// *************************************************************************** *
// *                                                                           *
// *                      Mentor Graphics Corporation                          *
// *                          All rights reserved                              *
// *                                                                           *
// *************************************************************************** *
// *                                                                           *
// * Description:         CANDB File                                           *
// * Generated at:        2020-12-11 06:44:08                                  *
// * System:              SDB20019                                             *
// * Variant:             DC1E                                                 *
// * Network:             BodyExposedCAN                                       *
// *                                                                           *
// *************************************************************************** *
// *                                                                           *
// *             THIS CONFIGURATION MIGHT CONTAIN SOME ERRORS                  *
// *              IF THE INPUT MODEL WAS NOT PROPERLY FORMED!                  *
// *                    Do Not Use this File directly!                         *
// *                                                                           *
// *************************************************************************** *
VERSION "BodyExposedCAN"

NS_ :

BS_:

BU_:  CEM ETC HCML HCMR RCML RCMM RCMR

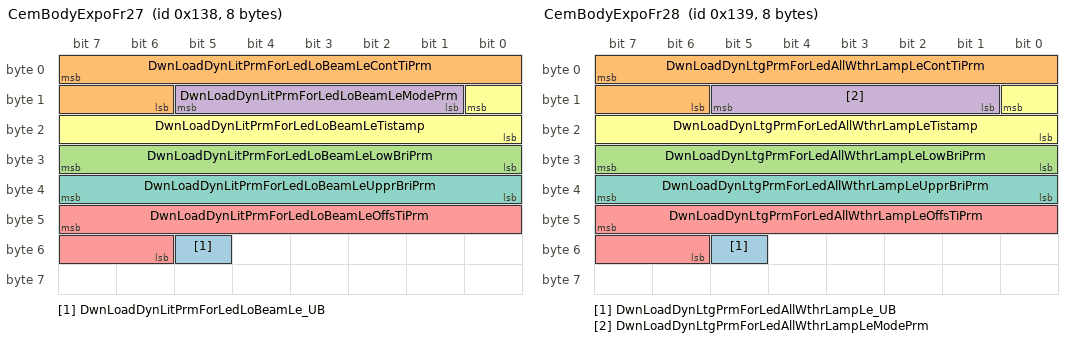
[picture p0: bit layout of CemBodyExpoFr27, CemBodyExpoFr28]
BO_ 312 CemBodyExpoFr27: 8 CEM
 SG_ DwnLoadDynLitPrmForLedLoBeamLe_UB : 53|1@0+ (1,0) [0|1] "" HCML
 SG_ DwnLoadDynLitPrmForLedLoBeamLeContTiPrm : 7|10@0+ (1.0,0.0) [0.0|1000.0] "Milliseconds" HCML
 SG_ DwnLoadDynLitPrmForLedLoBeamLeLowBriPrm : 31|8@0+ (1.0,0.0) [0.0|100.0] "%" HCML
 SG_ DwnLoadDynLitPrmForLedLoBeamLeModePrm : 13|5@0+ (1,0) [0|31] "" HCML
 SG_ DwnLoadDynLitPrmForLedLoBeamLeOffsTiPrm : 47|10@0+ (1.0,0.0) [0.0|1000.0] "Milliseconds" HCML
 SG_ DwnLoadDynLitPrmForLedLoBeamLeTistamp : 8|9@0+ (1.0,0.0) [0.0|511.0] "Unitless" HCML
 SG_ DwnLoadDynLitPrmForLedLoBeamLeUpprBriPrm : 39|8@0+ (1.0,0.0) [0.0|100.0] "%" HCML

BO_ 313 CemBodyExpoFr28: 8 CEM
 SG_ DwnLoadDynLtgPrmForLedAllWthrLampLe_UB : 53|1@0+ (1,0) [0|1] "" HCML
 SG_ DwnLoadDynLtgPrmForLedAllWthrLampLeContTiPrm : 7|10@0+ (1.0,0.0) [0.0|1000.0] "Milliseconds" HCML
 SG_ DwnLoadDynLtgPrmForLedAllWthrLampLeLowBriPrm : 31|8@0+ (1.0,0.0) [0.0|100.0] "%" HCML
 SG_ DwnLoadDynLtgPrmForLedAllWthrLampLeModePrm : 13|5@0+ (1,0) [0|31] "" HCML
 SG_ DwnLoadDynLtgPrmForLedAllWthrLampLeOffsTiPrm : 47|10@0+ (1.0,0.0) [0.0|1000.0] "Milliseconds" HCML
 SG_ DwnLoadDynLtgPrmForLedAllWthrLampLeTistamp : 8|9@0+ (1.0,0.0) [0.0|511.0] "Unitless" HCML
 SG_ DwnLoadDynLtgPrmForLedAllWthrLampLeUpprBriPrm : 39|8@0+ (1.0,0.0) [0.0|100.0] "%" HCML

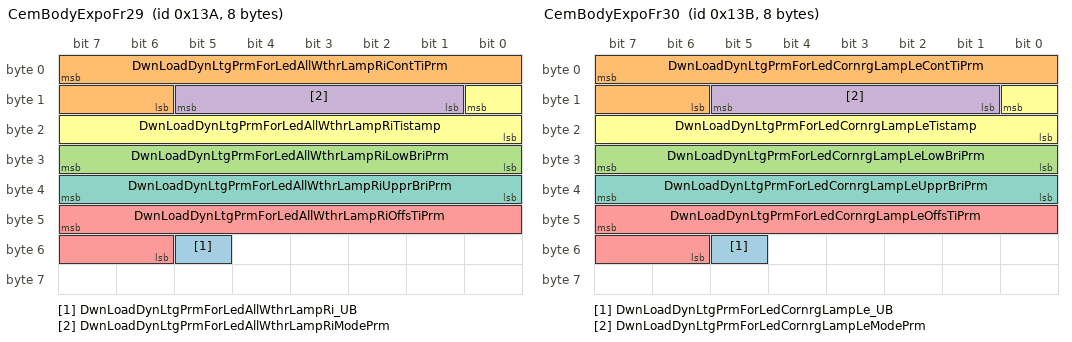
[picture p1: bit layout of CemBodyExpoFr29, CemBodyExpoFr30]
BO_ 314 CemBodyExpoFr29: 8 CEM
 SG_ DwnLoadDynLtgPrmForLedAllWthrLampRi_UB : 53|1@0+ (1,0) [0|1] "" HCMR
 SG_ DwnLoadDynLtgPrmForLedAllWthrLampRiContTiPrm : 7|10@0+ (1.0,0.0) [0.0|1000.0] "Milliseconds" HCMR
 SG_ DwnLoadDynLtgPrmForLedAllWthrLampRiLowBriPrm : 31|8@0+ (1.0,0.0) [0.0|100.0] "%" HCMR
 SG_ DwnLoadDynLtgPrmForLedAllWthrLampRiModePrm : 13|5@0+ (1,0) [0|31] "" HCMR
 SG_ DwnLoadDynLtgPrmForLedAllWthrLampRiOffsTiPrm : 47|10@0+ (1.0,0.0) [0.0|1000.0] "Milliseconds" HCMR
 SG_ DwnLoadDynLtgPrmForLedAllWthrLampRiTistamp : 8|9@0+ (1.0,0.0) [0.0|511.0] "Unitless" HCMR
 SG_ DwnLoadDynLtgPrmForLedAllWthrLampRiUpprBriPrm : 39|8@0+ (1.0,0.0) [0.0|100.0] "%" HCMR

BO_ 315 CemBodyExpoFr30: 8 CEM
 SG_ DwnLoadDynLtgPrmForLedCornrgLampLe_UB : 53|1@0+ (1,0) [0|1] "" HCML
 SG_ DwnLoadDynLtgPrmForLedCornrgLampLeContTiPrm : 7|10@0+ (1.0,0.0) [0.0|1000.0] "Milliseconds" HCML
 SG_ DwnLoadDynLtgPrmForLedCornrgLampLeLowBriPrm : 31|8@0+ (1.0,0.0) [0.0|100.0] "%" HCML
 SG_ DwnLoadDynLtgPrmForLedCornrgLampLeModePrm : 13|5@0+ (1,0) [0|31] "" HCML
 SG_ DwnLoadDynLtgPrmForLedCornrgLampLeOffsTiPrm : 47|10@0+ (1.0,0.0) [0.0|1000.0] "Milliseconds" HCML
 SG_ DwnLoadDynLtgPrmForLedCornrgLampLeTistamp : 8|9@0+ (1.0,0.0) [0.0|511.0] "Unitless" HCML
 SG_ DwnLoadDynLtgPrmForLedCornrgLampLeUpprBriPrm : 39|8@0+ (1.0,0.0) [0.0|100.0] "%" HCML

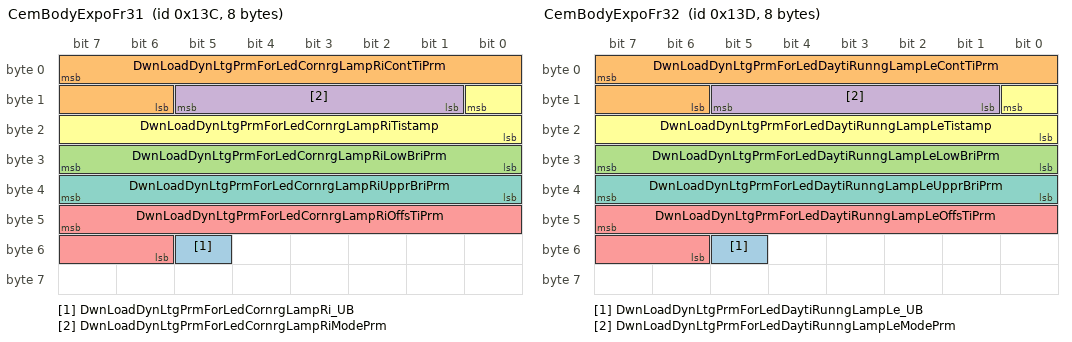
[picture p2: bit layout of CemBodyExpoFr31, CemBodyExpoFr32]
BO_ 316 CemBodyExpoFr31: 8 CEM
 SG_ DwnLoadDynLtgPrmForLedCornrgLampRi_UB : 53|1@0+ (1,0) [0|1] "" HCMR
 SG_ DwnLoadDynLtgPrmForLedCornrgLampRiContTiPrm : 7|10@0+ (1.0,0.0) [0.0|1000.0] "Milliseconds" HCMR
 SG_ DwnLoadDynLtgPrmForLedCornrgLampRiLowBriPrm : 31|8@0+ (1.0,0.0) [0.0|100.0] "%" HCMR
 SG_ DwnLoadDynLtgPrmForLedCornrgLampRiModePrm : 13|5@0+ (1,0) [0|31] "" HCMR
 SG_ DwnLoadDynLtgPrmForLedCornrgLampRiOffsTiPrm : 47|10@0+ (1.0,0.0) [0.0|1000.0] "Milliseconds" HCMR
 SG_ DwnLoadDynLtgPrmForLedCornrgLampRiTistamp : 8|9@0+ (1.0,0.0) [0.0|511.0] "Unitless" HCMR
 SG_ DwnLoadDynLtgPrmForLedCornrgLampRiUpprBriPrm : 39|8@0+ (1.0,0.0) [0.0|100.0] "%" HCMR

BO_ 317 CemBodyExpoFr32: 8 CEM
 SG_ DwnLoadDynLtgPrmForLedDaytiRunngLampLe_UB : 53|1@0+ (1,0) [0|1] "" HCML
 SG_ DwnLoadDynLtgPrmForLedDaytiRunngLampLeContTiPrm : 7|10@0+ (1.0,0.0) [0.0|1000.0] "Milliseconds" HCML
 SG_ DwnLoadDynLtgPrmForLedDaytiRunngLampLeLowBriPrm : 31|8@0+ (1.0,0.0) [0.0|100.0] "%" HCML
 SG_ DwnLoadDynLtgPrmForLedDaytiRunngLampLeModePrm : 13|5@0+ (1,0) [0|31] "" HCML
 SG_ DwnLoadDynLtgPrmForLedDaytiRunngLampLeOffsTiPrm : 47|10@0+ (1.0,0.0) [0.0|1000.0] "Milliseconds" HCML
 SG_ DwnLoadDynLtgPrmForLedDaytiRunngLampLeTistamp : 8|9@0+ (1.0,0.0) [0.0|511.0] "Unitless" HCML
 SG_ DwnLoadDynLtgPrmForLedDaytiRunngLampLeUpprBriPrm : 39|8@0+ (1.0,0.0) [0.0|100.0] "%" HCML

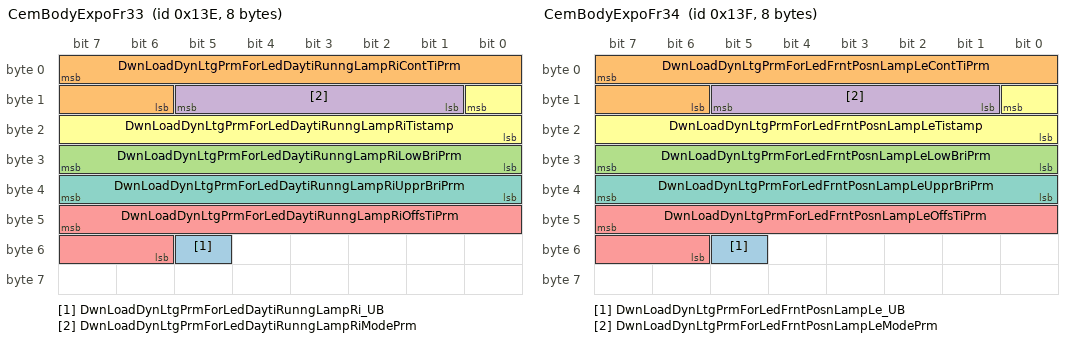
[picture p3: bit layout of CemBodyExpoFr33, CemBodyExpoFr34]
BO_ 318 CemBodyExpoFr33: 8 CEM
 SG_ DwnLoadDynLtgPrmForLedDaytiRunngLampRi_UB : 53|1@0+ (1,0) [0|1] "" HCMR
 SG_ DwnLoadDynLtgPrmForLedDaytiRunngLampRiContTiPrm : 7|10@0+ (1.0,0.0) [0.0|1000.0] "Milliseconds" HCMR
 SG_ DwnLoadDynLtgPrmForLedDaytiRunngLampRiLowBriPrm : 31|8@0+ (1.0,0.0) [0.0|100.0] "%" HCMR
 SG_ DwnLoadDynLtgPrmForLedDaytiRunngLampRiModePrm : 13|5@0+ (1,0) [0|31] "" HCMR
 SG_ DwnLoadDynLtgPrmForLedDaytiRunngLampRiOffsTiPrm : 47|10@0+ (1.0,0.0) [0.0|1000.0] "Milliseconds" HCMR
 SG_ DwnLoadDynLtgPrmForLedDaytiRunngLampRiTistamp : 8|9@0+ (1.0,0.0) [0.0|511.0] "Unitless" HCMR
 SG_ DwnLoadDynLtgPrmForLedDaytiRunngLampRiUpprBriPrm : 39|8@0+ (1.0,0.0) [0.0|100.0] "%" HCMR

BO_ 319 CemBodyExpoFr34: 8 CEM
 SG_ DwnLoadDynLtgPrmForLedFrntPosnLampLe_UB : 53|1@0+ (1,0) [0|1] "" HCML
 SG_ DwnLoadDynLtgPrmForLedFrntPosnLampLeContTiPrm : 7|10@0+ (1.0,0.0) [0.0|1000.0] "Milliseconds" HCML
 SG_ DwnLoadDynLtgPrmForLedFrntPosnLampLeLowBriPrm : 31|8@0+ (1.0,0.0) [0.0|100.0] "%" HCML
 SG_ DwnLoadDynLtgPrmForLedFrntPosnLampLeModePrm : 13|5@0+ (1,0) [0|31] "" HCML
 SG_ DwnLoadDynLtgPrmForLedFrntPosnLampLeOffsTiPrm : 47|10@0+ (1.0,0.0) [0.0|1000.0] "Milliseconds" HCML
 SG_ DwnLoadDynLtgPrmForLedFrntPosnLampLeTistamp : 8|9@0+ (1.0,0.0) [0.0|511.0] "Unitless" HCML
 SG_ DwnLoadDynLtgPrmForLedFrntPosnLampLeUpprBriPrm : 39|8@0+ (1.0,0.0) [0.0|100.0] "%" HCML

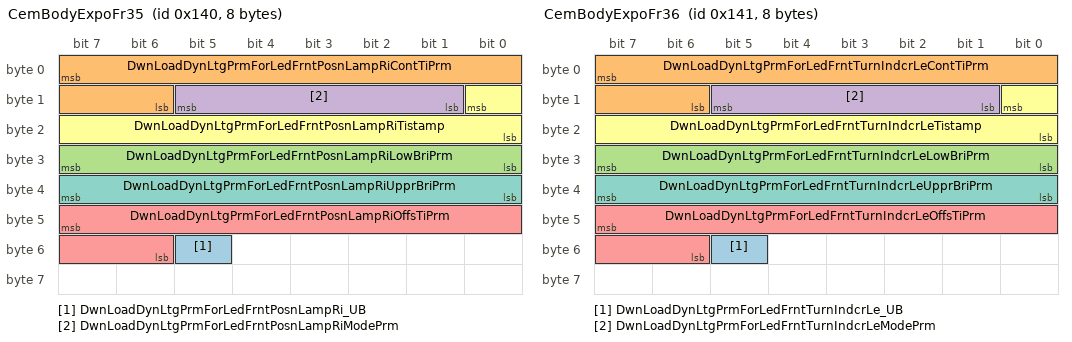
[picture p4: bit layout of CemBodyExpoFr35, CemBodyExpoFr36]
BO_ 320 CemBodyExpoFr35: 8 CEM
 SG_ DwnLoadDynLtgPrmForLedFrntPosnLampRi_UB : 53|1@0+ (1,0) [0|1] "" HCMR
 SG_ DwnLoadDynLtgPrmForLedFrntPosnLampRiContTiPrm : 7|10@0+ (1.0,0.0) [0.0|1000.0] "Milliseconds" HCMR
 SG_ DwnLoadDynLtgPrmForLedFrntPosnLampRiLowBriPrm : 31|8@0+ (1.0,0.0) [0.0|100.0] "%" HCMR
 SG_ DwnLoadDynLtgPrmForLedFrntPosnLampRiModePrm : 13|5@0+ (1,0) [0|31] "" HCMR
 SG_ DwnLoadDynLtgPrmForLedFrntPosnLampRiOffsTiPrm : 47|10@0+ (1.0,0.0) [0.0|1000.0] "Milliseconds" HCMR
 SG_ DwnLoadDynLtgPrmForLedFrntPosnLampRiTistamp : 8|9@0+ (1.0,0.0) [0.0|511.0] "Unitless" HCMR
 SG_ DwnLoadDynLtgPrmForLedFrntPosnLampRiUpprBriPrm : 39|8@0+ (1.0,0.0) [0.0|100.0] "%" HCMR

BO_ 321 CemBodyExpoFr36: 8 CEM
 SG_ DwnLoadDynLtgPrmForLedFrntTurnIndcrLe_UB : 53|1@0+ (1,0) [0|1] "" HCML
 SG_ DwnLoadDynLtgPrmForLedFrntTurnIndcrLeContTiPrm : 7|10@0+ (1.0,0.0) [0.0|1000.0] "Milliseconds" HCML
 SG_ DwnLoadDynLtgPrmForLedFrntTurnIndcrLeLowBriPrm : 31|8@0+ (1.0,0.0) [0.0|100.0] "%" HCML
 SG_ DwnLoadDynLtgPrmForLedFrntTurnIndcrLeModePrm : 13|5@0+ (1,0) [0|31] "" HCML
 SG_ DwnLoadDynLtgPrmForLedFrntTurnIndcrLeOffsTiPrm : 47|10@0+ (1.0,0.0) [0.0|1000.0] "Milliseconds" HCML
 SG_ DwnLoadDynLtgPrmForLedFrntTurnIndcrLeTistamp : 8|9@0+ (1.0,0.0) [0.0|511.0] "Unitless" HCML
 SG_ DwnLoadDynLtgPrmForLedFrntTurnIndcrLeUpprBriPrm : 39|8@0+ (1.0,0.0) [0.0|100.0] "%" HCML

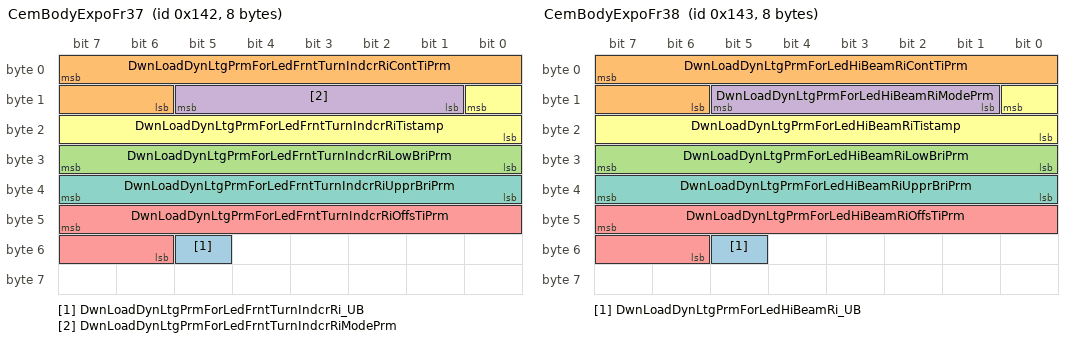
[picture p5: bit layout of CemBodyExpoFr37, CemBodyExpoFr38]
BO_ 322 CemBodyExpoFr37: 8 CEM
 SG_ DwnLoadDynLtgPrmForLedFrntTurnIndcrRi_UB : 53|1@0+ (1,0) [0|1] "" HCMR
 SG_ DwnLoadDynLtgPrmForLedFrntTurnIndcrRiContTiPrm : 7|10@0+ (1.0,0.0) [0.0|1000.0] "Milliseconds" HCMR
 SG_ DwnLoadDynLtgPrmForLedFrntTurnIndcrRiLowBriPrm : 31|8@0+ (1.0,0.0) [0.0|100.0] "%" HCMR
 SG_ DwnLoadDynLtgPrmForLedFrntTurnIndcrRiModePrm : 13|5@0+ (1,0) [0|31] "" HCMR
 SG_ DwnLoadDynLtgPrmForLedFrntTurnIndcrRiOffsTiPrm : 47|10@0+ (1.0,0.0) [0.0|1000.0] "Milliseconds" HCMR
 SG_ DwnLoadDynLtgPrmForLedFrntTurnIndcrRiTistamp : 8|9@0+ (1.0,0.0) [0.0|511.0] "Unitless" HCMR
 SG_ DwnLoadDynLtgPrmForLedFrntTurnIndcrRiUpprBriPrm : 39|8@0+ (1.0,0.0) [0.0|100.0] "%" HCMR

BO_ 323 CemBodyExpoFr38: 8 CEM
 SG_ DwnLoadDynLtgPrmForLedHiBeamRi_UB : 53|1@0+ (1,0) [0|1] "" HCMR
 SG_ DwnLoadDynLtgPrmForLedHiBeamRiContTiPrm : 7|10@0+ (1.0,0.0) [0.0|1000.0] "Milliseconds" HCMR
 SG_ DwnLoadDynLtgPrmForLedHiBeamRiLowBriPrm : 31|8@0+ (1.0,0.0) [0.0|100.0] "%" HCMR
 SG_ DwnLoadDynLtgPrmForLedHiBeamRiModePrm : 13|5@0+ (1,0) [0|31] "" HCMR
 SG_ DwnLoadDynLtgPrmForLedHiBeamRiOffsTiPrm : 47|10@0+ (1.0,0.0) [0.0|1000.0] "Milliseconds" HCMR
 SG_ DwnLoadDynLtgPrmForLedHiBeamRiTistamp : 8|9@0+ (1.0,0.0) [0.0|511.0] "Unitless" HCMR
 SG_ DwnLoadDynLtgPrmForLedHiBeamRiUpprBriPrm : 39|8@0+ (1.0,0.0) [0.0|100.0] "%" HCMR

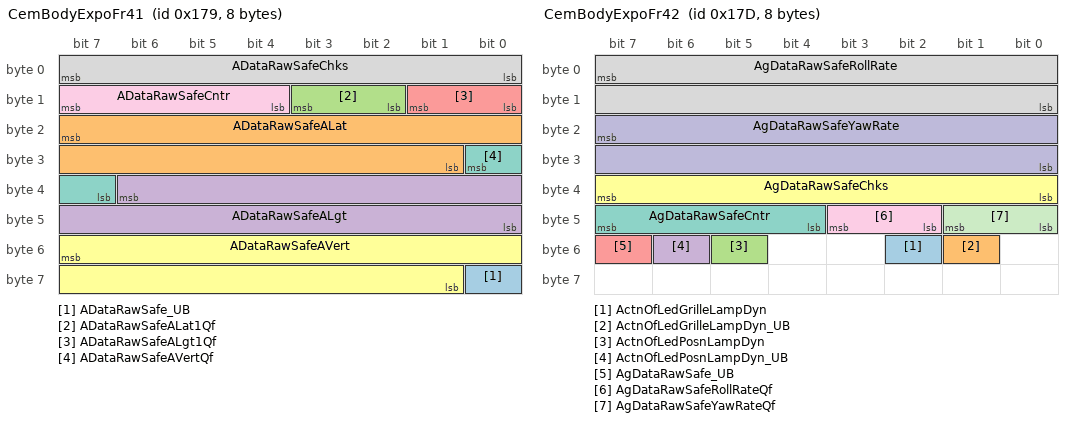
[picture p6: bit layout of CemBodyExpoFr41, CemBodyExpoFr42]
BO_ 377 CemBodyExpoFr41: 8 CEM
 SG_ ADataRawSafe_UB : 56|1@0+ (1,0) [0|1] "" HCML,HCMR
 SG_ ADataRawSafeALat : 23|15@0- (0.0085,0.0) [-138.99200000000002|139.00050000000002] "m/s^2" HCML,HCMR
 SG_ ADataRawSafeALat1Qf : 11|2@0+ (1,0) [0|3] "" HCML,HCMR
 SG_ ADataRawSafeALgt : 38|15@0- (0.0085,0.0) [-138.99200000000002|139.00050000000002] "m/s^2" HCML,HCMR
 SG_ ADataRawSafeALgt1Qf : 9|2@0+ (1,0) [0|3] "" HCML,HCMR
 SG_ ADataRawSafeAVert : 55|15@0- (0.0085,0.0) [-138.99200000000002|139.00050000000002] "m/s^2" HCML,HCMR
 SG_ ADataRawSafeAVertQf : 24|2@0+ (1,0) [0|3] "" HCML,HCMR
 SG_ ADataRawSafeChks : 7|8@0+ (1.0,0.0) [0.0|255.0] "Unitless" HCML,HCMR
 SG_ ADataRawSafeCntr : 15|4@0+ (1.0,0.0) [0.0|15.0] "Unitless" HCML,HCMR

BO_ 381 CemBodyExpoFr42: 8 CEM
 SG_ ActnOfLedGrilleLampDyn : 50|1@0+ (1,0) [0|1] "" HCML,HCMR
 SG_ ActnOfLedGrilleLampDyn_UB : 49|1@0+ (1,0) [0|1] "" HCML,HCMR
 SG_ ActnOfLedPosnLampDyn : 53|1@0+ (1,0) [0|1] "" HCML,HCMR
 SG_ ActnOfLedPosnLampDyn_UB : 54|1@0+ (1,0) [0|1] "" HCML,HCMR
 SG_ AgDataRawSafe_UB : 55|1@0+ (1,0) [0|1] "" HCML,HCMR
 SG_ AgDataRawSafeChks : 39|8@0+ (1.0,0.0) [0.0|255.0] "Unitless" HCML,HCMR
 SG_ AgDataRawSafeCntr : 47|4@0+ (1.0,0.0) [0.0|15.0] "Unitless" HCML,HCMR
 SG_ AgDataRawSafeRollRate : 7|16@0- (0.000244140625,0.0) [-6.0|6.0] "rad/s" HCML,HCMR
 SG_ AgDataRawSafeRollRateQf : 43|2@0+ (1,0) [0|3] "" HCML,HCMR
 SG_ AgDataRawSafeYawRate : 23|16@0- (0.000244140625,0.0) [-6.0|6.0] "rad/s" HCML,HCMR
 SG_ AgDataRawSafeYawRateQf : 41|2@0+ (1,0) [0|3] "" HCML,HCMR

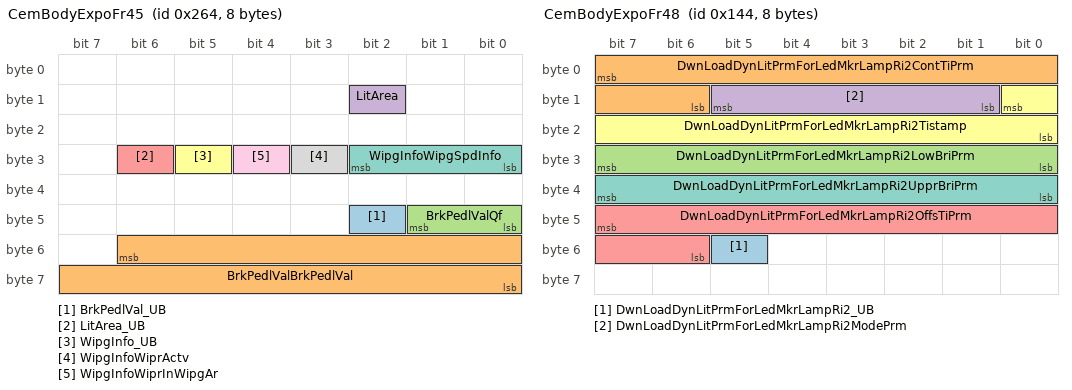
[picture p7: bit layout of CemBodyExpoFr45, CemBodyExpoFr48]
BO_ 612 CemBodyExpoFr45: 8 CEM
 SG_ BrkPedlVal_UB : 42|1@0+ (1,0) [0|1] "" HCML,HCMR
 SG_ BrkPedlValBrkPedlVal : 54|15@0+ (0.00390625,0.0) [0.0|100.0] "%" HCML,HCMR
 SG_ BrkPedlValQf : 41|2@0+ (1,0) [0|3] "" HCML,HCMR
 SG_ LitArea : 10|1@0+ (1,0) [0|1] "" HCML,HCMR
 SG_ LitArea_UB : 30|1@0+ (1,0) [0|1] "" HCML,HCMR
 SG_ WipgInfo_UB : 29|1@0+ (1,0) [0|1] "" HCML,HCMR
 SG_ WipgInfoWipgSpdInfo : 26|3@0+ (1,0) [0|7] "" HCML,HCMR
 SG_ WipgInfoWiprActv : 27|1@0+ (1,0) [0|1] "" HCML,HCMR
 SG_ WipgInfoWiprInWipgAr : 28|1@0+ (1,0) [0|1] "" HCML,HCMR

BO_ 324 CemBodyExpoFr48: 8 CEM
 SG_ DwnLoadDynLitPrmForLedMkrLampRi2_UB : 53|1@0+ (1,0) [0|1] "" RCMM
 SG_ DwnLoadDynLitPrmForLedMkrLampRi2ContTiPrm : 7|10@0+ (1.0,0.0) [0.0|1000.0] "Milliseconds" RCMM
 SG_ DwnLoadDynLitPrmForLedMkrLampRi2LowBriPrm : 31|8@0+ (1.0,0.0) [0.0|100.0] "%" RCMM
 SG_ DwnLoadDynLitPrmForLedMkrLampRi2ModePrm : 13|5@0+ (1,0) [0|31] "" RCMM
 SG_ DwnLoadDynLitPrmForLedMkrLampRi2OffsTiPrm : 47|10@0+ (1.0,0.0) [0.0|1000.0] "Milliseconds" RCMM
 SG_ DwnLoadDynLitPrmForLedMkrLampRi2Tistamp : 8|9@0+ (1.0,0.0) [0.0|511.0] "Unitless" RCMM
 SG_ DwnLoadDynLitPrmForLedMkrLampRi2UpprBriPrm : 39|8@0+ (1.0,0.0) [0.0|100.0] "%" RCMM

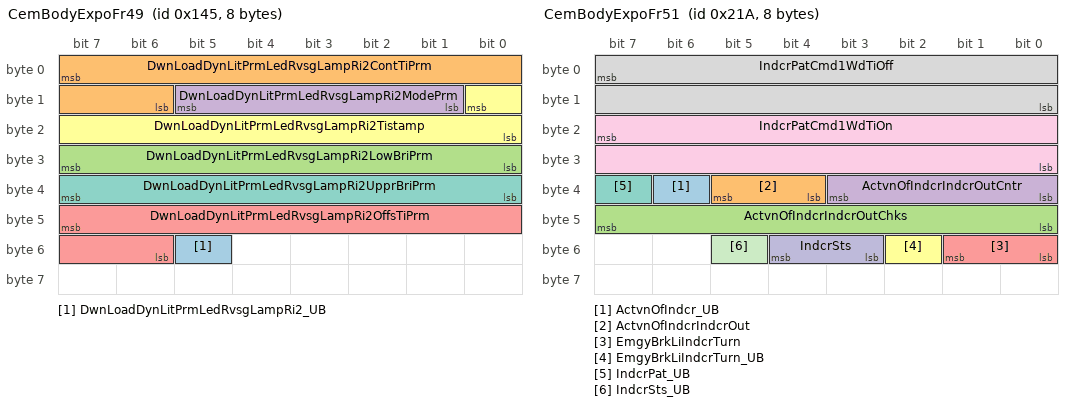
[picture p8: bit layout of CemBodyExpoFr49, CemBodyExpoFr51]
BO_ 325 CemBodyExpoFr49: 8 CEM
 SG_ DwnLoadDynLitPrmLedRvsgLampRi2_UB : 53|1@0+ (1,0) [0|1] "" RCMM
 SG_ DwnLoadDynLitPrmLedRvsgLampRi2ContTiPrm : 7|10@0+ (1.0,0.0) [0.0|1000.0] "Milliseconds" RCMM
 SG_ DwnLoadDynLitPrmLedRvsgLampRi2LowBriPrm : 31|8@0+ (1.0,0.0) [0.0|100.0] "%" RCMM
 SG_ DwnLoadDynLitPrmLedRvsgLampRi2ModePrm : 13|5@0+ (1,0) [0|31] "" RCMM
 SG_ DwnLoadDynLitPrmLedRvsgLampRi2OffsTiPrm : 47|10@0+ (1.0,0.0) [0.0|1000.0] "Milliseconds" RCMM
 SG_ DwnLoadDynLitPrmLedRvsgLampRi2Tistamp : 8|9@0+ (1.0,0.0) [0.0|511.0] "Unitless" RCMM
 SG_ DwnLoadDynLitPrmLedRvsgLampRi2UpprBriPrm : 39|8@0+ (1.0,0.0) [0.0|100.0] "%" RCMM

BO_ 522 CemBodyExpoFr50: 8 CEM
 SG_ ActnOfLedCornrgLampLe : 6|1@0+ (1,0) [0|1] "" HCML
 SG_ ActnOfLedCornrgLampLe_UB : 7|1@0+ (1,0) [0|1] "" HCML
 SG_ ActnOfLedCornrgLampRi : 22|1@0+ (1,0) [0|1] "" HCMR
 SG_ ActnOfLedCornrgLampRi_UB : 23|1@0+ (1,0) [0|1] "" HCMR
 SG_ ActnOfLedDaytiRunngLamp : 32|1@0+ (1,0) [0|1] "" HCML,HCMR
 SG_ ActnOfLedDaytiRunngLamp_UB : 33|1@0+ (1,0) [0|1] "" HCML,HCMR
 SG_ ActnOfLedFrntFogLamp : 34|1@0+ (1,0) [0|1] "" HCML,HCMR
 SG_ ActnOfLedFrntFogLamp_UB : 35|1@0+ (1,0) [0|1] "" HCML,HCMR
 SG_ ActnOfLedHiBeam : 36|1@0+ (1,0) [0|1] "" HCML,HCMR
 SG_ ActnOfLedHiBeam_UB : 37|1@0+ (1,0) [0|1] "" HCML,HCMR
 SG_ ActnOfLedLoBeam_UB : 5|1@0+ (1,0) [0|1] "" HCML,HCMR
 SG_ ActnOfLedLoBeamActnOfLedLoBeam : 4|1@0+ (1,0) [0|1] "" HCML,HCMR
 SG_ ActnOfLedLoBeamChks : 15|8@0+ (1.0,0.0) [0.0|255.0] "Unitless" HCML,HCMR
 SG_ ActnOfLedLoBeamCntr : 3|4@0+ (1.0,0.0) [0.0|15.0] "Unitless" HCML,HCMR
 SG_ ActnOfLedPosnLamp : 38|1@0+ (1,0) [0|1] "" HCML,HCMR,RCML,RCMM,RCMR
 SG_ ActnOfLedPosnLamp_UB : 39|1@0+ (1,0) [0|1] "" HCML,HCMR,RCML,RCMM,RCMR
 SG_ ActnOfLedReFogLamp : 40|1@0+ (1,0) [0|1] "" RCML,RCMM,RCMR
 SG_ ActnOfLedReFogLamp_UB : 41|1@0+ (1,0) [0|1] "" RCML,RCMM,RCMR
 SG_ ActnOfLedRvsgLamp : 42|1@0+ (1,0) [0|1] "" RCML,RCMM,RCMR
 SG_ ActnOfLedRvsgLamp_UB : 43|1@0+ (1,0) [0|1] "" RCML,RCMM,RCMR
 SG_ ActnOfLedStopLamp_UB : 21|1@0+ (1,0) [0|1] "" RCML,RCMM,RCMR
 SG_ ActnOfLedStopLampActnOfLedStopLamp : 20|1@0+ (1,0) [0|1] "" RCML,RCMM,RCMR
 SG_ ActnOfLedStopLampChks : 31|8@0+ (1.0,0.0) [0.0|255.0] "Unitless" RCML,RCMM,RCMR
 SG_ ActnOfLedStopLampCntr : 19|4@0+ (1.0,0.0) [0.0|15.0] "Unitless" RCML,RCMM,RCMR
 SG_ ActvnOfAfs : 44|1@0+ (1,0) [0|1] "" HCML,HCMR
 SG_ ActvnOfAfs_UB : 45|1@0+ (1,0) [0|1] "" HCML,HCMR
 SG_ ActvnOfAhbc : 46|1@0+ (1,0) [0|1] "" HCML,HCMR
 SG_ ActvnOfAhbc_UB : 47|1@0+ (1,0) [0|1] "" HCML,HCMR
 SG_ ActvnOfAhl : 48|1@0+ (1,0) [0|1] "" HCML,HCMR
 SG_ ActvnOfAhl_UB : 49|1@0+ (1,0) [0|1] "" HCML,HCMR
 SG_ ActvnOfBrkLi : 50|1@0+ (1,0) [0|1] "" RCML,RCMR
 SG_ ActvnOfBrkLi_UB : 51|1@0+ (1,0) [0|1] "" RCML,RCMR
 SG_ ActvnOfDbl : 52|1@0+ (1,0) [0|1] "" HCML,HCMR
 SG_ ActvnOfDbl_UB : 53|1@0+ (1,0) [0|1] "" HCML,HCMR
 SG_ ActvnOfGoodByeLi : 54|1@0+ (1,0) [0|1] "" HCML,HCMR,RCML,RCMM,RCMR
 SG_ ActvnOfGoodByeLi_UB : 55|1@0+ (1,0) [0|1] "" HCML,HCMR,RCML,RCMM,RCMR
 SG_ ActvnOfTouristMod : 56|1@0+ (1,0) [0|1] "" HCML,HCMR
 SG_ ActvnOfTouristMod_UB : 57|1@0+ (1,0) [0|1] "" HCML,HCMR
 SG_ ActvnOfWelcomeLi : 58|1@0+ (1,0) [0|1] "" HCML,HCMR,RCML,RCMM,RCMR
 SG_ ActvnOfWelcomeLi_UB : 59|1@0+ (1,0) [0|1] "" HCML,HCMR,RCML,RCMM,RCMR

BO_ 538 CemBodyExpoFr51: 8 CEM
 SG_ ActvnOfIndcr_UB : 38|1@0+ (1,0) [0|1] "" HCML,HCMR,RCML,RCMM,RCMR
 SG_ ActvnOfIndcrIndcrOut : 37|2@0+ (1,0) [0|3] "" HCML,HCMR,RCML,RCMM,RCMR
 SG_ ActvnOfIndcrIndcrOutChks : 47|8@0+ (1.0,0.0) [0.0|255.0] "Unitless" HCML,HCMR,RCML,RCMM,RCMR
 SG_ ActvnOfIndcrIndcrOutCntr : 35|4@0+ (1.0,0.0) [0.0|15.0] "Unitless" HCML,HCMR,RCML,RCMM,RCMR
 SG_ EmgyBrkLiIndcrTurn : 49|2@0+ (1,0) [0|3] "" RCML,RCMM,RCMR
 SG_ EmgyBrkLiIndcrTurn_UB : 50|1@0+ (1,0) [0|1] "" RCML,RCMM,RCMR
 SG_ IndcrPat_UB : 39|1@0+ (1,0) [0|1] "" HCML,HCMR,RCML,RCMM,RCMR
 SG_ IndcrPatCmd1WdTiOff : 7|16@0+ (0.001,0.0) [0.0|65.535] "s" HCML,HCMR,RCML,RCMM,RCMR
 SG_ IndcrPatCmd1WdTiOn : 23|16@0+ (0.001,0.0) [0.0|65.535] "s" HCML,HCMR,RCML,RCMM,RCMR
 SG_ IndcrSts : 52|2@0+ (1,0) [0|3] "" HCML,HCMR,RCML,RCMM,RCMR
 SG_ IndcrSts_UB : 53|1@0+ (1,0) [0|1] "" HCML,HCMR,RCML,RCMM,RCMR

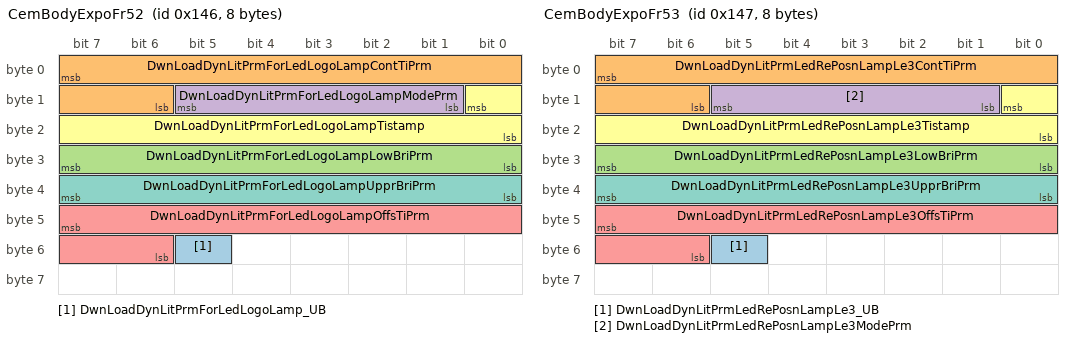
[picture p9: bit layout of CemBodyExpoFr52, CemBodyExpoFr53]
BO_ 326 CemBodyExpoFr52: 8 CEM
 SG_ DwnLoadDynLitPrmForLedLogoLamp_UB : 53|1@0+ (1,0) [0|1] "" RCMM
 SG_ DwnLoadDynLitPrmForLedLogoLampContTiPrm : 7|10@0+ (1.0,0.0) [0.0|1000.0] "Milliseconds" RCMM
 SG_ DwnLoadDynLitPrmForLedLogoLampLowBriPrm : 31|8@0+ (1.0,0.0) [0.0|100.0] "%" RCMM
 SG_ DwnLoadDynLitPrmForLedLogoLampModePrm : 13|5@0+ (1,0) [0|31] "" RCMM
 SG_ DwnLoadDynLitPrmForLedLogoLampOffsTiPrm : 47|10@0+ (1.0,0.0) [0.0|1000.0] "Milliseconds" RCMM
 SG_ DwnLoadDynLitPrmForLedLogoLampTistamp : 8|9@0+ (1.0,0.0) [0.0|511.0] "Unitless" RCMM
 SG_ DwnLoadDynLitPrmForLedLogoLampUpprBriPrm : 39|8@0+ (1.0,0.0) [0.0|100.0] "%" RCMM

BO_ 327 CemBodyExpoFr53: 8 CEM
 SG_ DwnLoadDynLitPrmLedRePosnLampLe3_UB : 53|1@0+ (1,0) [0|1] "" RCML
 SG_ DwnLoadDynLitPrmLedRePosnLampLe3ContTiPrm : 7|10@0+ (1.0,0.0) [0.0|1000.0] "Milliseconds" RCML
 SG_ DwnLoadDynLitPrmLedRePosnLampLe3LowBriPrm : 31|8@0+ (1.0,0.0) [0.0|100.0] "%" RCML
 SG_ DwnLoadDynLitPrmLedRePosnLampLe3ModePrm : 13|5@0+ (1,0) [0|31] "" RCML
 SG_ DwnLoadDynLitPrmLedRePosnLampLe3OffsTiPrm : 47|10@0+ (1.0,0.0) [0.0|1000.0] "Milliseconds" RCML
 SG_ DwnLoadDynLitPrmLedRePosnLampLe3Tistamp : 8|9@0+ (1.0,0.0) [0.0|511.0] "Unitless" RCML
 SG_ DwnLoadDynLitPrmLedRePosnLampLe3UpprBriPrm : 39|8@0+ (1.0,0.0) [0.0|100.0] "%" RCML

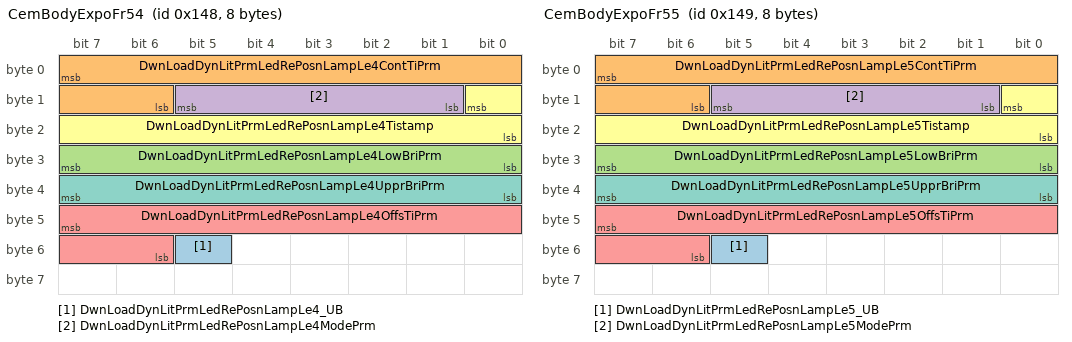
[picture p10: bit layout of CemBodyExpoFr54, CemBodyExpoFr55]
BO_ 328 CemBodyExpoFr54: 8 CEM
 SG_ DwnLoadDynLitPrmLedRePosnLampLe4_UB : 53|1@0+ (1,0) [0|1] "" RCML
 SG_ DwnLoadDynLitPrmLedRePosnLampLe4ContTiPrm : 7|10@0+ (1.0,0.0) [0.0|1000.0] "Milliseconds" RCML
 SG_ DwnLoadDynLitPrmLedRePosnLampLe4LowBriPrm : 31|8@0+ (1.0,0.0) [0.0|100.0] "%" RCML
 SG_ DwnLoadDynLitPrmLedRePosnLampLe4ModePrm : 13|5@0+ (1,0) [0|31] "" RCML
 SG_ DwnLoadDynLitPrmLedRePosnLampLe4OffsTiPrm : 47|10@0+ (1.0,0.0) [0.0|1000.0] "Milliseconds" RCML
 SG_ DwnLoadDynLitPrmLedRePosnLampLe4Tistamp : 8|9@0+ (1.0,0.0) [0.0|511.0] "Unitless" RCML
 SG_ DwnLoadDynLitPrmLedRePosnLampLe4UpprBriPrm : 39|8@0+ (1.0,0.0) [0.0|100.0] "%" RCML

BO_ 329 CemBodyExpoFr55: 8 CEM
 SG_ DwnLoadDynLitPrmLedRePosnLampLe5_UB : 53|1@0+ (1,0) [0|1] "" RCMM
 SG_ DwnLoadDynLitPrmLedRePosnLampLe5ContTiPrm : 7|10@0+ (1.0,0.0) [0.0|1000.0] "Milliseconds" RCMM
 SG_ DwnLoadDynLitPrmLedRePosnLampLe5LowBriPrm : 31|8@0+ (1.0,0.0) [0.0|100.0] "%" RCMM
 SG_ DwnLoadDynLitPrmLedRePosnLampLe5ModePrm : 13|5@0+ (1,0) [0|31] "" RCMM
 SG_ DwnLoadDynLitPrmLedRePosnLampLe5OffsTiPrm : 47|10@0+ (1.0,0.0) [0.0|1000.0] "Milliseconds" RCMM
 SG_ DwnLoadDynLitPrmLedRePosnLampLe5Tistamp : 8|9@0+ (1.0,0.0) [0.0|511.0] "Unitless" RCMM
 SG_ DwnLoadDynLitPrmLedRePosnLampLe5UpprBriPrm : 39|8@0+ (1.0,0.0) [0.0|100.0] "%" RCMM

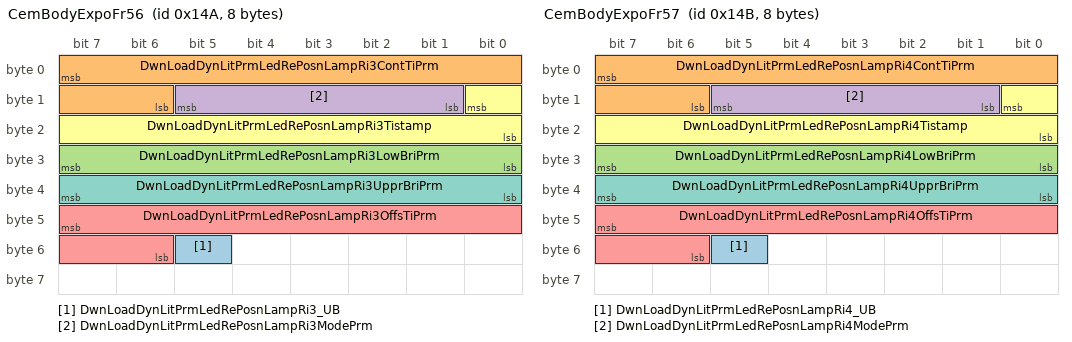
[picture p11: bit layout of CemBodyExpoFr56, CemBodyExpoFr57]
BO_ 330 CemBodyExpoFr56: 8 CEM
 SG_ DwnLoadDynLitPrmLedRePosnLampRi3_UB : 53|1@0+ (1,0) [0|1] "" RCMR
 SG_ DwnLoadDynLitPrmLedRePosnLampRi3ContTiPrm : 7|10@0+ (1.0,0.0) [0.0|1000.0] "Milliseconds" RCMR
 SG_ DwnLoadDynLitPrmLedRePosnLampRi3LowBriPrm : 31|8@0+ (1.0,0.0) [0.0|100.0] "%" RCMR
 SG_ DwnLoadDynLitPrmLedRePosnLampRi3ModePrm : 13|5@0+ (1,0) [0|31] "" RCMR
 SG_ DwnLoadDynLitPrmLedRePosnLampRi3OffsTiPrm : 47|10@0+ (1.0,0.0) [0.0|1000.0] "Milliseconds" RCMR
 SG_ DwnLoadDynLitPrmLedRePosnLampRi3Tistamp : 8|9@0+ (1.0,0.0) [0.0|511.0] "Unitless" RCMR
 SG_ DwnLoadDynLitPrmLedRePosnLampRi3UpprBriPrm : 39|8@0+ (1.0,0.0) [0.0|100.0] "%" RCMR

BO_ 331 CemBodyExpoFr57: 8 CEM
 SG_ DwnLoadDynLitPrmLedRePosnLampRi4_UB : 53|1@0+ (1,0) [0|1] "" RCMR
 SG_ DwnLoadDynLitPrmLedRePosnLampRi4ContTiPrm : 7|10@0+ (1.0,0.0) [0.0|1000.0] "Milliseconds" RCMR
 SG_ DwnLoadDynLitPrmLedRePosnLampRi4LowBriPrm : 31|8@0+ (1.0,0.0) [0.0|100.0] "%" RCMR
 SG_ DwnLoadDynLitPrmLedRePosnLampRi4ModePrm : 13|5@0+ (1,0) [0|31] "" RCMR
 SG_ DwnLoadDynLitPrmLedRePosnLampRi4OffsTiPrm : 47|10@0+ (1.0,0.0) [0.0|1000.0] "Milliseconds" RCMR
 SG_ DwnLoadDynLitPrmLedRePosnLampRi4Tistamp : 8|9@0+ (1.0,0.0) [0.0|511.0] "Unitless" RCMR
 SG_ DwnLoadDynLitPrmLedRePosnLampRi4UpprBriPrm : 39|8@0+ (1.0,0.0) [0.0|100.0] "%" RCMR

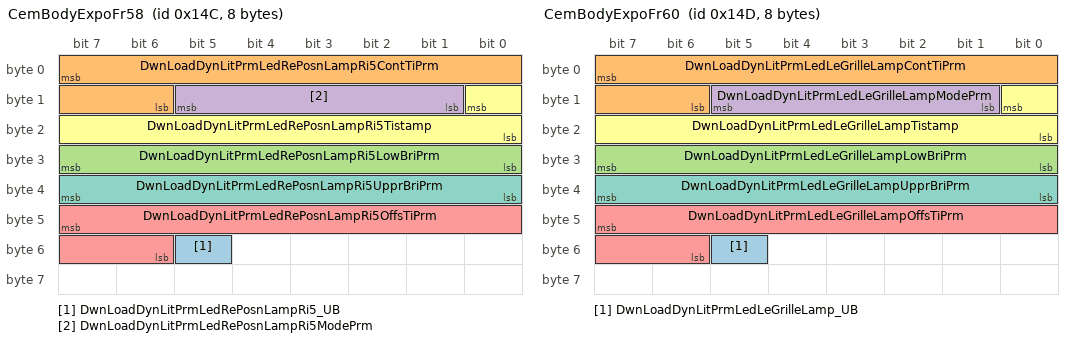
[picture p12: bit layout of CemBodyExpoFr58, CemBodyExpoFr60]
BO_ 332 CemBodyExpoFr58: 8 CEM
 SG_ DwnLoadDynLitPrmLedRePosnLampRi5_UB : 53|1@0+ (1,0) [0|1] "" RCMM
 SG_ DwnLoadDynLitPrmLedRePosnLampRi5ContTiPrm : 7|10@0+ (1.0,0.0) [0.0|1000.0] "Milliseconds" RCMM
 SG_ DwnLoadDynLitPrmLedRePosnLampRi5LowBriPrm : 31|8@0+ (1.0,0.0) [0.0|100.0] "%" RCMM
 SG_ DwnLoadDynLitPrmLedRePosnLampRi5ModePrm : 13|5@0+ (1,0) [0|31] "" RCMM
 SG_ DwnLoadDynLitPrmLedRePosnLampRi5OffsTiPrm : 47|10@0+ (1.0,0.0) [0.0|1000.0] "Milliseconds" RCMM
 SG_ DwnLoadDynLitPrmLedRePosnLampRi5Tistamp : 8|9@0+ (1.0,0.0) [0.0|511.0] "Unitless" RCMM
 SG_ DwnLoadDynLitPrmLedRePosnLampRi5UpprBriPrm : 39|8@0+ (1.0,0.0) [0.0|100.0] "%" RCMM

BO_ 24 CemBodyExpoFr59: 8 CEM
 SG_ WelcomeGoodbyeModeReq : 7|4@0+ (1,0) [0|15] "" HCML,HCMR
 SG_ WelcomeGoodbyeModeReq_UB : 3|1@0+ (1,0) [0|1] "" HCML,HCMR

BO_ 333 CemBodyExpoFr60: 8 CEM
 SG_ DwnLoadDynLitPrmLedLeGrilleLamp_UB : 53|1@0+ (1,0) [0|1] "" HCML
 SG_ DwnLoadDynLitPrmLedLeGrilleLampContTiPrm : 7|10@0+ (1.0,0.0) [0.0|1000.0] "Milliseconds" HCML
 SG_ DwnLoadDynLitPrmLedLeGrilleLampLowBriPrm : 31|8@0+ (1.0,0.0) [0.0|100.0] "%" HCML
 SG_ DwnLoadDynLitPrmLedLeGrilleLampModePrm : 13|5@0+ (1,0) [0|31] "" HCML
 SG_ DwnLoadDynLitPrmLedLeGrilleLampOffsTiPrm : 47|10@0+ (1.0,0.0) [0.0|1000.0] "Milliseconds" HCML
 SG_ DwnLoadDynLitPrmLedLeGrilleLampTistamp : 8|9@0+ (1.0,0.0) [0.0|511.0] "Unitless" HCML
 SG_ DwnLoadDynLitPrmLedLeGrilleLampUpprBriPrm : 39|8@0+ (1.0,0.0) [0.0|100.0] "%" HCML

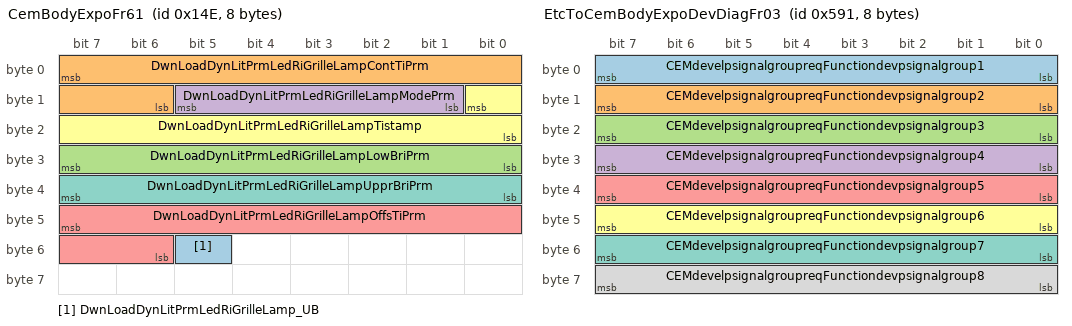
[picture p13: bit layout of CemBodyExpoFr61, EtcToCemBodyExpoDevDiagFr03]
BO_ 334 CemBodyExpoFr61: 8 CEM
 SG_ DwnLoadDynLitPrmLedRiGrilleLamp_UB : 53|1@0+ (1,0) [0|1] "" HCMR
 SG_ DwnLoadDynLitPrmLedRiGrilleLampContTiPrm : 7|10@0+ (1.0,0.0) [0.0|1000.0] "Milliseconds" HCMR
 SG_ DwnLoadDynLitPrmLedRiGrilleLampLowBriPrm : 31|8@0+ (1.0,0.0) [0.0|100.0] "%" HCMR
 SG_ DwnLoadDynLitPrmLedRiGrilleLampModePrm : 13|5@0+ (1,0) [0|31] "" HCMR
 SG_ DwnLoadDynLitPrmLedRiGrilleLampOffsTiPrm : 47|10@0+ (1.0,0.0) [0.0|1000.0] "Milliseconds" HCMR
 SG_ DwnLoadDynLitPrmLedRiGrilleLampTistamp : 8|9@0+ (1.0,0.0) [0.0|511.0] "Unitless" HCMR
 SG_ DwnLoadDynLitPrmLedRiGrilleLampUpprBriPrm : 39|8@0+ (1.0,0.0) [0.0|100.0] "%" HCMR

BO_ 788 CemBodyExpoFr62: 8 CEM
 SG_ DHUcontrolLedMkrLampLe1 : 7|2@0+ (1,0) [0|3] "" RCML,RCMM,RCMR
 SG_ DHUcontrolLedMkrLampLe1_UB : 63|1@0+ (1,0) [0|1] "" RCML,RCMM,RCMR
 SG_ DHUcontrolLedMkrLampLe2 : 5|2@0+ (1,0) [0|3] "" RCML,RCMM,RCMR
 SG_ DHUcontrolLedMkrLampLe2_UB : 62|1@0+ (1,0) [0|1] "" RCML,RCMM,RCMR
 SG_ DHUcontrolLedMkrLampRi1 : 3|2@0+ (1,0) [0|3] "" RCML,RCMM,RCMR
 SG_ DHUcontrolLedMkrLampRi1_UB : 61|1@0+ (1,0) [0|1] "" RCML,RCMM,RCMR
 SG_ DHUcontrolLedMkrLampRi2 : 1|2@0+ (1,0) [0|3] "" RCML,RCMM,RCMR
 SG_ DHUcontrolLedMkrLampRi2_UB : 60|1@0+ (1,0) [0|1] "" RCML,RCMM,RCMR
 SG_ DHUcontrolLedStopLampLe1 : 15|2@0+ (1,0) [0|3] "" RCML,RCMM,RCMR
 SG_ DHUcontrolLedStopLampLe1_UB : 59|1@0+ (1,0) [0|1] "" RCML,RCMM,RCMR
 SG_ DHUcontrolLedStopLampLe2 : 13|2@0+ (1,0) [0|3] "" RCML,RCMM,RCMR
 SG_ DHUcontrolLedStopLampLe2_UB : 58|1@0+ (1,0) [0|1] "" RCML,RCMM,RCMR
 SG_ DHUcontrolLedStopLampRi1 : 11|2@0+ (1,0) [0|3] "" RCML,RCMM,RCMR
 SG_ DHUcontrolLedStopLampRi1_UB : 57|1@0+ (1,0) [0|1] "" RCML,RCMM,RCMR
 SG_ DHUcontrolLedStopLampRi2 : 9|2@0+ (1,0) [0|3] "" RCML,RCMM,RCMR
 SG_ DHUcontrolLedStopLampRi2_UB : 56|1@0+ (1,0) [0|1] "" RCML,RCMM,RCMR
 SG_ DHUcontrolmiddlebrakelight : 23|2@0+ (1,0) [0|3] "" RCML,RCMM,RCMR
 SG_ DHUcontrolmiddlebrakelight_UB : 48|1@0+ (1,0) [0|1] "" RCML,RCMM,RCMR
 SG_ DHUcontrolmiddlecorneringlamp : 21|2@0+ (1,0) [0|3] "" RCML,RCMM,RCMR
 SG_ DHUcontrolmiddlecorneringlamp_UB : 49|1@0+ (1,0) [0|1] "" RCML,RCMM,RCMR
 SG_ DHUcontrolmiddlepositionlight : 19|2@0+ (1,0) [0|3] "" RCML,RCMM,RCMR
 SG_ DHUcontrolmiddlepositionlight_UB : 50|1@0+ (1,0) [0|1] "" RCML,RCMM,RCMR

BO_ 789 CemBodyExpoFr63: 8 CEM
 SG_ DHUcontrolCrossreversinglight : 7|2@0+ (1,0) [0|3] "" RCML,RCMM,RCMR
 SG_ DHUcontrolCrossreversinglight_UB : 63|1@0+ (1,0) [0|1] "" RCML,RCMM,RCMR
 SG_ DHUcontrolleftbrakelightLamp : 5|2@0+ (1,0) [0|3] "" RCML,RCMM,RCMR
 SG_ DHUcontrolleftbrakelightLamp_UB : 62|1@0+ (1,0) [0|1] "" RCML,RCMM,RCMR
 SG_ DHUcontrolleftcorneringlamp : 3|2@0+ (1,0) [0|3] "" RCML,RCMM,RCMR
 SG_ DHUcontrolleftcorneringlamp_UB : 61|1@0+ (1,0) [0|1] "" RCML,RCMM,RCMR
 SG_ DHUcontrolleftdaytimerunninglamp : 1|2@0+ (1,0) [0|3] "" HCML,HCMR
 SG_ DHUcontrolleftdaytimerunninglamp_UB : 60|1@0+ (1,0) [0|1] "" HCML,HCMR
 SG_ DHUcontrolleftfroglight : 15|2@0+ (1,0) [0|3] "" HCML,HCMR
 SG_ DHUcontrolleftfroglight_UB : 59|1@0+ (1,0) [0|1] "" HCML,HCMR
 SG_ DHUcontrolleftheadcorneringlamp : 13|2@0+ (1,0) [0|3] "" HCML,HCMR
 SG_ DHUcontrolleftheadcorneringlamp_UB : 58|1@0+ (1,0) [0|1] "" HCML,HCMR
 SG_ DHUcontrollefthighbeamlamp : 11|2@0+ (1,0) [0|3] "" HCML,HCMR
 SG_ DHUcontrollefthighbeamlamp_UB : 57|1@0+ (1,0) [0|1] "" HCML,HCMR
 SG_ DHUcontrolleftlowbeamlamp : 9|2@0+ (1,0) [0|3] "" HCML,HCMR
 SG_ DHUcontrolleftlowbeamlamp_UB : 56|1@0+ (1,0) [0|1] "" HCML,HCMR
 SG_ DHUcontrolleftpositionlamp : 23|2@0+ (1,0) [0|3] "" HCML,HCMR
 SG_ DHUcontrolleftpositionlamp_UB : 48|1@0+ (1,0) [0|1] "" HCML,HCMR
 SG_ DHUcontrolleftpositionlight : 21|2@0+ (1,0) [0|3] "" RCML,RCMM,RCMR
 SG_ DHUcontrolleftpositionlight_UB : 49|1@0+ (1,0) [0|1] "" RCML,RCMM,RCMR
 SG_ DHUcontrolrightbrakelight : 19|2@0+ (1,0) [0|3] "" RCML,RCMM,RCMR
 SG_ DHUcontrolrightbrakelight_UB : 50|1@0+ (1,0) [0|1] "" RCML,RCMM,RCMR
 SG_ DHUcontrolrightcorneringlamp : 17|2@0+ (1,0) [0|3] "" RCML,RCMM,RCMR
 SG_ DHUcontrolrightcorneringlamp_UB : 51|1@0+ (1,0) [0|1] "" RCML,RCMM,RCMR
 SG_ DHUcontrolrightdaytimerunninglamp : 31|2@0+ (1,0) [0|3] "" HCML,HCMR
 SG_ DHUcontrolrightdaytimerunninglamp_UB : 52|1@0+ (1,0) [0|1] "" HCML,HCMR
 SG_ DHUcontrolrightfroglight : 29|2@0+ (1,0) [0|3] "" HCML,HCMR
 SG_ DHUcontrolrightfroglight_UB : 53|1@0+ (1,0) [0|1] "" HCML,HCMR
 SG_ DHUcontrolrighthighbeamlamp : 27|2@0+ (1,0) [0|3] "" HCML,HCMR
 SG_ DHUcontrolrighthighbeamlamp_UB : 54|1@0+ (1,0) [0|1] "" HCML,HCMR
 SG_ DHUcontrolrightlowbeamlamp : 25|2@0+ (1,0) [0|3] "" HCML,HCMR
 SG_ DHUcontrolrightlowbeamlamp_UB : 55|1@0+ (1,0) [0|1] "" HCML,HCMR
 SG_ DHUcontrolrightpositionLamp : 39|2@0+ (1,0) [0|3] "" RCML,RCMM,RCMR
 SG_ DHUcontrolrightpositionLamp_UB : 40|1@0+ (1,0) [0|1] "" RCML,RCMM,RCMR
 SG_ DHUcontrolrightrearcorneringlamp : 37|2@0+ (1,0) [0|3] "" HCML,HCMR
 SG_ DHUcontrolrightrearcorneringlamp_UB : 32|1@0+ (1,0) [0|1] "" HCML,HCMR
 SG_ DHUcontrolrightrearpositionLamp : 35|2@0+ (1,0) [0|3] "" HCML,HCMR
 SG_ DHUcontrolrightrearpositionLamp_UB : 33|1@0+ (1,0) [0|1] "" HCML,HCMR

BO_ 2047 CemToAllFuncBodyCanExposedDiagReqFrame: 8 CEM
 SG_ CemToAllFuncBodyCanExpDiagReqNpdu : 7|64@0+ (1,0) [0|0] "" HCML, HCMR, RCML, RCMM, RCMR

BO_ 1971 CemToHcmlBodyCanExposedDiagReqFrame: 8 CEM
 SG_ CemToHcmlBodyCanExpDiagReqNpdu : 7|64@0+ (1,0) [0|0] "" HCML

BO_ 1972 CemToHcmrBodyCanExposedDiagReqFrame: 8 CEM
 SG_ CemToHcmrBodyCanExpDiagReqNpdu : 7|64@0+ (1,0) [0|0] "" HCMR

BO_ 1973 CemToRcmlBodyCanExposedDiagReqFrame: 8 CEM
 SG_ CemToRcmlBodyCanExpDiagReqNpdu : 7|64@0+ (1,0) [0|0] "" RCML

BO_ 1975 CemToRcmmBodyCanExposedDiagReqFrame: 8 CEM
 SG_ CemToRcmmBodyCanExpDiagReqNpdu : 7|64@0+ (1,0) [0|0] "" RCMM

BO_ 1974 CemToRcmrBodyCanExposedDiagReqFrame: 8 CEM
 SG_ CemToRcmrBodyCanExpDiagReqNpdu : 7|64@0+ (1,0) [0|0] "" RCMR

BO_ 1425 EtcToCemBodyExpoDevDiagFr03: 8 ETC
 SG_ CEMdevelpsignalgroupreqFunctiondevpsignalgroup1 : 7|8@0+ (1.0,0.0) [0.0|255.0] "Unitless" CEM
 SG_ CEMdevelpsignalgroupreqFunctiondevpsignalgroup2 : 15|8@0+ (1.0,0.0) [0.0|255.0] "Unitless" CEM
 SG_ CEMdevelpsignalgroupreqFunctiondevpsignalgroup3 : 23|8@0+ (1.0,0.0) [0.0|255.0] "Unitless" CEM
 SG_ CEMdevelpsignalgroupreqFunctiondevpsignalgroup4 : 31|8@0+ (1.0,0.0) [0.0|255.0] "Unitless" CEM
 SG_ CEMdevelpsignalgroupreqFunctiondevpsignalgroup5 : 39|8@0+ (1.0,0.0) [0.0|255.0] "Unitless" CEM
 SG_ CEMdevelpsignalgroupreqFunctiondevpsignalgroup6 : 47|8@0+ (1.0,0.0) [0.0|255.0] "Unitless" CEM
 SG_ CEMdevelpsignalgroupreqFunctiondevpsignalgroup7 : 55|8@0+ (1.0,0.0) [0.0|255.0] "Unitless" CEM
 SG_ CEMdevelpsignalgroupreqFunctiondevpsignalgroup8 : 63|8@0+ (1.0,0.0) [0.0|255.0] "Unitless" CEM

BO_ 1430 EtctoHcmlXCPFr01: 8 ETC

BO_ 1428 EtctoHcmrXCPFr01: 8 ETC

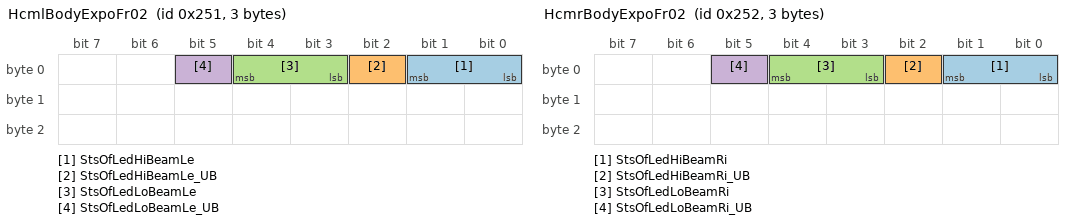
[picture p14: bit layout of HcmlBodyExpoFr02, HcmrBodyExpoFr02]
BO_ 593 HcmlBodyExpoFr02: 3 HCML
 SG_ StsOfLedHiBeamLe : 1|2@0+ (1,0) [0|3] "" CEM
 SG_ StsOfLedHiBeamLe_UB : 2|1@0+ (1,0) [0|1] "" CEM
 SG_ StsOfLedLoBeamLe : 4|2@0+ (1,0) [0|3] "" CEM
 SG_ StsOfLedLoBeamLe_UB : 5|1@0+ (1,0) [0|1] "" CEM

BO_ 124 HcmlBodyExpoFr04: 8 HCML
 SG_ DwnLoadStsFbOfHdlampLe : 5|2@0+ (1,0) [0|3] "" CEM
 SG_ DwnLoadStsFbOfHdlampLe_UB : 39|1@0+ (1,0) [0|1] "" CEM
 SG_ ExtrLiShowActvnFrntLeFb : 28|2@0+ (1,0) [0|3] "" CEM
 SG_ ExtrLiShowActvnFrntLeFb_UB : 20|1@0+ (1,0) [0|1] "" CEM
 SG_ HdlampLeInpSts1 : 49|1@0+ (1,0) [0|1] "" CEM
 SG_ HdlampLeInpSts1_UB : 48|1@0+ (1,0) [0|1] "" CEM
 SG_ HdlampLeInpSts2 : 63|1@0+ (1,0) [0|1] "" CEM
 SG_ HdlampLeInpSts2_UB : 62|1@0+ (1,0) [0|1] "" CEM
 SG_ StsOfAfsLe : 1|2@0+ (1,0) [0|3] "" CEM
 SG_ StsOfAfsLe_UB : 38|1@0+ (1,0) [0|1] "" CEM
 SG_ StsOfAhbcLe : 3|2@0+ (1,0) [0|3] "" CEM
 SG_ StsOfAhbcLe_UB : 37|1@0+ (1,0) [0|1] "" CEM
 SG_ StsOfFrntSideMkrLampLe2 : 9|2@0+ (1,0) [0|3] "" CEM
 SG_ StsOfFrntSideMkrLampLe2_UB : 34|1@0+ (1,0) [0|1] "" CEM
 SG_ StsOfLedCornrgLampLe : 11|2@0+ (1,0) [0|3] "" CEM
 SG_ StsOfLedCornrgLampLe_UB : 33|1@0+ (1,0) [0|1] "" CEM
 SG_ StsOfLedDaytiRunngLampLe : 13|2@0+ (1,0) [0|3] "" CEM
 SG_ StsOfLedDaytiRunngLampLe_UB : 32|1@0+ (1,0) [0|1] "" CEM
 SG_ StsOfLedFrntFogLampLe : 15|2@0+ (1,0) [0|3] "" CEM
 SG_ StsOfLedFrntFogLampLe_UB : 31|1@0+ (1,0) [0|1] "" CEM
 SG_ StsOfLedFrntPosnLampLe : 17|2@0+ (1,0) [0|3] "" CEM
 SG_ StsOfLedFrntPosnLampLe_UB : 30|1@0+ (1,0) [0|1] "" CEM
 SG_ StsOfLedFrntTurnIndcrLe : 19|2@0+ (1,0) [0|3] "" CEM
 SG_ StsOfLedFrntTurnIndcrLe_UB : 29|1@0+ (1,0) [0|1] "" CEM
 SG_ StsOfLvlgLe_UB : 36|1@0+ (1,0) [0|1] "" CEM
 SG_ StsOfLvlgLeChks : 47|8@0+ (1.0,0.0) [0.0|255.0] "Unitless" CEM
 SG_ StsOfLvlgLeCntr : 55|4@0+ (1.0,0.0) [0.0|15.0] "Unitless" CEM
 SG_ StsOfLvlgLeStsOfLvlgLe : 51|2@0+ (1,0) [0|3] "" CEM
 SG_ StsOfSwvlgLe : 7|2@0+ (1,0) [0|3] "" CEM
 SG_ StsOfSwvlgLe_UB : 35|1@0+ (1,0) [0|1] "" CEM
 SG_ StsOfTouristModLe : 25|2@0+ (1,0) [0|3] "" CEM
 SG_ StsOfTouristModLe_UB : 26|1@0+ (1,0) [0|1] "" CEM

BO_ 1329 HcmlBodyExposedNMFr: 8 HCML
 SG_ PNC16_HCML : 16|1@0+ (1,0) [0|0] "" HCMR
 SG_ PNC17_HCML : 17|1@0+ (1,0) [0|0] "" HCMR
 SG_ PNC18_HCML : 18|1@0+ (1,0) [0|0] "" HCMR
 SG_ PNC19_HCML : 19|1@0+ (1,0) [0|0] "" HCMR
 SG_ PNC20_HCML : 20|1@0+ (1,0) [0|0] "" HCMR
 SG_ PNC21_HCML : 21|1@0+ (1,0) [0|0] "" HCMR
 SG_ PNC22_HCML : 22|1@0+ (1,0) [0|0] "" HCMR
 SG_ PNC23_HCML : 23|1@0+ (1,0) [0|0] "" HCMR
 SG_ PNC24_HCML : 24|1@0+ (1,0) [0|0] "" HCMR
 SG_ PNC25_HCML : 25|1@0+ (1,0) [0|0] "" HCMR
 SG_ PNC26_HCML : 26|1@0+ (1,0) [0|0] "" HCMR
 SG_ PNC27_HCML : 27|1@0+ (1,0) [0|0] "" HCMR
 SG_ PNC28_HCML : 28|1@0+ (1,0) [0|0] "" HCMR
 SG_ PNC29_HCML : 29|1@0+ (1,0) [0|0] "" HCMR
 SG_ PNC30_HCML : 30|1@0+ (1,0) [0|0] "" HCMR
 SG_ PNC31_HCML : 31|1@0+ (1,0) [0|0] "" HCMR
 SG_ PNC32_HCML : 32|1@0+ (1,0) [0|0] "" HCMR
 SG_ PNC33_HCML : 33|1@0+ (1,0) [0|0] "" HCMR
 SG_ PNC34_HCML : 34|1@0+ (1,0) [0|0] "" HCMR
 SG_ PNC35_HCML : 35|1@0+ (1,0) [0|0] "" HCMR
 SG_ PNC36_HCML : 36|1@0+ (1,0) [0|0] "" HCMR
 SG_ PNC37_HCML : 37|1@0+ (1,0) [0|0] "" HCMR
 SG_ PNC38_HCML : 38|1@0+ (1,0) [0|0] "" HCMR
 SG_ PNC39_HCML : 39|1@0+ (1,0) [0|0] "" HCMR
 SG_ NM_PNI_HCML : 14|1@0+ (1,0) [0|0] "" HCMR
 SG_ NM_AW_HCML : 12|1@0+ (1,0) [0|0] "" HCMR
 SG_ NM_CS_HCML : 11|1@0+ (1,0) [0|0] "" HCMR
 SG_ NM_RMR_HCML : 8|1@0+ (1,0) [0|0] "" HCMR
 SG_ NM_NodeID_HCML : 7|8@0+ (1,0) [0|0] "" HCMR

BO_ 1715 HcmlToCemBodyCanExposedDiagResFrame: 8 HCML
 SG_ HcmlToCemBodyCanExpDiagResNpdu : 7|64@0+ (1,0) [0|0] "" CEM

BO_ 1424 HcmltoEtcXCPFr01: 8 HCML

BO_ 594 HcmrBodyExpoFr02: 3 HCMR
 SG_ StsOfLedHiBeamRi : 1|2@0+ (1,0) [0|3] "" CEM
 SG_ StsOfLedHiBeamRi_UB : 2|1@0+ (1,0) [0|1] "" CEM
 SG_ StsOfLedLoBeamRi : 4|2@0+ (1,0) [0|3] "" CEM
 SG_ StsOfLedLoBeamRi_UB : 5|1@0+ (1,0) [0|1] "" CEM

BO_ 127 HcmrBodyExpoFr04: 8 HCMR
 SG_ DwnLoadStsFbOfHdlampRi : 5|2@0+ (1,0) [0|3] "" CEM
 SG_ DwnLoadStsFbOfHdlampRi_UB : 39|1@0+ (1,0) [0|1] "" CEM
 SG_ ExtrLiShowActvnFrntRiFb : 28|2@0+ (1,0) [0|3] "" CEM
 SG_ ExtrLiShowActvnFrntRiFb_UB : 20|1@0+ (1,0) [0|1] "" CEM
 SG_ HdlampRiInpSts1 : 49|1@0+ (1,0) [0|1] "" CEM
 SG_ HdlampRiInpSts1_UB : 48|1@0+ (1,0) [0|1] "" CEM
 SG_ HdlampRiInpSts2 : 63|1@0+ (1,0) [0|1] "" CEM
 SG_ HdlampRiInpSts2_UB : 62|1@0+ (1,0) [0|1] "" CEM
 SG_ StsOfAfsRi : 1|2@0+ (1,0) [0|3] "" CEM
 SG_ StsOfAfsRi_UB : 38|1@0+ (1,0) [0|1] "" CEM
 SG_ StsOfAhbcRi : 3|2@0+ (1,0) [0|3] "" CEM
 SG_ StsOfAhbcRi_UB : 37|1@0+ (1,0) [0|1] "" CEM
 SG_ StsOfFrntSideMkrLampRi2 : 9|2@0+ (1,0) [0|3] "" CEM
 SG_ StsOfFrntSideMkrLampRi2_UB : 34|1@0+ (1,0) [0|1] "" CEM
 SG_ StsOfLedCornrgLampRi : 11|2@0+ (1,0) [0|3] "" CEM
 SG_ StsOfLedCornrgLampRi_UB : 33|1@0+ (1,0) [0|1] "" CEM
 SG_ StsOfLedDaytiRunngLampRi : 13|2@0+ (1,0) [0|3] "" CEM
 SG_ StsOfLedDaytiRunngLampRi_UB : 32|1@0+ (1,0) [0|1] "" CEM
 SG_ StsOfLedFrntFogLampRi : 15|2@0+ (1,0) [0|3] "" CEM
 SG_ StsOfLedFrntFogLampRi_UB : 31|1@0+ (1,0) [0|1] "" CEM
 SG_ StsOfLedFrntPosnLampRi : 17|2@0+ (1,0) [0|3] "" CEM
 SG_ StsOfLedFrntPosnLampRi_UB : 30|1@0+ (1,0) [0|1] "" CEM
 SG_ StsOfLedFrntTurnIndcrRi : 19|2@0+ (1,0) [0|3] "" CEM
 SG_ StsOfLedFrntTurnIndcrRi_UB : 29|1@0+ (1,0) [0|1] "" CEM
 SG_ StsOfLvlgRi_UB : 36|1@0+ (1,0) [0|1] "" CEM
 SG_ StsOfLvlgRiChks : 47|8@0+ (1.0,0.0) [0.0|255.0] "Unitless" CEM
 SG_ StsOfLvlgRiCntr : 55|4@0+ (1.0,0.0) [0.0|15.0] "Unitless" CEM
 SG_ StsOfLvlgRiStsOfLvlgRi : 51|2@0+ (1,0) [0|3] "" CEM
 SG_ StsOfSwvlgRi : 7|2@0+ (1,0) [0|3] "" CEM
 SG_ StsOfSwvlgRi_UB : 35|1@0+ (1,0) [0|1] "" CEM
 SG_ StsOfTouristModRi : 25|2@0+ (1,0) [0|3] "" CEM
 SG_ StsOfTouristModRi_UB : 26|1@0+ (1,0) [0|1] "" CEM

BO_ 1330 HcmrBodyExposedNMFr: 8 HCMR
 SG_ PNC16_HCMR : 16|1@0+ (1,0) [0|0] "" CEM
 SG_ PNC17_HCMR : 17|1@0+ (1,0) [0|0] "" CEM
 SG_ PNC18_HCMR : 18|1@0+ (1,0) [0|0] "" CEM
 SG_ PNC19_HCMR : 19|1@0+ (1,0) [0|0] "" CEM
 SG_ PNC20_HCMR : 20|1@0+ (1,0) [0|0] "" CEM
 SG_ PNC21_HCMR : 21|1@0+ (1,0) [0|0] "" CEM
 SG_ PNC22_HCMR : 22|1@0+ (1,0) [0|0] "" CEM
 SG_ PNC23_HCMR : 23|1@0+ (1,0) [0|0] "" CEM
 SG_ PNC24_HCMR : 24|1@0+ (1,0) [0|0] "" CEM
 SG_ PNC25_HCMR : 25|1@0+ (1,0) [0|0] "" CEM
 SG_ PNC26_HCMR : 26|1@0+ (1,0) [0|0] "" CEM
 SG_ PNC27_HCMR : 27|1@0+ (1,0) [0|0] "" CEM
 SG_ PNC28_HCMR : 28|1@0+ (1,0) [0|0] "" CEM
 SG_ PNC29_HCMR : 29|1@0+ (1,0) [0|0] "" CEM
 SG_ PNC30_HCMR : 30|1@0+ (1,0) [0|0] "" CEM
 SG_ PNC31_HCMR : 31|1@0+ (1,0) [0|0] "" CEM
 SG_ PNC32_HCMR : 32|1@0+ (1,0) [0|0] "" CEM
 SG_ PNC33_HCMR : 33|1@0+ (1,0) [0|0] "" CEM
 SG_ PNC34_HCMR : 34|1@0+ (1,0) [0|0] "" CEM
 SG_ PNC35_HCMR : 35|1@0+ (1,0) [0|0] "" CEM
 SG_ PNC36_HCMR : 36|1@0+ (1,0) [0|0] "" CEM
 SG_ PNC37_HCMR : 37|1@0+ (1,0) [0|0] "" CEM
 SG_ PNC38_HCMR : 38|1@0+ (1,0) [0|0] "" CEM
 SG_ PNC39_HCMR : 39|1@0+ (1,0) [0|0] "" CEM
 SG_ NM_PNI_HCMR : 14|1@0+ (1,0) [0|0] "" CEM
 SG_ NM_AW_HCMR : 12|1@0+ (1,0) [0|0] "" CEM
 SG_ NM_CS_HCMR : 11|1@0+ (1,0) [0|0] "" CEM
 SG_ NM_RMR_HCMR : 8|1@0+ (1,0) [0|0] "" CEM
 SG_ NM_NodeID_HCMR : 7|8@0+ (1,0) [0|0] "" CEM

BO_ 1716 HcmrToCemBodyCanExposedDiagResFrame: 8 HCMR
 SG_ HcmrToCemBodyCanExpDiagResNpdu : 7|64@0+ (1,0) [0|0] "" CEM

BO_ 1426 HcmrtoEtcXCPFr01: 8 HCMR

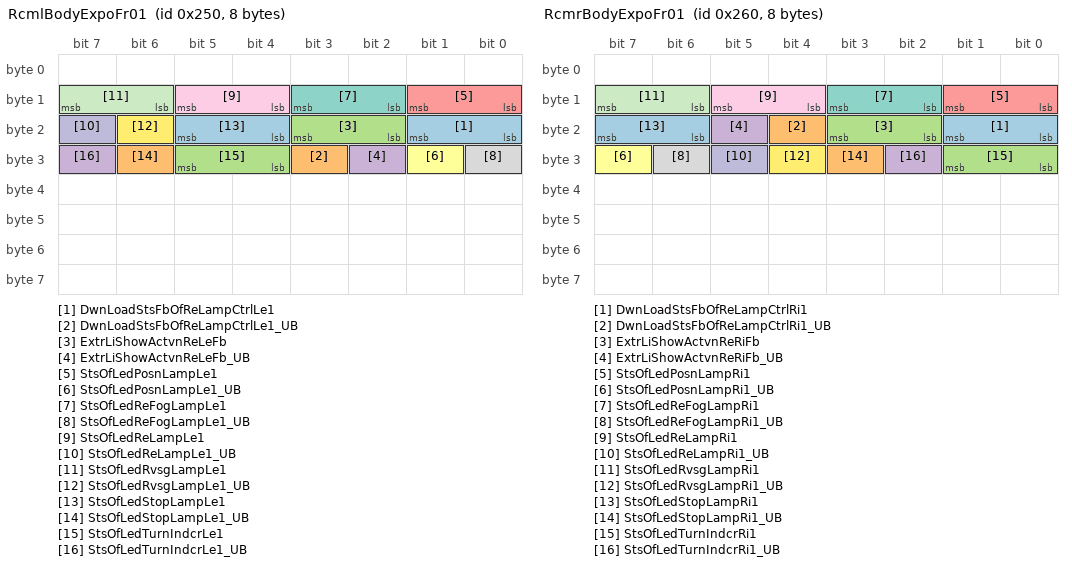
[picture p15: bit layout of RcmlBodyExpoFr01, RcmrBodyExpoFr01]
BO_ 592 RcmlBodyExpoFr01: 8 RCML
 SG_ DwnLoadStsFbOfReLampCtrlLe1 : 17|2@0+ (1,0) [0|3] "" CEM
 SG_ DwnLoadStsFbOfReLampCtrlLe1_UB : 27|1@0+ (1,0) [0|1] "" CEM
 SG_ ExtrLiShowActvnReLeFb : 19|2@0+ (1,0) [0|3] "" CEM
 SG_ ExtrLiShowActvnReLeFb_UB : 26|1@0+ (1,0) [0|1] "" CEM
 SG_ StsOfLedPosnLampLe1 : 9|2@0+ (1,0) [0|3] "" CEM
 SG_ StsOfLedPosnLampLe1_UB : 25|1@0+ (1,0) [0|1] "" CEM
 SG_ StsOfLedReFogLampLe1 : 11|2@0+ (1,0) [0|3] "" CEM
 SG_ StsOfLedReFogLampLe1_UB : 24|1@0+ (1,0) [0|1] "" CEM
 SG_ StsOfLedReLampLe1 : 13|2@0+ (1,0) [0|3] "" CEM
 SG_ StsOfLedReLampLe1_UB : 23|1@0+ (1,0) [0|1] "" CEM
 SG_ StsOfLedRvsgLampLe1 : 15|2@0+ (1,0) [0|3] "" CEM
 SG_ StsOfLedRvsgLampLe1_UB : 22|1@0+ (1,0) [0|1] "" CEM
 SG_ StsOfLedStopLampLe1 : 21|2@0+ (1,0) [0|3] "" CEM
 SG_ StsOfLedStopLampLe1_UB : 30|1@0+ (1,0) [0|1] "" CEM
 SG_ StsOfLedTurnIndcrLe1 : 29|2@0+ (1,0) [0|3] "" CEM
 SG_ StsOfLedTurnIndcrLe1_UB : 31|1@0+ (1,0) [0|1] "" CEM

BO_ 1331 RcmlBodyExposedNMFr: 8 RCML
 SG_ PNC16_RCML : 16|1@0+ (1,0) [0|0] "" HCML
 SG_ PNC17_RCML : 17|1@0+ (1,0) [0|0] "" HCML
 SG_ PNC18_RCML : 18|1@0+ (1,0) [0|0] "" HCML
 SG_ PNC19_RCML : 19|1@0+ (1,0) [0|0] "" HCML
 SG_ PNC20_RCML : 20|1@0+ (1,0) [0|0] "" HCML
 SG_ PNC21_RCML : 21|1@0+ (1,0) [0|0] "" HCML
 SG_ PNC22_RCML : 22|1@0+ (1,0) [0|0] "" HCML
 SG_ PNC23_RCML : 23|1@0+ (1,0) [0|0] "" HCML
 SG_ PNC24_RCML : 24|1@0+ (1,0) [0|0] "" HCML
 SG_ PNC25_RCML : 25|1@0+ (1,0) [0|0] "" HCML
 SG_ PNC26_RCML : 26|1@0+ (1,0) [0|0] "" HCML
 SG_ PNC27_RCML : 27|1@0+ (1,0) [0|0] "" HCML
 SG_ PNC28_RCML : 28|1@0+ (1,0) [0|0] "" HCML
 SG_ PNC29_RCML : 29|1@0+ (1,0) [0|0] "" HCML
 SG_ PNC30_RCML : 30|1@0+ (1,0) [0|0] "" HCML
 SG_ PNC31_RCML : 31|1@0+ (1,0) [0|0] "" HCML
 SG_ PNC32_RCML : 32|1@0+ (1,0) [0|0] "" HCML
 SG_ PNC33_RCML : 33|1@0+ (1,0) [0|0] "" HCML
 SG_ PNC34_RCML : 34|1@0+ (1,0) [0|0] "" HCML
 SG_ PNC35_RCML : 35|1@0+ (1,0) [0|0] "" HCML
 SG_ PNC36_RCML : 36|1@0+ (1,0) [0|0] "" HCML
 SG_ PNC37_RCML : 37|1@0+ (1,0) [0|0] "" HCML
 SG_ PNC38_RCML : 38|1@0+ (1,0) [0|0] "" HCML
 SG_ PNC39_RCML : 39|1@0+ (1,0) [0|0] "" HCML
 SG_ NM_PNI_RCML : 14|1@0+ (1,0) [0|0] "" HCML
 SG_ NM_AW_RCML : 12|1@0+ (1,0) [0|0] "" HCML
 SG_ NM_CS_RCML : 11|1@0+ (1,0) [0|0] "" HCML
 SG_ NM_RMR_RCML : 8|1@0+ (1,0) [0|0] "" HCML
 SG_ NM_NodeID_RCML : 7|8@0+ (1,0) [0|0] "" HCML

BO_ 1717 RcmlToCemBodyCanExposedDiagResFrame: 8 RCML
 SG_ RcmlToCemBodyCanExpDiagResNpdu : 7|64@0+ (1,0) [0|0] "" CEM

BO_ 596 RcmmBodyExpoFr02: 8 RCMM
 SG_ DwnLoadStsFbOfReLampCtrlLe2 : 1|2@0+ (1,0) [0|3] "" CEM
 SG_ DwnLoadStsFbOfReLampCtrlLe2_UB : 47|1@0+ (1,0) [0|1] "" CEM
 SG_ DwnLoadStsFbOfReLampCtrlRi2 : 3|2@0+ (1,0) [0|3] "" CEM
 SG_ DwnLoadStsFbOfReLampCtrlRi2_UB : 46|1@0+ (1,0) [0|1] "" CEM
 SG_ ExtrLiShowActvnReLe2Fb : 5|2@0+ (1,0) [0|3] "" CEM
 SG_ ExtrLiShowActvnReLe2Fb_UB : 45|1@0+ (1,0) [0|1] "" CEM
 SG_ ExtrLiShowActvnReRi2Fb : 7|2@0+ (1,0) [0|3] "" CEM
 SG_ ExtrLiShowActvnReRi2Fb_UB : 44|1@0+ (1,0) [0|1] "" CEM
 SG_ StsOfLedPosnLampLe2 : 9|2@0+ (1,0) [0|3] "" CEM
 SG_ StsOfLedPosnLampLe2_UB : 43|1@0+ (1,0) [0|1] "" CEM
 SG_ StsOfLedPosnLampRi2 : 11|2@0+ (1,0) [0|3] "" CEM
 SG_ StsOfLedPosnLampRi2_UB : 42|1@0+ (1,0) [0|1] "" CEM
 SG_ StsOfLedReFogLampLe2 : 13|2@0+ (1,0) [0|3] "" CEM
 SG_ StsOfLedReFogLampLe2_UB : 41|1@0+ (1,0) [0|1] "" CEM
 SG_ StsOfLedReFogLampRi2 : 15|2@0+ (1,0) [0|3] "" CEM
 SG_ StsOfLedReFogLampRi2_UB : 40|1@0+ (1,0) [0|1] "" CEM
 SG_ StsOfLedReLampLe2 : 17|2@0+ (1,0) [0|3] "" CEM
 SG_ StsOfLedReLampLe2_UB : 39|1@0+ (1,0) [0|1] "" CEM
 SG_ StsOfLedReLampRi2 : 19|2@0+ (1,0) [0|3] "" CEM
 SG_ StsOfLedReLampRi2_UB : 38|1@0+ (1,0) [0|1] "" CEM
 SG_ StsOfLedRvsgLampLe2 : 21|2@0+ (1,0) [0|3] "" CEM
 SG_ StsOfLedRvsgLampLe2_UB : 37|1@0+ (1,0) [0|1] "" CEM
 SG_ StsOfLedRvsgLampRi2 : 23|2@0+ (1,0) [0|3] "" CEM
 SG_ StsOfLedRvsgLampRi2_UB : 36|1@0+ (1,0) [0|1] "" CEM
 SG_ StsOfLedStopLampLe2 : 25|2@0+ (1,0) [0|3] "" CEM
 SG_ StsOfLedStopLampLe2_UB : 35|1@0+ (1,0) [0|1] "" CEM
 SG_ StsOfLedStopLampRi2 : 27|2@0+ (1,0) [0|3] "" CEM
 SG_ StsOfLedStopLampRi2_UB : 34|1@0+ (1,0) [0|1] "" CEM
 SG_ StsOfLedTurnIndcrLe2 : 29|2@0+ (1,0) [0|3] "" CEM
 SG_ StsOfLedTurnIndcrLe2_UB : 33|1@0+ (1,0) [0|1] "" CEM
 SG_ StsOfLedTurnIndcrRi2 : 31|2@0+ (1,0) [0|3] "" CEM
 SG_ StsOfLedTurnIndcrRi2_UB : 32|1@0+ (1,0) [0|1] "" CEM

BO_ 1333 RcmmBodyExposedNMFr: 8 RCMM
 SG_ PNC16_RCMM : 16|1@0+ (1,0) [0|0] "" RCML
 SG_ PNC17_RCMM : 17|1@0+ (1,0) [0|0] "" RCML
 SG_ PNC18_RCMM : 18|1@0+ (1,0) [0|0] "" RCML
 SG_ PNC19_RCMM : 19|1@0+ (1,0) [0|0] "" RCML
 SG_ PNC20_RCMM : 20|1@0+ (1,0) [0|0] "" RCML
 SG_ PNC21_RCMM : 21|1@0+ (1,0) [0|0] "" RCML
 SG_ PNC22_RCMM : 22|1@0+ (1,0) [0|0] "" RCML
 SG_ PNC23_RCMM : 23|1@0+ (1,0) [0|0] "" RCML
 SG_ PNC24_RCMM : 24|1@0+ (1,0) [0|0] "" RCML
 SG_ PNC25_RCMM : 25|1@0+ (1,0) [0|0] "" RCML
 SG_ PNC26_RCMM : 26|1@0+ (1,0) [0|0] "" RCML
 SG_ PNC27_RCMM : 27|1@0+ (1,0) [0|0] "" RCML
 SG_ PNC28_RCMM : 28|1@0+ (1,0) [0|0] "" RCML
 SG_ PNC29_RCMM : 29|1@0+ (1,0) [0|0] "" RCML
 SG_ PNC30_RCMM : 30|1@0+ (1,0) [0|0] "" RCML
 SG_ PNC31_RCMM : 31|1@0+ (1,0) [0|0] "" RCML
 SG_ PNC32_RCMM : 32|1@0+ (1,0) [0|0] "" RCML
 SG_ PNC33_RCMM : 33|1@0+ (1,0) [0|0] "" RCML
 SG_ PNC34_RCMM : 34|1@0+ (1,0) [0|0] "" RCML
 SG_ PNC35_RCMM : 35|1@0+ (1,0) [0|0] "" RCML
 SG_ PNC36_RCMM : 36|1@0+ (1,0) [0|0] "" RCML
 SG_ PNC37_RCMM : 37|1@0+ (1,0) [0|0] "" RCML
 SG_ PNC38_RCMM : 38|1@0+ (1,0) [0|0] "" RCML
 SG_ PNC39_RCMM : 39|1@0+ (1,0) [0|0] "" RCML
 SG_ NM_PNI_RCMM : 14|1@0+ (1,0) [0|0] "" RCML
 SG_ NM_AW_RCMM : 12|1@0+ (1,0) [0|0] "" RCML
 SG_ NM_CS_RCMM : 11|1@0+ (1,0) [0|0] "" RCML
 SG_ NM_RMR_RCMM : 8|1@0+ (1,0) [0|0] "" RCML
 SG_ NM_NodeID_RCMM : 7|8@0+ (1,0) [0|0] "" RCML

BO_ 1719 RcmmToCemBodyCanExposedDiagResFrame: 8 RCMM
 SG_ RcmmToCemBodyCanExpDiagResNpdu : 7|64@0+ (1,0) [0|0] "" CEM

BO_ 608 RcmrBodyExpoFr01: 8 RCMR
 SG_ DwnLoadStsFbOfReLampCtrlRi1 : 17|2@0+ (1,0) [0|3] "" CEM
 SG_ DwnLoadStsFbOfReLampCtrlRi1_UB : 20|1@0+ (1,0) [0|1] "" CEM
 SG_ ExtrLiShowActvnReRiFb : 19|2@0+ (1,0) [0|3] "" CEM
 SG_ ExtrLiShowActvnReRiFb_UB : 21|1@0+ (1,0) [0|1] "" CEM
 SG_ StsOfLedPosnLampRi1 : 9|2@0+ (1,0) [0|3] "" CEM
 SG_ StsOfLedPosnLampRi1_UB : 31|1@0+ (1,0) [0|1] "" CEM
 SG_ StsOfLedReFogLampRi1 : 11|2@0+ (1,0) [0|3] "" CEM
 SG_ StsOfLedReFogLampRi1_UB : 30|1@0+ (1,0) [0|1] "" CEM
 SG_ StsOfLedReLampRi1 : 13|2@0+ (1,0) [0|3] "" CEM
 SG_ StsOfLedReLampRi1_UB : 29|1@0+ (1,0) [0|1] "" CEM
 SG_ StsOfLedRvsgLampRi1 : 15|2@0+ (1,0) [0|3] "" CEM
 SG_ StsOfLedRvsgLampRi1_UB : 28|1@0+ (1,0) [0|1] "" CEM
 SG_ StsOfLedStopLampRi1 : 23|2@0+ (1,0) [0|3] "" CEM
 SG_ StsOfLedStopLampRi1_UB : 27|1@0+ (1,0) [0|1] "" CEM
 SG_ StsOfLedTurnIndcrRi1 : 25|2@0+ (1,0) [0|3] "" CEM
 SG_ StsOfLedTurnIndcrRi1_UB : 26|1@0+ (1,0) [0|1] "" CEM

BO_ 1332 RcmrBodyExposedNMFr: 8 RCMR
 SG_ PNC16_RCMR : 16|1@0+ (1,0) [0|0] "" RCMM
 SG_ PNC17_RCMR : 17|1@0+ (1,0) [0|0] "" RCMM
 SG_ PNC18_RCMR : 18|1@0+ (1,0) [0|0] "" RCMM
 SG_ PNC19_RCMR : 19|1@0+ (1,0) [0|0] "" RCMM
 SG_ PNC20_RCMR : 20|1@0+ (1,0) [0|0] "" RCMM
 SG_ PNC21_RCMR : 21|1@0+ (1,0) [0|0] "" RCMM
 SG_ PNC22_RCMR : 22|1@0+ (1,0) [0|0] "" RCMM
 SG_ PNC23_RCMR : 23|1@0+ (1,0) [0|0] "" RCMM
 SG_ PNC24_RCMR : 24|1@0+ (1,0) [0|0] "" RCMM
 SG_ PNC25_RCMR : 25|1@0+ (1,0) [0|0] "" RCMM
 SG_ PNC26_RCMR : 26|1@0+ (1,0) [0|0] "" RCMM
 SG_ PNC27_RCMR : 27|1@0+ (1,0) [0|0] "" RCMM
 SG_ PNC28_RCMR : 28|1@0+ (1,0) [0|0] "" RCMM
 SG_ PNC29_RCMR : 29|1@0+ (1,0) [0|0] "" RCMM
 SG_ PNC30_RCMR : 30|1@0+ (1,0) [0|0] "" RCMM
 SG_ PNC31_RCMR : 31|1@0+ (1,0) [0|0] "" RCMM
 SG_ PNC32_RCMR : 32|1@0+ (1,0) [0|0] "" RCMM
 SG_ PNC33_RCMR : 33|1@0+ (1,0) [0|0] "" RCMM
 SG_ PNC34_RCMR : 34|1@0+ (1,0) [0|0] "" RCMM
 SG_ PNC35_RCMR : 35|1@0+ (1,0) [0|0] "" RCMM
 SG_ PNC36_RCMR : 36|1@0+ (1,0) [0|0] "" RCMM
 SG_ PNC37_RCMR : 37|1@0+ (1,0) [0|0] "" RCMM
 SG_ PNC38_RCMR : 38|1@0+ (1,0) [0|0] "" RCMM
 SG_ PNC39_RCMR : 39|1@0+ (1,0) [0|0] "" RCMM
 SG_ NM_PNI_RCMR : 14|1@0+ (1,0) [0|0] "" RCMM
 SG_ NM_AW_RCMR : 12|1@0+ (1,0) [0|0] "" RCMM
 SG_ NM_CS_RCMR : 11|1@0+ (1,0) [0|0] "" RCMM
 SG_ NM_RMR_RCMR : 8|1@0+ (1,0) [0|0] "" RCMM
 SG_ NM_NodeID_RCMR : 7|8@0+ (1,0) [0|0] "" RCMM

BO_ 1718 RcmrToCemBodyCanExposedDiagResFrame: 8 RCMR
 SG_ RcmrToCemBodyCanExpDiagResNpdu : 7|64@0+ (1,0) [0|0] "" CEM

CM_ SG_ 312 DwnLoadDynLitPrmForLedLoBeamLeContTiPrm "Light Show Continue Time Parameter 1";
CM_ SG_ 312 DwnLoadDynLitPrmForLedLoBeamLeLowBriPrm "Light Show Lower Brightness Parameter 1";
CM_ SG_ 312 DwnLoadDynLitPrmForLedLoBeamLeModePrm "Light Show Mode Parameter 1";
CM_ SG_ 312 DwnLoadDynLitPrmForLedLoBeamLeOffsTiPrm "Light Show Offset Time Parameter 1";
CM_ SG_ 312 DwnLoadDynLitPrmForLedLoBeamLeTistamp "Light Show time stamp";
CM_ SG_ 312 DwnLoadDynLitPrmForLedLoBeamLeUpprBriPrm "Light Show Upper Brightness Parameter 1";
CM_ SG_ 313 DwnLoadDynLtgPrmForLedAllWthrLampLeContTiPrm "Light Show Continue Time Parameter 1";
CM_ SG_ 313 DwnLoadDynLtgPrmForLedAllWthrLampLeLowBriPrm "Light Show Lower Brightness Parameter 1";
CM_ SG_ 313 DwnLoadDynLtgPrmForLedAllWthrLampLeModePrm "Light Show Mode Parameter 1";
CM_ SG_ 313 DwnLoadDynLtgPrmForLedAllWthrLampLeOffsTiPrm "Light Show Offset Time Parameter 1";
CM_ SG_ 313 DwnLoadDynLtgPrmForLedAllWthrLampLeTistamp "Light Show time stamp";
CM_ SG_ 313 DwnLoadDynLtgPrmForLedAllWthrLampLeUpprBriPrm "Light Show Upper Brightness Parameter 1";
CM_ SG_ 314 DwnLoadDynLtgPrmForLedAllWthrLampRiContTiPrm "Light Show Continue Time Parameter 1";
CM_ SG_ 314 DwnLoadDynLtgPrmForLedAllWthrLampRiLowBriPrm "Light Show Lower Brightness Parameter 1";
CM_ SG_ 314 DwnLoadDynLtgPrmForLedAllWthrLampRiModePrm "Light Show Mode Parameter 1";
CM_ SG_ 314 DwnLoadDynLtgPrmForLedAllWthrLampRiOffsTiPrm "Light Show Offset Time Parameter 1";
CM_ SG_ 314 DwnLoadDynLtgPrmForLedAllWthrLampRiTistamp "Light Show time stamp";
CM_ SG_ 314 DwnLoadDynLtgPrmForLedAllWthrLampRiUpprBriPrm "Light Show Upper Brightness Parameter 1";
CM_ SG_ 315 DwnLoadDynLtgPrmForLedCornrgLampLeContTiPrm "Light Show Continue Time Parameter 1";
CM_ SG_ 315 DwnLoadDynLtgPrmForLedCornrgLampLeLowBriPrm "Light Show Lower Brightness Parameter 1";
CM_ SG_ 315 DwnLoadDynLtgPrmForLedCornrgLampLeModePrm "Light Show Mode Parameter 1";
CM_ SG_ 315 DwnLoadDynLtgPrmForLedCornrgLampLeOffsTiPrm "Light Show Offset Time Parameter 1";
CM_ SG_ 315 DwnLoadDynLtgPrmForLedCornrgLampLeTistamp "Light Show time stamp";
CM_ SG_ 315 DwnLoadDynLtgPrmForLedCornrgLampLeUpprBriPrm "Light Show Upper Brightness Parameter 1";
CM_ SG_ 316 DwnLoadDynLtgPrmForLedCornrgLampRiContTiPrm "Light Show Continue Time Parameter 1";
CM_ SG_ 316 DwnLoadDynLtgPrmForLedCornrgLampRiLowBriPrm "Light Show Lower Brightness Parameter 1";
CM_ SG_ 316 DwnLoadDynLtgPrmForLedCornrgLampRiModePrm "Light Show Mode Parameter 1";
CM_ SG_ 316 DwnLoadDynLtgPrmForLedCornrgLampRiOffsTiPrm "Light Show Offset Time Parameter 1";
CM_ SG_ 316 DwnLoadDynLtgPrmForLedCornrgLampRiTistamp "Light Show time stamp";
CM_ SG_ 316 DwnLoadDynLtgPrmForLedCornrgLampRiUpprBriPrm "Light Show Upper Brightness Parameter 1";
CM_ SG_ 317 DwnLoadDynLtgPrmForLedDaytiRunngLampLeContTiPrm "Light Show Continue Time Parameter 1";
CM_ SG_ 317 DwnLoadDynLtgPrmForLedDaytiRunngLampLeLowBriPrm "Light Show Lower Brightness Parameter 1";
CM_ SG_ 317 DwnLoadDynLtgPrmForLedDaytiRunngLampLeModePrm "Light Show Mode Parameter 1";
CM_ SG_ 317 DwnLoadDynLtgPrmForLedDaytiRunngLampLeOffsTiPrm "Light Show Offset Time Parameter 1";
CM_ SG_ 317 DwnLoadDynLtgPrmForLedDaytiRunngLampLeTistamp "Light Show time stamp";
CM_ SG_ 317 DwnLoadDynLtgPrmForLedDaytiRunngLampLeUpprBriPrm "Light Show Upper Brightness Parameter 1";
CM_ SG_ 318 DwnLoadDynLtgPrmForLedDaytiRunngLampRiContTiPrm "Light Show Continue Time Parameter 1";
CM_ SG_ 318 DwnLoadDynLtgPrmForLedDaytiRunngLampRiLowBriPrm "Light Show Lower Brightness Parameter 1";
CM_ SG_ 318 DwnLoadDynLtgPrmForLedDaytiRunngLampRiModePrm "Light Show Mode Parameter 1";
CM_ SG_ 318 DwnLoadDynLtgPrmForLedDaytiRunngLampRiOffsTiPrm "Light Show Offset Time Parameter 1";
CM_ SG_ 318 DwnLoadDynLtgPrmForLedDaytiRunngLampRiTistamp "Light Show time stamp";
CM_ SG_ 318 DwnLoadDynLtgPrmForLedDaytiRunngLampRiUpprBriPrm "Light Show Upper Brightness Parameter 1";
CM_ SG_ 319 DwnLoadDynLtgPrmForLedFrntPosnLampLeContTiPrm "Light Show Continue Time Parameter 1";
CM_ SG_ 319 DwnLoadDynLtgPrmForLedFrntPosnLampLeLowBriPrm "Light Show Lower Brightness Parameter 1";
CM_ SG_ 319 DwnLoadDynLtgPrmForLedFrntPosnLampLeModePrm "Light Show Mode Parameter 1";
CM_ SG_ 319 DwnLoadDynLtgPrmForLedFrntPosnLampLeOffsTiPrm "Light Show Offset Time Parameter 1";
CM_ SG_ 319 DwnLoadDynLtgPrmForLedFrntPosnLampLeTistamp "Light Show time stamp";
CM_ SG_ 319 DwnLoadDynLtgPrmForLedFrntPosnLampLeUpprBriPrm "Light Show Upper Brightness Parameter 1";
CM_ SG_ 320 DwnLoadDynLtgPrmForLedFrntPosnLampRiContTiPrm "Light Show Continue Time Parameter 1";
CM_ SG_ 320 DwnLoadDynLtgPrmForLedFrntPosnLampRiLowBriPrm "Light Show Lower Brightness Parameter 1";
CM_ SG_ 320 DwnLoadDynLtgPrmForLedFrntPosnLampRiModePrm "Light Show Mode Parameter 1";
CM_ SG_ 320 DwnLoadDynLtgPrmForLedFrntPosnLampRiOffsTiPrm "Light Show Offset Time Parameter 1";
CM_ SG_ 320 DwnLoadDynLtgPrmForLedFrntPosnLampRiTistamp "Light Show time stamp";
CM_ SG_ 320 DwnLoadDynLtgPrmForLedFrntPosnLampRiUpprBriPrm "Light Show Upper Brightness Parameter 1";
CM_ SG_ 321 DwnLoadDynLtgPrmForLedFrntTurnIndcrLeContTiPrm "Light Show Continue Time Parameter 1";
CM_ SG_ 321 DwnLoadDynLtgPrmForLedFrntTurnIndcrLeLowBriPrm "Light Show Lower Brightness Parameter 1";
CM_ SG_ 321 DwnLoadDynLtgPrmForLedFrntTurnIndcrLeModePrm "Light Show Mode Parameter 1";
CM_ SG_ 321 DwnLoadDynLtgPrmForLedFrntTurnIndcrLeOffsTiPrm "Light Show Offset Time Parameter 1";
CM_ SG_ 321 DwnLoadDynLtgPrmForLedFrntTurnIndcrLeTistamp "Light Show time stamp";
CM_ SG_ 321 DwnLoadDynLtgPrmForLedFrntTurnIndcrLeUpprBriPrm "Light Show Upper Brightness Parameter 1";
CM_ SG_ 322 DwnLoadDynLtgPrmForLedFrntTurnIndcrRiContTiPrm "Light Show Continue Time Parameter 1";
CM_ SG_ 322 DwnLoadDynLtgPrmForLedFrntTurnIndcrRiLowBriPrm "Light Show Lower Brightness Parameter 1";
CM_ SG_ 322 DwnLoadDynLtgPrmForLedFrntTurnIndcrRiModePrm "Light Show Mode Parameter 1";
CM_ SG_ 322 DwnLoadDynLtgPrmForLedFrntTurnIndcrRiOffsTiPrm "Light Show Offset Time Parameter 1";
CM_ SG_ 322 DwnLoadDynLtgPrmForLedFrntTurnIndcrRiTistamp "Light Show time stamp";
CM_ SG_ 322 DwnLoadDynLtgPrmForLedFrntTurnIndcrRiUpprBriPrm "Light Show Upper Brightness Parameter 1";
CM_ SG_ 323 DwnLoadDynLtgPrmForLedHiBeamRiContTiPrm "Light Show Continue Time Parameter 1";
CM_ SG_ 323 DwnLoadDynLtgPrmForLedHiBeamRiLowBriPrm "Light Show Lower Brightness Parameter 1";
CM_ SG_ 323 DwnLoadDynLtgPrmForLedHiBeamRiModePrm "Light Show Mode Parameter 1";
CM_ SG_ 323 DwnLoadDynLtgPrmForLedHiBeamRiOffsTiPrm "Light Show Offset Time Parameter 1";
CM_ SG_ 323 DwnLoadDynLtgPrmForLedHiBeamRiTistamp "Light Show time stamp";
CM_ SG_ 323 DwnLoadDynLtgPrmForLedHiBeamRiUpprBriPrm "Light Show Upper Brightness Parameter 1";
CM_ SG_ 377 ADataRawSafeALat "IMU acceleration data Lateral acceleration";
CM_ SG_ 377 ADataRawSafeALat1Qf "IMU acceleration data Quality factor for Lateral acceleration signal";
CM_ SG_ 377 ADataRawSafeALgt "IMU acceleration data Longitudinal acceleration";
CM_ SG_ 377 ADataRawSafeALgt1Qf "IMU acceleration data Quality factor for Longitudinal acceleration";
CM_ SG_ 377 ADataRawSafeAVert "IMU acceleration data Vertical acceleration";
CM_ SG_ 377 ADataRawSafeAVertQf "IMU acceleration data Quality factor for Vertical acceleration";
CM_ SG_ 377 ADataRawSafeChks "IMU acceleration data Check sum";
CM_ SG_ 377 ADataRawSafeCntr "IMU acceleration data Counter";
CM_ SG_ 381 ActnOfLedGrilleLampDyn "Activation of Grille Lamp as part of Position Lights with dynamic pattern";
CM_ SG_ 381 ActnOfLedPosnLampDyn "Activation of Led Position Lamp Dynamic mode";
CM_ SG_ 381 AgDataRawSafeChks "IMU angular rate data. Check summa";
CM_ SG_ 381 AgDataRawSafeCntr "IMU angular rate data. Counter";
CM_ SG_ 381 AgDataRawSafeRollRate "IMU angular rate data. Roll Rate";
CM_ SG_ 381 AgDataRawSafeRollRateQf "IMU angular rate data. Quality factor for Roll Rate";
CM_ SG_ 381 AgDataRawSafeYawRate "IMU angular rate data. Yaw Rate";
CM_ SG_ 381 AgDataRawSafeYawRateQf "IMU angular rate data. Quality Factor for Yaw Rate";
CM_ SG_ 612 BrkPedlValBrkPedlVal "Position of the brake pedal. Physical lower limit: no pedal activation. Physical upper limit: full pedal stroke Brake pedal position";
CM_ SG_ 612 BrkPedlValQf "Position of the brake pedal. Physical lower limit: no pedal activation. Physical upper limit: full pedal stroke Brake pedal sensor quality factor";
CM_ SG_ 612 LitArea "Whether the host vehicle is in a lit area";
CM_ SG_ 612 WipgInfoWipgSpdInfo "Information regarding how the wipers are run";
CM_ SG_ 612 WipgInfoWiprActv " 0 No wiping, 1 Wiping";
CM_ SG_ 612 WipgInfoWiprInWipgAr " 0 Wiper in lower reversing area or parked, 1 Wiper in wiping area";
CM_ SG_ 324 DwnLoadDynLitPrmForLedMkrLampRi2ContTiPrm "Light Show Continue Time Parameter 1";
CM_ SG_ 324 DwnLoadDynLitPrmForLedMkrLampRi2LowBriPrm "Light Show Lower Brightness Parameter 1";
CM_ SG_ 324 DwnLoadDynLitPrmForLedMkrLampRi2ModePrm "Light Show Mode Parameter 1";
CM_ SG_ 324 DwnLoadDynLitPrmForLedMkrLampRi2OffsTiPrm "Light Show Offset Time Parameter 1";
CM_ SG_ 324 DwnLoadDynLitPrmForLedMkrLampRi2Tistamp "Light Show time stamp";
CM_ SG_ 324 DwnLoadDynLitPrmForLedMkrLampRi2UpprBriPrm "Light Show Upper Brightness Parameter 1";
CM_ SG_ 325 DwnLoadDynLitPrmLedRvsgLampRi2ContTiPrm "Light Show Continue Time Parameter 1";
CM_ SG_ 325 DwnLoadDynLitPrmLedRvsgLampRi2LowBriPrm "Light Show Lower Brightness Parameter 1";
CM_ SG_ 325 DwnLoadDynLitPrmLedRvsgLampRi2ModePrm "Light Show Mode Parameter 1";
CM_ SG_ 325 DwnLoadDynLitPrmLedRvsgLampRi2OffsTiPrm "Light Show Offset Time Parameter 1";
CM_ SG_ 325 DwnLoadDynLitPrmLedRvsgLampRi2Tistamp "Light Show time stamp";
CM_ SG_ 325 DwnLoadDynLitPrmLedRvsgLampRi2UpprBriPrm "Light Show Upper Brightness Parameter 1";
CM_ SG_ 522 ActnOfLedCornrgLampLe "Acitvation of Led Cornering Lamp Left";
CM_ SG_ 522 ActnOfLedCornrgLampRi "Activate LED Cornering Lamp Right.";
CM_ SG_ 522 ActnOfLedDaytiRunngLamp "Activate LED Daytime Running Lamp.";
CM_ SG_ 522 ActnOfLedFrntFogLamp "Activate LED Front Fog Lamp.";
CM_ SG_ 522 ActnOfLedHiBeam "Activate LED High Beam.";
CM_ SG_ 522 ActnOfLedLoBeamActnOfLedLoBeam "Activation of Low Beam function to HCM";
CM_ SG_ 522 ActnOfLedLoBeamChks "Low Beam Check Sum ASIL B";
CM_ SG_ 522 ActnOfLedLoBeamCntr "Low Beam Counter ASIL B";
CM_ SG_ 522 ActnOfLedPosnLamp "Activate LED Position Lamp.";
CM_ SG_ 522 ActnOfLedReFogLamp "Activate LED Rear Fog Lamp.";
CM_ SG_ 522 ActnOfLedRvsgLamp "Activate LED Revering Lamp.";
CM_ SG_ 522 ActnOfLedStopLampActnOfLedStopLamp "Activation of Stop Lamps by HCM";
CM_ SG_ 522 ActnOfLedStopLampChks "Stop Lamps Check Sum ASIL B";
CM_ SG_ 522 ActnOfLedStopLampCntr "Stop Lamps Counter ASIL B";
CM_ SG_ 522 ActvnOfAfs "Activation of Aaptive Frontlight System ";
CM_ SG_ 522 ActvnOfAhbc "Activate Auto High Beam Control.";
CM_ SG_ 522 ActvnOfAhl "Activate Auto Headlamp Leveling";
CM_ SG_ 522 ActvnOfBrkLi "Activation of Break Light";
CM_ SG_ 522 ActvnOfDbl "Activate Bending Light.";
CM_ SG_ 522 ActvnOfGoodByeLi "Activation Request for Goodbye Light";
CM_ SG_ 522 ActvnOfTouristMod "Activate Tourist Mode.";
CM_ SG_ 522 ActvnOfWelcomeLi "Activation Request for Welcome Light";
CM_ SG_ 538 ActvnOfIndcrIndcrOut "Direction indicator command";
CM_ SG_ 538 ActvnOfIndcrIndcrOutChks "CheckSum";
CM_ SG_ 538 ActvnOfIndcrIndcrOutCntr "Coounter";
CM_ SG_ 538 EmgyBrkLiIndcrTurn "Activation of both rear direction indicators for EBL.";
CM_ SG_ 538 IndcrPatCmd1WdTiOff "Used for Hazard Sleep (subfunction to Hazard Warning Light).

This signal holds the pattern of the flashing to use when buses are asleep and TRM/DCUs shall flash synchronized by themselves.

Holds both on and off timing in two separate record items. HWL Off time";
CM_ SG_ 538 IndcrPatCmd1WdTiOn "Used for Hazard Sleep (subfunction to Hazard Warning Light).

This signal holds the pattern of the flashing to use when buses are asleep and TRM/DCUs shall flash synchronized by themselves.

Holds both on and off timing in two separate record items. HWL On time";
CM_ SG_ 538 IndcrSts "Provides the state and not the event of HWL/Direction Indicator.";
CM_ SG_ 326 DwnLoadDynLitPrmForLedLogoLampContTiPrm "Light Show Continue Time Parameter 1";
CM_ SG_ 326 DwnLoadDynLitPrmForLedLogoLampLowBriPrm "Light Show Lower Brightness Parameter 1";
CM_ SG_ 326 DwnLoadDynLitPrmForLedLogoLampModePrm "Light Show Mode Parameter 1";
CM_ SG_ 326 DwnLoadDynLitPrmForLedLogoLampOffsTiPrm "Light Show Offset Time Parameter 1";
CM_ SG_ 326 DwnLoadDynLitPrmForLedLogoLampTistamp "Light Show time stamp";
CM_ SG_ 326 DwnLoadDynLitPrmForLedLogoLampUpprBriPrm "Light Show Upper Brightness Parameter 1";
CM_ SG_ 327 DwnLoadDynLitPrmLedRePosnLampLe3ContTiPrm "Light Show Offset Time Parameter 1";
CM_ SG_ 327 DwnLoadDynLitPrmLedRePosnLampLe3LowBriPrm "Light Show Lower Brightness Parameter 1";
CM_ SG_ 327 DwnLoadDynLitPrmLedRePosnLampLe3ModePrm "Light Show Mode Parameter 1";
CM_ SG_ 327 DwnLoadDynLitPrmLedRePosnLampLe3OffsTiPrm "Light Show Offset Time Parameter 1";
CM_ SG_ 327 DwnLoadDynLitPrmLedRePosnLampLe3Tistamp "Light Show time stamp";
CM_ SG_ 327 DwnLoadDynLitPrmLedRePosnLampLe3UpprBriPrm "Light Show Upper Brightness Parameter 1";
CM_ SG_ 328 DwnLoadDynLitPrmLedRePosnLampLe4ContTiPrm "Light Show Continue Time Parameter 1";
CM_ SG_ 328 DwnLoadDynLitPrmLedRePosnLampLe4LowBriPrm "Light Show Lower Brightness Parameter 1";
CM_ SG_ 328 DwnLoadDynLitPrmLedRePosnLampLe4ModePrm "Light Show Mode Parameter 1";
CM_ SG_ 328 DwnLoadDynLitPrmLedRePosnLampLe4OffsTiPrm "Light Show Offset Time Parameter 1";
CM_ SG_ 328 DwnLoadDynLitPrmLedRePosnLampLe4Tistamp "Light Show time stamp";
CM_ SG_ 328 DwnLoadDynLitPrmLedRePosnLampLe4UpprBriPrm "Light Show Upper Brightness Parameter 1";
CM_ SG_ 329 DwnLoadDynLitPrmLedRePosnLampLe5ContTiPrm "Light Show Continue Time Parameter 1";
CM_ SG_ 329 DwnLoadDynLitPrmLedRePosnLampLe5LowBriPrm "Light Show Lower Brightness Parameter 1";
CM_ SG_ 329 DwnLoadDynLitPrmLedRePosnLampLe5ModePrm "Light Show Mode Parameter 1";
CM_ SG_ 329 DwnLoadDynLitPrmLedRePosnLampLe5OffsTiPrm "Light Show Offset Time Parameter 1";
CM_ SG_ 329 DwnLoadDynLitPrmLedRePosnLampLe5Tistamp "Light Show time stamp";
CM_ SG_ 329 DwnLoadDynLitPrmLedRePosnLampLe5UpprBriPrm "Light Show Upper Brightness Parameter 1";
CM_ SG_ 330 DwnLoadDynLitPrmLedRePosnLampRi3ContTiPrm "Light Show Continue Time Parameter 1";
CM_ SG_ 330 DwnLoadDynLitPrmLedRePosnLampRi3LowBriPrm "Light Show Lower Brightness Parameter 1";
CM_ SG_ 330 DwnLoadDynLitPrmLedRePosnLampRi3ModePrm "Light Show Mode Parameter 1";
CM_ SG_ 330 DwnLoadDynLitPrmLedRePosnLampRi3OffsTiPrm "Light Show Offset Time Parameter 1";
CM_ SG_ 330 DwnLoadDynLitPrmLedRePosnLampRi3Tistamp "Light Show time stamp";
CM_ SG_ 330 DwnLoadDynLitPrmLedRePosnLampRi3UpprBriPrm "Light Show Upper Brightness Parameter 1";
CM_ SG_ 331 DwnLoadDynLitPrmLedRePosnLampRi4ContTiPrm "Light Show Continue Time Parameter 1";
CM_ SG_ 331 DwnLoadDynLitPrmLedRePosnLampRi4LowBriPrm "Light Show Lower Brightness Parameter 1";
CM_ SG_ 331 DwnLoadDynLitPrmLedRePosnLampRi4ModePrm "Light Show Mode Parameter 1";
CM_ SG_ 331 DwnLoadDynLitPrmLedRePosnLampRi4OffsTiPrm "Light Show Offset Time Parameter 1";
CM_ SG_ 331 DwnLoadDynLitPrmLedRePosnLampRi4Tistamp "Light Show time stamp";
CM_ SG_ 331 DwnLoadDynLitPrmLedRePosnLampRi4UpprBriPrm "Light Show Upper Brightness Parameter 1";
CM_ SG_ 332 DwnLoadDynLitPrmLedRePosnLampRi5ContTiPrm "Light Show Continue Time Parameter 1";
CM_ SG_ 332 DwnLoadDynLitPrmLedRePosnLampRi5LowBriPrm "Light Show Lower Brightness Parameter 1";
CM_ SG_ 332 DwnLoadDynLitPrmLedRePosnLampRi5ModePrm "Light Show Mode Parameter 1";
CM_ SG_ 332 DwnLoadDynLitPrmLedRePosnLampRi5OffsTiPrm "Light Show Offset Time Parameter 1";
CM_ SG_ 332 DwnLoadDynLitPrmLedRePosnLampRi5Tistamp "Light Show time stamp";
CM_ SG_ 332 DwnLoadDynLitPrmLedRePosnLampRi5UpprBriPrm "Light Show Upper Brightness Parameter 1";
CM_ SG_ 24 WelcomeGoodbyeModeReq "this port is used to inform the CEM the user choose which one mode of  welcome goodbye  founction.";
CM_ SG_ 333 DwnLoadDynLitPrmLedLeGrilleLampContTiPrm "Light Show Continue Time Parameter 1";
CM_ SG_ 333 DwnLoadDynLitPrmLedLeGrilleLampLowBriPrm "Light Show Lower Brightness Parameter 1";
CM_ SG_ 333 DwnLoadDynLitPrmLedLeGrilleLampModePrm "Light Show Mode Parameter 1";
CM_ SG_ 333 DwnLoadDynLitPrmLedLeGrilleLampOffsTiPrm "Light Show Offset Time Parameter 1";
CM_ SG_ 333 DwnLoadDynLitPrmLedLeGrilleLampTistamp "Light Show time stamp";
CM_ SG_ 333 DwnLoadDynLitPrmLedLeGrilleLampUpprBriPrm "Light Show Upper Brightness Parameter 1";
CM_ SG_ 334 DwnLoadDynLitPrmLedRiGrilleLampContTiPrm "Light Show Continue Time Parameter 1";
CM_ SG_ 334 DwnLoadDynLitPrmLedRiGrilleLampLowBriPrm "Light Show Lower Brightness Parameter 1";
CM_ SG_ 334 DwnLoadDynLitPrmLedRiGrilleLampModePrm "Light Show Mode Parameter 1";
CM_ SG_ 334 DwnLoadDynLitPrmLedRiGrilleLampOffsTiPrm "Light Show Offset Time Parameter 1";
CM_ SG_ 334 DwnLoadDynLitPrmLedRiGrilleLampTistamp "Light Show time stamp";
CM_ SG_ 334 DwnLoadDynLitPrmLedRiGrilleLampUpprBriPrm "Light Show Upper Brightness Parameter 1";
CM_ SG_ 788 DHUcontrolLedMkrLampLe1 "DHU control LedMkrLampLe1
0 = OnOffNoReq_NoReq
1 = OnOffNoReq_On
2 = OnOffNoReq_Off";
CM_ SG_ 788 DHUcontrolLedMkrLampLe2 "DHU control LedMkrLampLe2
0 = OnOffNoReq_NoReq
1 = OnOffNoReq_On
2 = OnOffNoReq_Off";
CM_ SG_ 788 DHUcontrolLedMkrLampRi1 "DHU control LedMkrLampRi1
0 = OnOffNoReq_NoReq
1 = OnOffNoReq_On
2 = OnOffNoReq_Off
";
CM_ SG_ 788 DHUcontrolLedMkrLampRi2 "DHU control LedMkrLampRi2
0 = OnOffNoReq_NoReq
1 = OnOffNoReq_On
2 = OnOffNoReq_Off





";
CM_ SG_ 788 DHUcontrolLedStopLampLe1 "DHU control LedStopLampLe1
0 = OnOffNoReq_NoReq
1 = OnOffNoReq_On
2 = OnOffNoReq_Off";
CM_ SG_ 788 DHUcontrolLedStopLampLe2 "DHU control LedStopLampLe2
0 = OnOffNoReq_NoReq
1 = OnOffNoReq_On
2 = OnOffNoReq_Off





";
CM_ SG_ 788 DHUcontrolLedStopLampRi1 "DHU control LedStopLampRi1
0 = OnOffNoReq_NoReq
1 = OnOffNoReq_On
2 = OnOffNoReq_Off
";
CM_ SG_ 788 DHUcontrolLedStopLampRi2 "DHU control stop lamp RI2";
CM_ SG_ 788 DHUcontrolmiddlebrakelight "DHU control middle brake light
0 = OnOffNoReq_NoReq
1 = OnOffNoReq_On
2 = OnOffNoReq_Off
";
CM_ SG_ 788 DHUcontrolmiddlecorneringlamp "DHU control middle cornering lamp
0 = OnOffNoReq_NoReq
1 = OnOffNoReq_On
2 = OnOffNoReq_Off
";
CM_ SG_ 788 DHUcontrolmiddlepositionlight "DHU control middle position light
0 = OnOffNoReq_NoReq
1 = OnOffNoReq_On
2 = OnOffNoReq_Off";
CM_ SG_ 789 DHUcontrolCrossreversinglight "DHU control Cross reversing light
0 = OnOffNoReq_NoReq
1 = OnOffNoReq_On
2 = OnOffNoReq_Off";
CM_ SG_ 789 DHUcontrolleftbrakelightLamp "DHU control left brakelight Lamp
0 = OnOffNoReq_NoReq
1 = OnOffNoReq_On
2 = OnOffNoReq_Off";
CM_ SG_ 789 DHUcontrolleftcorneringlamp "DHU control left cornering lamp request 
0 = OnOffNoReq_NoReq
1 = OnOffNoReq_On
2 = OnOffNoReq_Off

 ";
CM_ SG_ 789 DHUcontrolleftdaytimerunninglamp "DHU control left day time running lamp requrest:
0 = OnOffNoReq_NoReq
1 = OnOffNoReq_On
2 = OnOffNoReq_Off";
CM_ SG_ 789 DHUcontrolleftfroglight "DHU control left frog light";
CM_ SG_ 789 DHUcontrolleftheadcorneringlamp "DHU control left head cornering lamp:
0 = OnOffNoReq_NoReq;
1 = OnOffNoReq_On;
2 = OnOffNoReq_Off
";
CM_ SG_ 789 DHUcontrollefthighbeamlamp "DHU control left high beam lamp:
0 = OnOffNoReq_NoReq;1 = OnOffNoReq_On;2 = OnOffNoReq_Off
";
CM_ SG_ 789 DHUcontrolleftlowbeamlamp "DHU control left lowbeam lamp:
0 = OnOffNoReq_NoReq;1 = OnOffNoReq_On;2 = OnOffNoReq_Off
";
CM_ SG_ 789 DHUcontrolleftpositionlamp "DHU control left position lamp:
0 = OnOffNoReq_NoReq
1 = OnOffNoReq_On
2 = OnOffNoReq_Off
";
CM_ SG_ 789 DHUcontrolleftpositionlight "DHU control left position light
0 = OnOffNoReq_NoReq
1 = OnOffNoReq_On
2 = OnOffNoReq_Off
";
CM_ SG_ 789 DHUcontrolrightbrakelight "DHU control right brake light
0 = OnOffNoReq_NoReq
1 = OnOffNoReq_On
2 = OnOffNoReq_Off

";
CM_ SG_ 789 DHUcontrolrightcorneringlamp "DHU control right cornering lamp
0 = OnOffNoReq_NoReq
1 = OnOffNoReq_On
2 = OnOffNoReq_Off
";
CM_ SG_ 789 DHUcontrolrightdaytimerunninglamp "DHU control right daytime running lamp request:
0 = OnOffNoReq_NoReq
1 = OnOffNoReq_On
2 = OnOffNoReq_Off";
CM_ SG_ 789 DHUcontrolrightfroglight "DHU control right frog light request:
0 = OnOffNoReq_NoReq
1 = OnOffNoReq_On
2 = OnOffNoReq_Off

";
CM_ SG_ 789 DHUcontrolrighthighbeamlamp "DHU control requiment right high beam lamp:
0 = OnOffNoReq_NoReq;1 = OnOffNoReq_On;2 = OnOffNoReq_Off";
CM_ SG_ 789 DHUcontrolrightlowbeamlamp "DHU control right low beam:
0 = OnOffNoReq_NoReq;1 = OnOffNoReq_On;2 = OnOffNoReq_Off ";
CM_ SG_ 789 DHUcontrolrightpositionLamp "DHU control left brake light Lamp
0 = OnOffNoReq_NoReq
1 = OnOffNoReq_On
2 = OnOffNoReq_Off
";
CM_ SG_ 789 DHUcontrolrightrearcorneringlamp "DHU control requrement for right head cornering lamp
0 = OnOffNoReq_NoReq;1 = OnOffNoReq_On;2 = OnOffNoReq_Off";
CM_ SG_ 789 DHUcontrolrightrearpositionLamp "DHU control right position Lamp request
0 = OnOffNoReq_NoReq
1 = OnOffNoReq_On
2 = OnOffNoReq_Off

";
CM_ SG_ 1425 CEMdevelpsignalgroupreqFunctiondevpsignalgroup1 "develop signal group request";
CM_ SG_ 1425 CEMdevelpsignalgroupreqFunctiondevpsignalgroup2 "develop signal group request";
CM_ SG_ 1425 CEMdevelpsignalgroupreqFunctiondevpsignalgroup3 "develop signal group request";
CM_ SG_ 1425 CEMdevelpsignalgroupreqFunctiondevpsignalgroup4 "develop signal group request";
CM_ SG_ 1425 CEMdevelpsignalgroupreqFunctiondevpsignalgroup5 "develop signal group request";
CM_ SG_ 1425 CEMdevelpsignalgroupreqFunctiondevpsignalgroup6 "develop signal group request";
CM_ SG_ 1425 CEMdevelpsignalgroupreqFunctiondevpsignalgroup7 "develop signal group request";
CM_ SG_ 1425 CEMdevelpsignalgroupreqFunctiondevpsignalgroup8 "develop signal group request";
CM_ SG_ 593 StsOfLedHiBeamLe "Status of Led High Beam Left.";
CM_ SG_ 593 StsOfLedLoBeamLe "Status of Led Low Beam Left.";
CM_ SG_ 124 DwnLoadStsFbOfHdlampLe "Download of Dynamic light sequence Feedback signal.";
CM_ SG_ 124 ExtrLiShowActvnFrntLeFb "Activation of Exterior Light Show Feedback Frong Left Head Lamp";
CM_ SG_ 124 HdlampLeInpSts1 "Ext. Light relay input driver warning and fault tracing";
CM_ SG_ 124 HdlampLeInpSts2 "Ignition relay input driver warning and fault tracing";
CM_ SG_ 124 StsOfAfsLe "Status of AFS light distribution Left.";
CM_ SG_ 124 StsOfAhbcLe "Status of Auto High Beam Control Left.";
CM_ SG_ 124 StsOfFrntSideMkrLampLe2 "Status of Front Side Marker Lamp Left 2.";
CM_ SG_ 124 StsOfLedCornrgLampLe "Status of Led Cornering Lamp Left.";
CM_ SG_ 124 StsOfLedDaytiRunngLampLe "Status of Led Day Time Running Lamp Left.";
CM_ SG_ 124 StsOfLedFrntFogLampLe "Status of Led Front Fog Light Left.";
CM_ SG_ 124 StsOfLedFrntPosnLampLe "Status of Led Front Position Lamp Left.";
CM_ SG_ 124 StsOfLedFrntTurnIndcrLe "Status of Led Front Turn Indicator Left.";
CM_ SG_ 124 StsOfLvlgLeChks "Status of Head Lamp Leveling Motor Check Sum";
CM_ SG_ 124 StsOfLvlgLeCntr "Status of Head Lamp Leveling Motor Counter";
CM_ SG_ 124 StsOfLvlgLeStsOfLvlgLe "Status of Head Lamp Leveling Motor";
CM_ SG_ 124 StsOfSwvlgLe "Status of Bending Light Left.";
CM_ SG_ 124 StsOfTouristModLe "Status of Tourist Mode Left.";
CM_ SG_ 594 StsOfLedHiBeamRi "Status of High Beam Led Right.";
CM_ SG_ 594 StsOfLedLoBeamRi "Status of Low Beam Led Right";
CM_ SG_ 127 DwnLoadStsFbOfHdlampRi "Download of Dynamic light sequence Feedback signal.";
CM_ SG_ 127 ExtrLiShowActvnFrntRiFb "Activation of Exterior Light Show Feedback Frong Right Head Lamp";
CM_ SG_ 127 HdlampRiInpSts1 "Ext. Light relay input driver warning and fault tracing";
CM_ SG_ 127 HdlampRiInpSts2 "Ignition relay input driver warning and fault tracing";
CM_ SG_ 127 StsOfAfsRi "Status of AFS light distribution Right.";
CM_ SG_ 127 StsOfAhbcRi "Status of Auto High Beam Control Right.";
CM_ SG_ 127 StsOfFrntSideMkrLampRi2 "Status of Front Side Marker Lamp Right 2.";
CM_ SG_ 127 StsOfLedCornrgLampRi "Status of Led Cornering Lamp Right.";
CM_ SG_ 127 StsOfLedDaytiRunngLampRi "Status of Led Day Time Running Lamp Right.";
CM_ SG_ 127 StsOfLedFrntFogLampRi "Status of Led Front Fog Lamp Right.";
CM_ SG_ 127 StsOfLedFrntPosnLampRi "Status of Led Front Position Lamp Right.";
CM_ SG_ 127 StsOfLedFrntTurnIndcrRi "Status of Front Turn Right Indicator";
CM_ SG_ 127 StsOfLvlgRiChks "Status of Head Lamp Leveling Motor Check Sum";
CM_ SG_ 127 StsOfLvlgRiCntr "Status of Head Lamp Leveling Motor Counter";
CM_ SG_ 127 StsOfLvlgRiStsOfLvlgRi "Status of Head Lamp Leveling Motor";
CM_ SG_ 127 StsOfSwvlgRi "Status of Bending Light Right.";
CM_ SG_ 127 StsOfTouristModRi "Status of Tourist Mode Right.";
CM_ SG_ 592 DwnLoadStsFbOfReLampCtrlLe1 "Download Status Feedback of Rear Lamp Control Left 1";
CM_ SG_ 592 ExtrLiShowActvnReLeFb "Activation Exterior Light Show Feedback";
CM_ SG_ 592 StsOfLedPosnLampLe1 "Status of Led Position Lamp Left 1. ";
CM_ SG_ 592 StsOfLedReFogLampLe1 "Status of Led Rear Fog Lampp Left 1.";
CM_ SG_ 592 StsOfLedReLampLe1 "Status Of LED Rear Lamp Left 1.";
CM_ SG_ 592 StsOfLedRvsgLampLe1 "Status of Led Reversing Lamp left 1.";
CM_ SG_ 592 StsOfLedStopLampLe1 "Status of Led Stop Lamp Left 1.";
CM_ SG_ 592 StsOfLedTurnIndcrLe1 "Status of Led Turn Indicator Left 1.";
CM_ SG_ 596 DwnLoadStsFbOfReLampCtrlLe2 "Download status feedback of Rearlamp Left 2.";
CM_ SG_ 596 DwnLoadStsFbOfReLampCtrlRi2 "Download Status Feedback of Rear Lamp Control Right 2";
CM_ SG_ 596 ExtrLiShowActvnReLe2Fb "Activation of Exterior Light Show Feedback Rear Lamp Left 2.";
CM_ SG_ 596 ExtrLiShowActvnReRi2Fb "Activation of Exterior Light Show Feedback Rear Lamp Right 2.";
CM_ SG_ 596 StsOfLedPosnLampLe2 "Status of Led Position Lamp Left 2.";
CM_ SG_ 596 StsOfLedPosnLampRi2 "Status of Led Position Lamp Right 2.";
CM_ SG_ 596 StsOfLedReFogLampLe2 "Status of Led Rear Fog Lamp Left 2.";
CM_ SG_ 596 StsOfLedReFogLampRi2 "Status of Led Rear Fog Lamp Right 2.";
CM_ SG_ 596 StsOfLedReLampLe2 "Status Of LED Rear Lamp Left 2.";
CM_ SG_ 596 StsOfLedReLampRi2 "Status Of LED Rear Lamp Right 2.";
CM_ SG_ 596 StsOfLedRvsgLampLe2 "Status of Led Reversing Lamp Left 2.";
CM_ SG_ 596 StsOfLedRvsgLampRi2 "Status of Led Reversing Lamp Right 2.";
CM_ SG_ 596 StsOfLedStopLampLe2 "Status of Led Stop Lamp Left 2.";
CM_ SG_ 596 StsOfLedStopLampRi2 "Status of Led Stop Lamp Right 2.";
CM_ SG_ 596 StsOfLedTurnIndcrLe2 "Status of Led Turn Indicator Left 2.";
CM_ SG_ 596 StsOfLedTurnIndcrRi2 "Status of Led Turn Indicator Right 2.";
CM_ SG_ 608 DwnLoadStsFbOfReLampCtrlRi1 "Download Status Feedback of Rear Lamp Control Right 1";
CM_ SG_ 608 ExtrLiShowActvnReRiFb "Activation Exterior Light Show Feedback";
CM_ SG_ 608 StsOfLedPosnLampRi1 "Status of Led Position Lamp Right 1. ";
CM_ SG_ 608 StsOfLedReFogLampRi1 "Status of Led Rear Fog Lamp Right. ";
CM_ SG_ 608 StsOfLedReLampRi1 "Status Of LED Rear Lamp Right 1.";
CM_ SG_ 608 StsOfLedRvsgLampRi1 "Status of Led Reversing Lamp 1.";
CM_ SG_ 608 StsOfLedStopLampRi1 "Status of Led Stop Lamp Right 1. ";
CM_ SG_ 608 StsOfLedTurnIndcrRi1 "Status of Led Turn Indicator Right 1.";
BA_DEF_ BO_ "GenMsgSendType" ENUM "cyclic", "spontaneous", "not-used", "not-used", "not-used", "cyclicAndSpontaneous", "not-used", "cyclicIfActive", "NoMsgSendType"; // [us]
BA_DEF_ BO_ "GenMsgCycleTime" INT 0 65536; // [ms]
BA_DEF_ BO_ "GenMsgStartDelayTime" INT 0 65536; // [ms]
BA_DEF_ BO_ "GenMsgDelayTime" INT 0 65536; // [ms]
BA_DEF_ SG_ "GenSigSendType" ENUM "Cyclic","OnWrite","OnWriteWithRepetition","OnChange","OnChangeWithRepetition","IfActive","IfActiveWithRepetition","NoSigSendType";
BA_DEF_ SG_ "GenSigStartValue" HEX 0 80000000;
BA_DEF_ BO_ "GenMsgILSupport" ENUM "No","Yes";
BA_DEF_ BO_ "NmAsrMessage" ENUM "No","Yes";
BA_DEF_ SG_ "GenSigFuncType" ENUM "NoFunction","n/a","n/a","n/a","n/a","n/a","n/a","n/a","n/a","n/a","n/a","n/a","n/a","n/a","n/a","CHK","CNTR","n/a","n/a","n/a","CNTR_AR_01","CRC_AR_01_BOTH","CRC_AR_01_ALT","CRC_AR_01_LOW","CRC_AR_01_NIBBLE","CNTR_AR_04","CRC_AR_04A","CNTR_AR_05","CRC_AR_05";
BA_DEF_ SG_ "GenSigDataID" STRING;
BA_DEF_ SG_ "SigGroup" STRING;

BA_DEF_DEF_ "GenSigStartValue" 0;
BA_DEF_DEF_ "GenSigSendType" "NoSigSendType";
BA_DEF_DEF_ "GenMsgCycleTime" 0;
BA_DEF_DEF_ "GenMsgDelayTime" 0;
BA_DEF_DEF_ "GenMsgStartDelayTime" 0;
BA_DEF_DEF_ "GenMsgSendType" "NoMsgSendType";
BA_DEF_DEF_ "GenMsgILSupport" "Yes";
BA_DEF_DEF_ "NmAsrMessage" "No";
BA_DEF_DEF_ "GenSigFuncType" "NoFunction";
BA_DEF_DEF_ "GenSigDataID" "";
BA_DEF_DEF_ "SigGroup" "";
// Frame: CemBodyExpoFr27
BA_ "GenMsgSendType" BO_ 312 1;
BA_ "GenMsgDelayTime" BO_ 312 30.000;
BA_ "GenSigSendType" SG_ 312 DwnLoadDynLitPrmForLedLoBeamLeContTiPrm 1;
BA_ "GenSigSendType" SG_ 312 DwnLoadDynLitPrmForLedLoBeamLeLowBriPrm 1;
BA_ "GenSigSendType" SG_ 312 DwnLoadDynLitPrmForLedLoBeamLeModePrm 1;
BA_ "GenSigSendType" SG_ 312 DwnLoadDynLitPrmForLedLoBeamLeOffsTiPrm 1;
BA_ "GenSigSendType" SG_ 312 DwnLoadDynLitPrmForLedLoBeamLeTistamp 1;
BA_ "GenSigSendType" SG_ 312 DwnLoadDynLitPrmForLedLoBeamLeUpprBriPrm 1;
// Frame: CemBodyExpoFr28
BA_ "GenMsgSendType" BO_ 313 1;
BA_ "GenMsgDelayTime" BO_ 313 30.000;
BA_ "GenSigSendType" SG_ 313 DwnLoadDynLtgPrmForLedAllWthrLampLeContTiPrm 1;
BA_ "SigGroup" SG_ 313 DwnLoadDynLtgPrmForLedAllWthrLampLeContTiPrm "DwnLoadDynLtgPrmForLedAllWthrLampLe";
BA_ "GenSigSendType" SG_ 313 DwnLoadDynLtgPrmForLedAllWthrLampLeLowBriPrm 1;
BA_ "SigGroup" SG_ 313 DwnLoadDynLtgPrmForLedAllWthrLampLeLowBriPrm "DwnLoadDynLtgPrmForLedAllWthrLampLe";
BA_ "GenSigSendType" SG_ 313 DwnLoadDynLtgPrmForLedAllWthrLampLeModePrm 1;
BA_ "SigGroup" SG_ 313 DwnLoadDynLtgPrmForLedAllWthrLampLeModePrm "DwnLoadDynLtgPrmForLedAllWthrLampLe";
BA_ "GenSigSendType" SG_ 313 DwnLoadDynLtgPrmForLedAllWthrLampLeOffsTiPrm 1;
BA_ "SigGroup" SG_ 313 DwnLoadDynLtgPrmForLedAllWthrLampLeOffsTiPrm "DwnLoadDynLtgPrmForLedAllWthrLampLe";
BA_ "GenSigSendType" SG_ 313 DwnLoadDynLtgPrmForLedAllWthrLampLeTistamp 1;
BA_ "SigGroup" SG_ 313 DwnLoadDynLtgPrmForLedAllWthrLampLeTistamp "DwnLoadDynLtgPrmForLedAllWthrLampLe";
BA_ "GenSigSendType" SG_ 313 DwnLoadDynLtgPrmForLedAllWthrLampLeUpprBriPrm 1;
BA_ "SigGroup" SG_ 313 DwnLoadDynLtgPrmForLedAllWthrLampLeUpprBriPrm "DwnLoadDynLtgPrmForLedAllWthrLampLe";
// Frame: CemBodyExpoFr29
BA_ "GenMsgSendType" BO_ 314 1;
BA_ "GenMsgDelayTime" BO_ 314 30.000;
BA_ "GenSigSendType" SG_ 314 DwnLoadDynLtgPrmForLedAllWthrLampRiContTiPrm 1;
BA_ "SigGroup" SG_ 314 DwnLoadDynLtgPrmForLedAllWthrLampRiContTiPrm "DwnLoadDynLtgPrmForLedAllWthrLampRi";
BA_ "GenSigSendType" SG_ 314 DwnLoadDynLtgPrmForLedAllWthrLampRiLowBriPrm 1;
BA_ "SigGroup" SG_ 314 DwnLoadDynLtgPrmForLedAllWthrLampRiLowBriPrm "DwnLoadDynLtgPrmForLedAllWthrLampRi";
BA_ "GenSigSendType" SG_ 314 DwnLoadDynLtgPrmForLedAllWthrLampRiModePrm 1;
BA_ "SigGroup" SG_ 314 DwnLoadDynLtgPrmForLedAllWthrLampRiModePrm "DwnLoadDynLtgPrmForLedAllWthrLampRi";
BA_ "GenSigSendType" SG_ 314 DwnLoadDynLtgPrmForLedAllWthrLampRiOffsTiPrm 1;
BA_ "SigGroup" SG_ 314 DwnLoadDynLtgPrmForLedAllWthrLampRiOffsTiPrm "DwnLoadDynLtgPrmForLedAllWthrLampRi";
BA_ "GenSigSendType" SG_ 314 DwnLoadDynLtgPrmForLedAllWthrLampRiTistamp 1;
BA_ "SigGroup" SG_ 314 DwnLoadDynLtgPrmForLedAllWthrLampRiTistamp "DwnLoadDynLtgPrmForLedAllWthrLampRi";
BA_ "GenSigSendType" SG_ 314 DwnLoadDynLtgPrmForLedAllWthrLampRiUpprBriPrm 1;
BA_ "SigGroup" SG_ 314 DwnLoadDynLtgPrmForLedAllWthrLampRiUpprBriPrm "DwnLoadDynLtgPrmForLedAllWthrLampRi";
// Frame: CemBodyExpoFr30
BA_ "GenMsgSendType" BO_ 315 1;
BA_ "GenMsgDelayTime" BO_ 315 30.000;
BA_ "GenSigSendType" SG_ 315 DwnLoadDynLtgPrmForLedCornrgLampLeContTiPrm 1;
BA_ "SigGroup" SG_ 315 DwnLoadDynLtgPrmForLedCornrgLampLeContTiPrm "DwnLoadDynLtgPrmForLedCornrgLampLe";
BA_ "GenSigSendType" SG_ 315 DwnLoadDynLtgPrmForLedCornrgLampLeLowBriPrm 1;
BA_ "SigGroup" SG_ 315 DwnLoadDynLtgPrmForLedCornrgLampLeLowBriPrm "DwnLoadDynLtgPrmForLedCornrgLampLe";
BA_ "GenSigSendType" SG_ 315 DwnLoadDynLtgPrmForLedCornrgLampLeModePrm 1;
BA_ "SigGroup" SG_ 315 DwnLoadDynLtgPrmForLedCornrgLampLeModePrm "DwnLoadDynLtgPrmForLedCornrgLampLe";
BA_ "GenSigSendType" SG_ 315 DwnLoadDynLtgPrmForLedCornrgLampLeOffsTiPrm 1;
BA_ "SigGroup" SG_ 315 DwnLoadDynLtgPrmForLedCornrgLampLeOffsTiPrm "DwnLoadDynLtgPrmForLedCornrgLampLe";
BA_ "GenSigSendType" SG_ 315 DwnLoadDynLtgPrmForLedCornrgLampLeTistamp 1;
BA_ "SigGroup" SG_ 315 DwnLoadDynLtgPrmForLedCornrgLampLeTistamp "DwnLoadDynLtgPrmForLedCornrgLampLe";
BA_ "GenSigSendType" SG_ 315 DwnLoadDynLtgPrmForLedCornrgLampLeUpprBriPrm 1;
BA_ "SigGroup" SG_ 315 DwnLoadDynLtgPrmForLedCornrgLampLeUpprBriPrm "DwnLoadDynLtgPrmForLedCornrgLampLe";
// Frame: CemBodyExpoFr31
BA_ "GenMsgSendType" BO_ 316 1;
BA_ "GenMsgDelayTime" BO_ 316 30.000;
BA_ "GenSigSendType" SG_ 316 DwnLoadDynLtgPrmForLedCornrgLampRiContTiPrm 1;
BA_ "SigGroup" SG_ 316 DwnLoadDynLtgPrmForLedCornrgLampRiContTiPrm "DwnLoadDynLtgPrmForLedCornrgLampRi";
BA_ "GenSigSendType" SG_ 316 DwnLoadDynLtgPrmForLedCornrgLampRiLowBriPrm 1;
BA_ "SigGroup" SG_ 316 DwnLoadDynLtgPrmForLedCornrgLampRiLowBriPrm "DwnLoadDynLtgPrmForLedCornrgLampRi";
BA_ "GenSigSendType" SG_ 316 DwnLoadDynLtgPrmForLedCornrgLampRiModePrm 1;
BA_ "SigGroup" SG_ 316 DwnLoadDynLtgPrmForLedCornrgLampRiModePrm "DwnLoadDynLtgPrmForLedCornrgLampRi";
BA_ "GenSigSendType" SG_ 316 DwnLoadDynLtgPrmForLedCornrgLampRiOffsTiPrm 1;
BA_ "SigGroup" SG_ 316 DwnLoadDynLtgPrmForLedCornrgLampRiOffsTiPrm "DwnLoadDynLtgPrmForLedCornrgLampRi";
BA_ "GenSigSendType" SG_ 316 DwnLoadDynLtgPrmForLedCornrgLampRiTistamp 1;
BA_ "SigGroup" SG_ 316 DwnLoadDynLtgPrmForLedCornrgLampRiTistamp "DwnLoadDynLtgPrmForLedCornrgLampRi";
BA_ "GenSigSendType" SG_ 316 DwnLoadDynLtgPrmForLedCornrgLampRiUpprBriPrm 1;
BA_ "SigGroup" SG_ 316 DwnLoadDynLtgPrmForLedCornrgLampRiUpprBriPrm "DwnLoadDynLtgPrmForLedCornrgLampRi";
// Frame: CemBodyExpoFr32
BA_ "GenMsgSendType" BO_ 317 1;
BA_ "GenMsgDelayTime" BO_ 317 30.000;
BA_ "GenSigSendType" SG_ 317 DwnLoadDynLtgPrmForLedDaytiRunngLampLeContTiPrm 1;
BA_ "SigGroup" SG_ 317 DwnLoadDynLtgPrmForLedDaytiRunngLampLeContTiPrm "DwnLoadDynLtgPrmForLedDaytiRunngLampLe";
BA_ "GenSigSendType" SG_ 317 DwnLoadDynLtgPrmForLedDaytiRunngLampLeLowBriPrm 1;
BA_ "SigGroup" SG_ 317 DwnLoadDynLtgPrmForLedDaytiRunngLampLeLowBriPrm "DwnLoadDynLtgPrmForLedDaytiRunngLampLe";
BA_ "GenSigSendType" SG_ 317 DwnLoadDynLtgPrmForLedDaytiRunngLampLeModePrm 1;
BA_ "SigGroup" SG_ 317 DwnLoadDynLtgPrmForLedDaytiRunngLampLeModePrm "DwnLoadDynLtgPrmForLedDaytiRunngLampLe";
BA_ "GenSigSendType" SG_ 317 DwnLoadDynLtgPrmForLedDaytiRunngLampLeOffsTiPrm 1;
BA_ "SigGroup" SG_ 317 DwnLoadDynLtgPrmForLedDaytiRunngLampLeOffsTiPrm "DwnLoadDynLtgPrmForLedDaytiRunngLampLe";
BA_ "GenSigSendType" SG_ 317 DwnLoadDynLtgPrmForLedDaytiRunngLampLeTistamp 1;
BA_ "SigGroup" SG_ 317 DwnLoadDynLtgPrmForLedDaytiRunngLampLeTistamp "DwnLoadDynLtgPrmForLedDaytiRunngLampLe";
BA_ "GenSigSendType" SG_ 317 DwnLoadDynLtgPrmForLedDaytiRunngLampLeUpprBriPrm 1;
BA_ "SigGroup" SG_ 317 DwnLoadDynLtgPrmForLedDaytiRunngLampLeUpprBriPrm "DwnLoadDynLtgPrmForLedDaytiRunngLampLe";
// Frame: CemBodyExpoFr33
BA_ "GenMsgSendType" BO_ 318 1;
BA_ "GenMsgDelayTime" BO_ 318 30.000;
BA_ "GenSigSendType" SG_ 318 DwnLoadDynLtgPrmForLedDaytiRunngLampRiContTiPrm 1;
BA_ "SigGroup" SG_ 318 DwnLoadDynLtgPrmForLedDaytiRunngLampRiContTiPrm "DwnLoadDynLtgPrmForLedDaytiRunngLampRi";
BA_ "GenSigSendType" SG_ 318 DwnLoadDynLtgPrmForLedDaytiRunngLampRiLowBriPrm 1;
BA_ "SigGroup" SG_ 318 DwnLoadDynLtgPrmForLedDaytiRunngLampRiLowBriPrm "DwnLoadDynLtgPrmForLedDaytiRunngLampRi";
BA_ "GenSigSendType" SG_ 318 DwnLoadDynLtgPrmForLedDaytiRunngLampRiModePrm 1;
BA_ "SigGroup" SG_ 318 DwnLoadDynLtgPrmForLedDaytiRunngLampRiModePrm "DwnLoadDynLtgPrmForLedDaytiRunngLampRi";
BA_ "GenSigSendType" SG_ 318 DwnLoadDynLtgPrmForLedDaytiRunngLampRiOffsTiPrm 1;
BA_ "SigGroup" SG_ 318 DwnLoadDynLtgPrmForLedDaytiRunngLampRiOffsTiPrm "DwnLoadDynLtgPrmForLedDaytiRunngLampRi";
BA_ "GenSigSendType" SG_ 318 DwnLoadDynLtgPrmForLedDaytiRunngLampRiTistamp 1;
BA_ "SigGroup" SG_ 318 DwnLoadDynLtgPrmForLedDaytiRunngLampRiTistamp "DwnLoadDynLtgPrmForLedDaytiRunngLampRi";
BA_ "GenSigSendType" SG_ 318 DwnLoadDynLtgPrmForLedDaytiRunngLampRiUpprBriPrm 1;
BA_ "SigGroup" SG_ 318 DwnLoadDynLtgPrmForLedDaytiRunngLampRiUpprBriPrm "DwnLoadDynLtgPrmForLedDaytiRunngLampRi";
// Frame: CemBodyExpoFr34
BA_ "GenMsgSendType" BO_ 319 1;
BA_ "GenMsgDelayTime" BO_ 319 30.000;
BA_ "GenSigSendType" SG_ 319 DwnLoadDynLtgPrmForLedFrntPosnLampLeContTiPrm 1;
BA_ "SigGroup" SG_ 319 DwnLoadDynLtgPrmForLedFrntPosnLampLeContTiPrm "DwnLoadDynLtgPrmForLedFrntPosnLampLe";
BA_ "GenSigSendType" SG_ 319 DwnLoadDynLtgPrmForLedFrntPosnLampLeLowBriPrm 1;
BA_ "SigGroup" SG_ 319 DwnLoadDynLtgPrmForLedFrntPosnLampLeLowBriPrm "DwnLoadDynLtgPrmForLedFrntPosnLampLe";
BA_ "GenSigSendType" SG_ 319 DwnLoadDynLtgPrmForLedFrntPosnLampLeModePrm 1;
BA_ "SigGroup" SG_ 319 DwnLoadDynLtgPrmForLedFrntPosnLampLeModePrm "DwnLoadDynLtgPrmForLedFrntPosnLampLe";
BA_ "GenSigSendType" SG_ 319 DwnLoadDynLtgPrmForLedFrntPosnLampLeOffsTiPrm 1;
BA_ "SigGroup" SG_ 319 DwnLoadDynLtgPrmForLedFrntPosnLampLeOffsTiPrm "DwnLoadDynLtgPrmForLedFrntPosnLampLe";
BA_ "GenSigSendType" SG_ 319 DwnLoadDynLtgPrmForLedFrntPosnLampLeTistamp 1;
BA_ "SigGroup" SG_ 319 DwnLoadDynLtgPrmForLedFrntPosnLampLeTistamp "DwnLoadDynLtgPrmForLedFrntPosnLampLe";
BA_ "GenSigSendType" SG_ 319 DwnLoadDynLtgPrmForLedFrntPosnLampLeUpprBriPrm 1;
BA_ "SigGroup" SG_ 319 DwnLoadDynLtgPrmForLedFrntPosnLampLeUpprBriPrm "DwnLoadDynLtgPrmForLedFrntPosnLampLe";
// Frame: CemBodyExpoFr35
BA_ "GenMsgSendType" BO_ 320 1;
BA_ "GenMsgDelayTime" BO_ 320 30.000;
BA_ "GenSigSendType" SG_ 320 DwnLoadDynLtgPrmForLedFrntPosnLampRiContTiPrm 1;
BA_ "SigGroup" SG_ 320 DwnLoadDynLtgPrmForLedFrntPosnLampRiContTiPrm "DwnLoadDynLtgPrmForLedFrntPosnLampRi";
BA_ "GenSigSendType" SG_ 320 DwnLoadDynLtgPrmForLedFrntPosnLampRiLowBriPrm 1;
BA_ "SigGroup" SG_ 320 DwnLoadDynLtgPrmForLedFrntPosnLampRiLowBriPrm "DwnLoadDynLtgPrmForLedFrntPosnLampRi";
BA_ "GenSigSendType" SG_ 320 DwnLoadDynLtgPrmForLedFrntPosnLampRiModePrm 1;
BA_ "SigGroup" SG_ 320 DwnLoadDynLtgPrmForLedFrntPosnLampRiModePrm "DwnLoadDynLtgPrmForLedFrntPosnLampRi";
BA_ "GenSigSendType" SG_ 320 DwnLoadDynLtgPrmForLedFrntPosnLampRiOffsTiPrm 1;
BA_ "SigGroup" SG_ 320 DwnLoadDynLtgPrmForLedFrntPosnLampRiOffsTiPrm "DwnLoadDynLtgPrmForLedFrntPosnLampRi";
BA_ "GenSigSendType" SG_ 320 DwnLoadDynLtgPrmForLedFrntPosnLampRiTistamp 1;
BA_ "SigGroup" SG_ 320 DwnLoadDynLtgPrmForLedFrntPosnLampRiTistamp "DwnLoadDynLtgPrmForLedFrntPosnLampRi";
BA_ "GenSigSendType" SG_ 320 DwnLoadDynLtgPrmForLedFrntPosnLampRiUpprBriPrm 1;
BA_ "SigGroup" SG_ 320 DwnLoadDynLtgPrmForLedFrntPosnLampRiUpprBriPrm "DwnLoadDynLtgPrmForLedFrntPosnLampRi";
// Frame: CemBodyExpoFr36
BA_ "GenMsgSendType" BO_ 321 1;
BA_ "GenMsgDelayTime" BO_ 321 30.000;
BA_ "GenSigSendType" SG_ 321 DwnLoadDynLtgPrmForLedFrntTurnIndcrLeContTiPrm 1;
BA_ "SigGroup" SG_ 321 DwnLoadDynLtgPrmForLedFrntTurnIndcrLeContTiPrm "DwnLoadDynLtgPrmForLedFrntTurnIndcrLe";
BA_ "GenSigSendType" SG_ 321 DwnLoadDynLtgPrmForLedFrntTurnIndcrLeLowBriPrm 1;
BA_ "SigGroup" SG_ 321 DwnLoadDynLtgPrmForLedFrntTurnIndcrLeLowBriPrm "DwnLoadDynLtgPrmForLedFrntTurnIndcrLe";
BA_ "GenSigSendType" SG_ 321 DwnLoadDynLtgPrmForLedFrntTurnIndcrLeModePrm 1;
BA_ "SigGroup" SG_ 321 DwnLoadDynLtgPrmForLedFrntTurnIndcrLeModePrm "DwnLoadDynLtgPrmForLedFrntTurnIndcrLe";
BA_ "GenSigSendType" SG_ 321 DwnLoadDynLtgPrmForLedFrntTurnIndcrLeOffsTiPrm 1;
BA_ "SigGroup" SG_ 321 DwnLoadDynLtgPrmForLedFrntTurnIndcrLeOffsTiPrm "DwnLoadDynLtgPrmForLedFrntTurnIndcrLe";
BA_ "GenSigSendType" SG_ 321 DwnLoadDynLtgPrmForLedFrntTurnIndcrLeTistamp 1;
BA_ "SigGroup" SG_ 321 DwnLoadDynLtgPrmForLedFrntTurnIndcrLeTistamp "DwnLoadDynLtgPrmForLedFrntTurnIndcrLe";
BA_ "GenSigSendType" SG_ 321 DwnLoadDynLtgPrmForLedFrntTurnIndcrLeUpprBriPrm 1;
BA_ "SigGroup" SG_ 321 DwnLoadDynLtgPrmForLedFrntTurnIndcrLeUpprBriPrm "DwnLoadDynLtgPrmForLedFrntTurnIndcrLe";
// Frame: CemBodyExpoFr37
BA_ "GenMsgSendType" BO_ 322 1;
BA_ "GenMsgDelayTime" BO_ 322 30.000;
BA_ "GenSigSendType" SG_ 322 DwnLoadDynLtgPrmForLedFrntTurnIndcrRiContTiPrm 1;
BA_ "SigGroup" SG_ 322 DwnLoadDynLtgPrmForLedFrntTurnIndcrRiContTiPrm "DwnLoadDynLtgPrmForLedFrntTurnIndcrRi";
BA_ "GenSigSendType" SG_ 322 DwnLoadDynLtgPrmForLedFrntTurnIndcrRiLowBriPrm 1;
BA_ "SigGroup" SG_ 322 DwnLoadDynLtgPrmForLedFrntTurnIndcrRiLowBriPrm "DwnLoadDynLtgPrmForLedFrntTurnIndcrRi";
BA_ "GenSigSendType" SG_ 322 DwnLoadDynLtgPrmForLedFrntTurnIndcrRiModePrm 1;
BA_ "SigGroup" SG_ 322 DwnLoadDynLtgPrmForLedFrntTurnIndcrRiModePrm "DwnLoadDynLtgPrmForLedFrntTurnIndcrRi";
BA_ "GenSigSendType" SG_ 322 DwnLoadDynLtgPrmForLedFrntTurnIndcrRiOffsTiPrm 1;
BA_ "SigGroup" SG_ 322 DwnLoadDynLtgPrmForLedFrntTurnIndcrRiOffsTiPrm "DwnLoadDynLtgPrmForLedFrntTurnIndcrRi";
BA_ "GenSigSendType" SG_ 322 DwnLoadDynLtgPrmForLedFrntTurnIndcrRiTistamp 1;
BA_ "SigGroup" SG_ 322 DwnLoadDynLtgPrmForLedFrntTurnIndcrRiTistamp "DwnLoadDynLtgPrmForLedFrntTurnIndcrRi";
BA_ "GenSigSendType" SG_ 322 DwnLoadDynLtgPrmForLedFrntTurnIndcrRiUpprBriPrm 1;
BA_ "SigGroup" SG_ 322 DwnLoadDynLtgPrmForLedFrntTurnIndcrRiUpprBriPrm "DwnLoadDynLtgPrmForLedFrntTurnIndcrRi";
// Frame: CemBodyExpoFr38
BA_ "GenMsgSendType" BO_ 323 1;
BA_ "GenMsgDelayTime" BO_ 323 30.000;
BA_ "GenSigSendType" SG_ 323 DwnLoadDynLtgPrmForLedHiBeamRiContTiPrm 1;
BA_ "GenSigSendType" SG_ 323 DwnLoadDynLtgPrmForLedHiBeamRiLowBriPrm 1;
BA_ "GenSigSendType" SG_ 323 DwnLoadDynLtgPrmForLedHiBeamRiModePrm 1;
BA_ "GenSigSendType" SG_ 323 DwnLoadDynLtgPrmForLedHiBeamRiOffsTiPrm 1;
BA_ "GenSigSendType" SG_ 323 DwnLoadDynLtgPrmForLedHiBeamRiTistamp 1;
BA_ "GenSigSendType" SG_ 323 DwnLoadDynLtgPrmForLedHiBeamRiUpprBriPrm 1;
// Frame: CemBodyExpoFr41
BA_ "GenMsgSendType" BO_ 377 0;
BA_ "GenMsgCycleTime" BO_ 377 65.000;
BA_ "GenSigSendType" SG_ 377 ADataRawSafeALat 0;
BA_ "GenSigStartValue" SG_ 377 ADataRawSafeALat1Qf 1;
BA_ "GenSigSendType" SG_ 377 ADataRawSafeALat1Qf 0;
BA_ "GenSigSendType" SG_ 377 ADataRawSafeALgt 0;
BA_ "GenSigStartValue" SG_ 377 ADataRawSafeALgt1Qf 1;
BA_ "GenSigSendType" SG_ 377 ADataRawSafeALgt1Qf 0;
BA_ "GenSigStartValue" SG_ 377 ADataRawSafeAVert 1155.059;
BA_ "GenSigSendType" SG_ 377 ADataRawSafeAVert 0;
BA_ "GenSigStartValue" SG_ 377 ADataRawSafeAVertQf 1;
BA_ "GenSigSendType" SG_ 377 ADataRawSafeAVertQf 0;
BA_ "GenSigStartValue" SG_ 377 ADataRawSafeChks 255;
BA_ "GenSigSendType" SG_ 377 ADataRawSafeChks 0;
BA_ "GenSigFuncType" SG_ 377 ADataRawSafeChks 15;
BA_ "GenSigDataID" SG_ 377 ADataRawSafeChks "0x22";
BA_ "GenSigSendType" SG_ 377 ADataRawSafeCntr 0;
BA_ "GenSigFuncType" SG_ 377 ADataRawSafeCntr 16;
// Frame: CemBodyExpoFr42
BA_ "GenMsgSendType" BO_ 381 0;
BA_ "GenMsgCycleTime" BO_ 381 65.000;
BA_ "GenSigSendType" SG_ 381 ActnOfLedGrilleLampDyn 0;
BA_ "GenSigSendType" SG_ 381 ActnOfLedPosnLampDyn 0;
BA_ "GenSigStartValue" SG_ 381 AgDataRawSafeChks 255;
BA_ "GenSigSendType" SG_ 381 AgDataRawSafeChks 0;
BA_ "GenSigFuncType" SG_ 381 AgDataRawSafeChks 15;
BA_ "GenSigDataID" SG_ 381 AgDataRawSafeChks "0x23";
BA_ "GenSigSendType" SG_ 381 AgDataRawSafeCntr 0;
BA_ "GenSigFuncType" SG_ 381 AgDataRawSafeCntr 16;
BA_ "GenSigSendType" SG_ 381 AgDataRawSafeRollRate 0;
BA_ "GenSigStartValue" SG_ 381 AgDataRawSafeRollRateQf 1;
BA_ "GenSigSendType" SG_ 381 AgDataRawSafeRollRateQf 0;
BA_ "GenSigSendType" SG_ 381 AgDataRawSafeYawRate 0;
BA_ "GenSigStartValue" SG_ 381 AgDataRawSafeYawRateQf 1;
BA_ "GenSigSendType" SG_ 381 AgDataRawSafeYawRateQf 0;
// Frame: CemBodyExpoFr45
BA_ "GenMsgSendType" BO_ 612 0;
BA_ "GenMsgCycleTime" BO_ 612 65.000;
BA_ "GenSigSendType" SG_ 612 BrkPedlValBrkPedlVal 0;
BA_ "GenSigStartValue" SG_ 612 BrkPedlValQf 1;
BA_ "GenSigSendType" SG_ 612 BrkPedlValQf 0;
BA_ "GenSigSendType" SG_ 612 LitArea 0;
BA_ "GenSigSendType" SG_ 612 WipgInfoWipgSpdInfo 0;
BA_ "GenSigSendType" SG_ 612 WipgInfoWiprActv 0;
BA_ "GenSigSendType" SG_ 612 WipgInfoWiprInWipgAr 0;
// Frame: CemBodyExpoFr48
BA_ "GenMsgSendType" BO_ 324 1;
BA_ "GenMsgDelayTime" BO_ 324 30.000;
BA_ "GenSigSendType" SG_ 324 DwnLoadDynLitPrmForLedMkrLampRi2ContTiPrm 1;
BA_ "SigGroup" SG_ 324 DwnLoadDynLitPrmForLedMkrLampRi2ContTiPrm "DwnLoadDynLitPrmForLedMkrLampRi2";
BA_ "GenSigSendType" SG_ 324 DwnLoadDynLitPrmForLedMkrLampRi2LowBriPrm 1;
BA_ "SigGroup" SG_ 324 DwnLoadDynLitPrmForLedMkrLampRi2LowBriPrm "DwnLoadDynLitPrmForLedMkrLampRi2";
BA_ "GenSigSendType" SG_ 324 DwnLoadDynLitPrmForLedMkrLampRi2ModePrm 1;
BA_ "SigGroup" SG_ 324 DwnLoadDynLitPrmForLedMkrLampRi2ModePrm "DwnLoadDynLitPrmForLedMkrLampRi2";
BA_ "GenSigSendType" SG_ 324 DwnLoadDynLitPrmForLedMkrLampRi2OffsTiPrm 1;
BA_ "SigGroup" SG_ 324 DwnLoadDynLitPrmForLedMkrLampRi2OffsTiPrm "DwnLoadDynLitPrmForLedMkrLampRi2";
BA_ "GenSigSendType" SG_ 324 DwnLoadDynLitPrmForLedMkrLampRi2Tistamp 1;
BA_ "SigGroup" SG_ 324 DwnLoadDynLitPrmForLedMkrLampRi2Tistamp "DwnLoadDynLitPrmForLedMkrLampRi2";
BA_ "GenSigSendType" SG_ 324 DwnLoadDynLitPrmForLedMkrLampRi2UpprBriPrm 1;
BA_ "SigGroup" SG_ 324 DwnLoadDynLitPrmForLedMkrLampRi2UpprBriPrm "DwnLoadDynLitPrmForLedMkrLampRi2";
// Frame: CemBodyExpoFr49
BA_ "GenMsgSendType" BO_ 325 1;
BA_ "GenMsgDelayTime" BO_ 325 30.000;
BA_ "GenSigSendType" SG_ 325 DwnLoadDynLitPrmLedRvsgLampRi2ContTiPrm 1;
BA_ "GenSigSendType" SG_ 325 DwnLoadDynLitPrmLedRvsgLampRi2LowBriPrm 1;
BA_ "GenSigSendType" SG_ 325 DwnLoadDynLitPrmLedRvsgLampRi2ModePrm 1;
BA_ "GenSigSendType" SG_ 325 DwnLoadDynLitPrmLedRvsgLampRi2OffsTiPrm 1;
BA_ "GenSigSendType" SG_ 325 DwnLoadDynLitPrmLedRvsgLampRi2Tistamp 1;
BA_ "GenSigSendType" SG_ 325 DwnLoadDynLitPrmLedRvsgLampRi2UpprBriPrm 1;
// Frame: CemBodyExpoFr50
BA_ "GenMsgSendType" BO_ 522 0;
BA_ "GenMsgCycleTime" BO_ 522 50.000;
BA_ "GenSigSendType" SG_ 522 ActnOfLedCornrgLampLe 0;
BA_ "GenSigSendType" SG_ 522 ActnOfLedCornrgLampRi 0;
BA_ "GenSigSendType" SG_ 522 ActnOfLedDaytiRunngLamp 0;
BA_ "GenSigSendType" SG_ 522 ActnOfLedFrntFogLamp 0;
BA_ "GenSigSendType" SG_ 522 ActnOfLedHiBeam 0;
BA_ "GenSigSendType" SG_ 522 ActnOfLedLoBeamActnOfLedLoBeam 0;
BA_ "GenSigSendType" SG_ 522 ActnOfLedLoBeamChks 0;
BA_ "GenSigFuncType" SG_ 522 ActnOfLedLoBeamChks 15;
BA_ "GenSigDataID" SG_ 522 ActnOfLedLoBeamChks "0x441";
BA_ "GenSigSendType" SG_ 522 ActnOfLedLoBeamCntr 0;
BA_ "GenSigFuncType" SG_ 522 ActnOfLedLoBeamCntr 16;
BA_ "GenSigSendType" SG_ 522 ActnOfLedPosnLamp 0;
BA_ "GenSigSendType" SG_ 522 ActnOfLedReFogLamp 0;
BA_ "GenSigSendType" SG_ 522 ActnOfLedRvsgLamp 0;
BA_ "GenSigSendType" SG_ 522 ActnOfLedStopLampActnOfLedStopLamp 0;
BA_ "GenSigSendType" SG_ 522 ActnOfLedStopLampChks 0;
BA_ "GenSigFuncType" SG_ 522 ActnOfLedStopLampChks 15;
BA_ "GenSigDataID" SG_ 522 ActnOfLedStopLampChks "0x443";
BA_ "GenSigSendType" SG_ 522 ActnOfLedStopLampCntr 0;
BA_ "GenSigFuncType" SG_ 522 ActnOfLedStopLampCntr 16;
BA_ "GenSigSendType" SG_ 522 ActvnOfAfs 0;
BA_ "GenSigSendType" SG_ 522 ActvnOfAhbc 0;
BA_ "GenSigSendType" SG_ 522 ActvnOfAhl 0;
BA_ "GenSigSendType" SG_ 522 ActvnOfBrkLi 0;
BA_ "GenSigSendType" SG_ 522 ActvnOfDbl 0;
BA_ "GenSigSendType" SG_ 522 ActvnOfGoodByeLi 0;
BA_ "GenSigSendType" SG_ 522 ActvnOfTouristMod 0;
BA_ "GenSigSendType" SG_ 522 ActvnOfWelcomeLi 0;
// Frame: CemBodyExpoFr51
BA_ "GenMsgSendType" BO_ 538 0;
BA_ "GenMsgCycleTime" BO_ 538 20.000;
BA_ "GenSigSendType" SG_ 538 ActvnOfIndcrIndcrOut 0;
BA_ "GenSigSendType" SG_ 538 ActvnOfIndcrIndcrOutChks 0;
BA_ "GenSigFuncType" SG_ 538 ActvnOfIndcrIndcrOutChks 15;
BA_ "GenSigDataID" SG_ 538 ActvnOfIndcrIndcrOutChks "0x9E";
BA_ "GenSigSendType" SG_ 538 ActvnOfIndcrIndcrOutCntr 0;
BA_ "GenSigFuncType" SG_ 538 ActvnOfIndcrIndcrOutCntr 16;
BA_ "GenSigStartValue" SG_ 538 EmgyBrkLiIndcrTurn 1;
BA_ "GenSigSendType" SG_ 538 EmgyBrkLiIndcrTurn 0;
BA_ "GenSigSendType" SG_ 538 IndcrPatCmd1WdTiOff 0;
BA_ "GenSigSendType" SG_ 538 IndcrPatCmd1WdTiOn 0;
BA_ "GenSigSendType" SG_ 538 IndcrSts 0;
// Frame: CemBodyExpoFr52
BA_ "GenMsgSendType" BO_ 326 1;
BA_ "GenMsgDelayTime" BO_ 326 30.000;
BA_ "GenSigSendType" SG_ 326 DwnLoadDynLitPrmForLedLogoLampContTiPrm 1;
BA_ "GenSigSendType" SG_ 326 DwnLoadDynLitPrmForLedLogoLampLowBriPrm 1;
BA_ "GenSigSendType" SG_ 326 DwnLoadDynLitPrmForLedLogoLampModePrm 1;
BA_ "GenSigSendType" SG_ 326 DwnLoadDynLitPrmForLedLogoLampOffsTiPrm 1;
BA_ "GenSigSendType" SG_ 326 DwnLoadDynLitPrmForLedLogoLampTistamp 1;
BA_ "GenSigSendType" SG_ 326 DwnLoadDynLitPrmForLedLogoLampUpprBriPrm 1;
// Frame: CemBodyExpoFr53
BA_ "GenMsgSendType" BO_ 327 1;
BA_ "GenMsgDelayTime" BO_ 327 30.000;
BA_ "GenSigSendType" SG_ 327 DwnLoadDynLitPrmLedRePosnLampLe3ContTiPrm 1;
BA_ "SigGroup" SG_ 327 DwnLoadDynLitPrmLedRePosnLampLe3ContTiPrm "DwnLoadDynLitPrmLedRePosnLampLe3";
BA_ "GenSigSendType" SG_ 327 DwnLoadDynLitPrmLedRePosnLampLe3LowBriPrm 1;
BA_ "SigGroup" SG_ 327 DwnLoadDynLitPrmLedRePosnLampLe3LowBriPrm "DwnLoadDynLitPrmLedRePosnLampLe3";
BA_ "GenSigSendType" SG_ 327 DwnLoadDynLitPrmLedRePosnLampLe3ModePrm 1;
BA_ "SigGroup" SG_ 327 DwnLoadDynLitPrmLedRePosnLampLe3ModePrm "DwnLoadDynLitPrmLedRePosnLampLe3";
BA_ "GenSigSendType" SG_ 327 DwnLoadDynLitPrmLedRePosnLampLe3OffsTiPrm 1;
BA_ "SigGroup" SG_ 327 DwnLoadDynLitPrmLedRePosnLampLe3OffsTiPrm "DwnLoadDynLitPrmLedRePosnLampLe3";
BA_ "GenSigSendType" SG_ 327 DwnLoadDynLitPrmLedRePosnLampLe3Tistamp 1;
BA_ "SigGroup" SG_ 327 DwnLoadDynLitPrmLedRePosnLampLe3Tistamp "DwnLoadDynLitPrmLedRePosnLampLe3";
BA_ "GenSigSendType" SG_ 327 DwnLoadDynLitPrmLedRePosnLampLe3UpprBriPrm 1;
BA_ "SigGroup" SG_ 327 DwnLoadDynLitPrmLedRePosnLampLe3UpprBriPrm "DwnLoadDynLitPrmLedRePosnLampLe3";
// Frame: CemBodyExpoFr54
BA_ "GenMsgSendType" BO_ 328 1;
BA_ "GenMsgDelayTime" BO_ 328 30.000;
BA_ "GenSigSendType" SG_ 328 DwnLoadDynLitPrmLedRePosnLampLe4ContTiPrm 1;
BA_ "SigGroup" SG_ 328 DwnLoadDynLitPrmLedRePosnLampLe4ContTiPrm "DwnLoadDynLitPrmLedRePosnLampLe4";
BA_ "GenSigSendType" SG_ 328 DwnLoadDynLitPrmLedRePosnLampLe4LowBriPrm 1;
BA_ "SigGroup" SG_ 328 DwnLoadDynLitPrmLedRePosnLampLe4LowBriPrm "DwnLoadDynLitPrmLedRePosnLampLe4";
BA_ "GenSigSendType" SG_ 328 DwnLoadDynLitPrmLedRePosnLampLe4ModePrm 1;
BA_ "SigGroup" SG_ 328 DwnLoadDynLitPrmLedRePosnLampLe4ModePrm "DwnLoadDynLitPrmLedRePosnLampLe4";
BA_ "GenSigSendType" SG_ 328 DwnLoadDynLitPrmLedRePosnLampLe4OffsTiPrm 1;
BA_ "SigGroup" SG_ 328 DwnLoadDynLitPrmLedRePosnLampLe4OffsTiPrm "DwnLoadDynLitPrmLedRePosnLampLe4";
BA_ "GenSigSendType" SG_ 328 DwnLoadDynLitPrmLedRePosnLampLe4Tistamp 1;
BA_ "SigGroup" SG_ 328 DwnLoadDynLitPrmLedRePosnLampLe4Tistamp "DwnLoadDynLitPrmLedRePosnLampLe4";
BA_ "GenSigSendType" SG_ 328 DwnLoadDynLitPrmLedRePosnLampLe4UpprBriPrm 1;
BA_ "SigGroup" SG_ 328 DwnLoadDynLitPrmLedRePosnLampLe4UpprBriPrm "DwnLoadDynLitPrmLedRePosnLampLe4";
// Frame: CemBodyExpoFr55
BA_ "GenMsgSendType" BO_ 329 1;
BA_ "GenMsgDelayTime" BO_ 329 30.000;
BA_ "GenSigSendType" SG_ 329 DwnLoadDynLitPrmLedRePosnLampLe5ContTiPrm 1;
BA_ "SigGroup" SG_ 329 DwnLoadDynLitPrmLedRePosnLampLe5ContTiPrm "DwnLoadDynLitPrmLedRePosnLampLe5";
BA_ "GenSigSendType" SG_ 329 DwnLoadDynLitPrmLedRePosnLampLe5LowBriPrm 1;
BA_ "SigGroup" SG_ 329 DwnLoadDynLitPrmLedRePosnLampLe5LowBriPrm "DwnLoadDynLitPrmLedRePosnLampLe5";
BA_ "GenSigSendType" SG_ 329 DwnLoadDynLitPrmLedRePosnLampLe5ModePrm 1;
BA_ "SigGroup" SG_ 329 DwnLoadDynLitPrmLedRePosnLampLe5ModePrm "DwnLoadDynLitPrmLedRePosnLampLe5";
BA_ "GenSigSendType" SG_ 329 DwnLoadDynLitPrmLedRePosnLampLe5OffsTiPrm 1;
BA_ "SigGroup" SG_ 329 DwnLoadDynLitPrmLedRePosnLampLe5OffsTiPrm "DwnLoadDynLitPrmLedRePosnLampLe5";
BA_ "GenSigSendType" SG_ 329 DwnLoadDynLitPrmLedRePosnLampLe5Tistamp 1;
BA_ "SigGroup" SG_ 329 DwnLoadDynLitPrmLedRePosnLampLe5Tistamp "DwnLoadDynLitPrmLedRePosnLampLe5";
BA_ "GenSigSendType" SG_ 329 DwnLoadDynLitPrmLedRePosnLampLe5UpprBriPrm 1;
BA_ "SigGroup" SG_ 329 DwnLoadDynLitPrmLedRePosnLampLe5UpprBriPrm "DwnLoadDynLitPrmLedRePosnLampLe5";
// Frame: CemBodyExpoFr56
BA_ "GenMsgSendType" BO_ 330 1;
BA_ "GenMsgDelayTime" BO_ 330 30.000;
BA_ "GenSigSendType" SG_ 330 DwnLoadDynLitPrmLedRePosnLampRi3ContTiPrm 1;
BA_ "SigGroup" SG_ 330 DwnLoadDynLitPrmLedRePosnLampRi3ContTiPrm "DwnLoadDynLitPrmLedRePosnLampRi3";
BA_ "GenSigSendType" SG_ 330 DwnLoadDynLitPrmLedRePosnLampRi3LowBriPrm 1;
BA_ "SigGroup" SG_ 330 DwnLoadDynLitPrmLedRePosnLampRi3LowBriPrm "DwnLoadDynLitPrmLedRePosnLampRi3";
BA_ "GenSigSendType" SG_ 330 DwnLoadDynLitPrmLedRePosnLampRi3ModePrm 1;
BA_ "SigGroup" SG_ 330 DwnLoadDynLitPrmLedRePosnLampRi3ModePrm "DwnLoadDynLitPrmLedRePosnLampRi3";
BA_ "GenSigSendType" SG_ 330 DwnLoadDynLitPrmLedRePosnLampRi3OffsTiPrm 1;
BA_ "SigGroup" SG_ 330 DwnLoadDynLitPrmLedRePosnLampRi3OffsTiPrm "DwnLoadDynLitPrmLedRePosnLampRi3";
BA_ "GenSigSendType" SG_ 330 DwnLoadDynLitPrmLedRePosnLampRi3Tistamp 1;
BA_ "SigGroup" SG_ 330 DwnLoadDynLitPrmLedRePosnLampRi3Tistamp "DwnLoadDynLitPrmLedRePosnLampRi3";
BA_ "GenSigSendType" SG_ 330 DwnLoadDynLitPrmLedRePosnLampRi3UpprBriPrm 1;
BA_ "SigGroup" SG_ 330 DwnLoadDynLitPrmLedRePosnLampRi3UpprBriPrm "DwnLoadDynLitPrmLedRePosnLampRi3";
// Frame: CemBodyExpoFr57
BA_ "GenMsgSendType" BO_ 331 1;
BA_ "GenMsgDelayTime" BO_ 331 30.000;
BA_ "GenSigSendType" SG_ 331 DwnLoadDynLitPrmLedRePosnLampRi4ContTiPrm 1;
BA_ "SigGroup" SG_ 331 DwnLoadDynLitPrmLedRePosnLampRi4ContTiPrm "DwnLoadDynLitPrmLedRePosnLampRi4";
BA_ "GenSigSendType" SG_ 331 DwnLoadDynLitPrmLedRePosnLampRi4LowBriPrm 1;
BA_ "SigGroup" SG_ 331 DwnLoadDynLitPrmLedRePosnLampRi4LowBriPrm "DwnLoadDynLitPrmLedRePosnLampRi4";
BA_ "GenSigSendType" SG_ 331 DwnLoadDynLitPrmLedRePosnLampRi4ModePrm 1;
BA_ "SigGroup" SG_ 331 DwnLoadDynLitPrmLedRePosnLampRi4ModePrm "DwnLoadDynLitPrmLedRePosnLampRi4";
BA_ "GenSigSendType" SG_ 331 DwnLoadDynLitPrmLedRePosnLampRi4OffsTiPrm 1;
BA_ "SigGroup" SG_ 331 DwnLoadDynLitPrmLedRePosnLampRi4OffsTiPrm "DwnLoadDynLitPrmLedRePosnLampRi4";
BA_ "GenSigSendType" SG_ 331 DwnLoadDynLitPrmLedRePosnLampRi4Tistamp 1;
BA_ "SigGroup" SG_ 331 DwnLoadDynLitPrmLedRePosnLampRi4Tistamp "DwnLoadDynLitPrmLedRePosnLampRi4";
BA_ "GenSigSendType" SG_ 331 DwnLoadDynLitPrmLedRePosnLampRi4UpprBriPrm 1;
BA_ "SigGroup" SG_ 331 DwnLoadDynLitPrmLedRePosnLampRi4UpprBriPrm "DwnLoadDynLitPrmLedRePosnLampRi4";
// Frame: CemBodyExpoFr58
BA_ "GenMsgSendType" BO_ 332 1;
BA_ "GenMsgDelayTime" BO_ 332 30.000;
BA_ "GenSigSendType" SG_ 332 DwnLoadDynLitPrmLedRePosnLampRi5ContTiPrm 1;
BA_ "SigGroup" SG_ 332 DwnLoadDynLitPrmLedRePosnLampRi5ContTiPrm "DwnLoadDynLitPrmLedRePosnLampRi5";
BA_ "GenSigSendType" SG_ 332 DwnLoadDynLitPrmLedRePosnLampRi5LowBriPrm 1;
BA_ "SigGroup" SG_ 332 DwnLoadDynLitPrmLedRePosnLampRi5LowBriPrm "DwnLoadDynLitPrmLedRePosnLampRi5";
BA_ "GenSigSendType" SG_ 332 DwnLoadDynLitPrmLedRePosnLampRi5ModePrm 1;
BA_ "SigGroup" SG_ 332 DwnLoadDynLitPrmLedRePosnLampRi5ModePrm "DwnLoadDynLitPrmLedRePosnLampRi5";
BA_ "GenSigSendType" SG_ 332 DwnLoadDynLitPrmLedRePosnLampRi5OffsTiPrm 1;
BA_ "SigGroup" SG_ 332 DwnLoadDynLitPrmLedRePosnLampRi5OffsTiPrm "DwnLoadDynLitPrmLedRePosnLampRi5";
BA_ "GenSigSendType" SG_ 332 DwnLoadDynLitPrmLedRePosnLampRi5Tistamp 1;
BA_ "SigGroup" SG_ 332 DwnLoadDynLitPrmLedRePosnLampRi5Tistamp "DwnLoadDynLitPrmLedRePosnLampRi5";
BA_ "GenSigSendType" SG_ 332 DwnLoadDynLitPrmLedRePosnLampRi5UpprBriPrm 1;
BA_ "SigGroup" SG_ 332 DwnLoadDynLitPrmLedRePosnLampRi5UpprBriPrm "DwnLoadDynLitPrmLedRePosnLampRi5";
// Frame: CemBodyExpoFr59
BA_ "GenMsgSendType" BO_ 24 0;
BA_ "GenMsgCycleTime" BO_ 24 15.000;
BA_ "GenSigSendType" SG_ 24 WelcomeGoodbyeModeReq 0;
// Frame: CemBodyExpoFr60
BA_ "GenMsgSendType" BO_ 333 1;
BA_ "GenMsgDelayTime" BO_ 333 30.000;
BA_ "GenSigSendType" SG_ 333 DwnLoadDynLitPrmLedLeGrilleLampContTiPrm 1;
BA_ "GenSigSendType" SG_ 333 DwnLoadDynLitPrmLedLeGrilleLampLowBriPrm 1;
BA_ "GenSigSendType" SG_ 333 DwnLoadDynLitPrmLedLeGrilleLampModePrm 1;
BA_ "GenSigSendType" SG_ 333 DwnLoadDynLitPrmLedLeGrilleLampOffsTiPrm 1;
BA_ "GenSigSendType" SG_ 333 DwnLoadDynLitPrmLedLeGrilleLampTistamp 1;
BA_ "GenSigSendType" SG_ 333 DwnLoadDynLitPrmLedLeGrilleLampUpprBriPrm 1;
// Frame: CemBodyExpoFr61
BA_ "GenMsgSendType" BO_ 334 1;
BA_ "GenMsgDelayTime" BO_ 334 30.000;
BA_ "GenSigSendType" SG_ 334 DwnLoadDynLitPrmLedRiGrilleLampContTiPrm 1;
BA_ "GenSigSendType" SG_ 334 DwnLoadDynLitPrmLedRiGrilleLampLowBriPrm 1;
BA_ "GenSigSendType" SG_ 334 DwnLoadDynLitPrmLedRiGrilleLampModePrm 1;
BA_ "GenSigSendType" SG_ 334 DwnLoadDynLitPrmLedRiGrilleLampOffsTiPrm 1;
BA_ "GenSigSendType" SG_ 334 DwnLoadDynLitPrmLedRiGrilleLampTistamp 1;
BA_ "GenSigSendType" SG_ 334 DwnLoadDynLitPrmLedRiGrilleLampUpprBriPrm 1;
// Frame: CemBodyExpoFr62
BA_ "GenMsgSendType" BO_ 788 1;
BA_ "GenMsgDelayTime" BO_ 788 150.000;
BA_ "GenSigSendType" SG_ 788 DHUcontrolLedMkrLampLe1 1;
BA_ "GenSigSendType" SG_ 788 DHUcontrolLedMkrLampLe2 1;
BA_ "GenSigSendType" SG_ 788 DHUcontrolLedMkrLampRi1 1;
BA_ "GenSigSendType" SG_ 788 DHUcontrolLedMkrLampRi2 1;
BA_ "GenSigSendType" SG_ 788 DHUcontrolLedStopLampLe1 1;
BA_ "GenSigSendType" SG_ 788 DHUcontrolLedStopLampLe2 1;
BA_ "GenSigSendType" SG_ 788 DHUcontrolLedStopLampRi1 1;
BA_ "GenSigSendType" SG_ 788 DHUcontrolLedStopLampRi2 1;
BA_ "GenSigSendType" SG_ 788 DHUcontrolmiddlebrakelight 1;
BA_ "GenSigSendType" SG_ 788 DHUcontrolmiddlecorneringlamp 1;
BA_ "GenSigSendType" SG_ 788 DHUcontrolmiddlepositionlight 1;
// Frame: CemBodyExpoFr63
BA_ "GenMsgSendType" BO_ 789 1;
BA_ "GenMsgDelayTime" BO_ 789 150.000;
BA_ "GenSigSendType" SG_ 789 DHUcontrolCrossreversinglight 1;
BA_ "GenSigSendType" SG_ 789 DHUcontrolleftbrakelightLamp 1;
BA_ "GenSigSendType" SG_ 789 DHUcontrolleftcorneringlamp 1;
BA_ "GenSigSendType" SG_ 789 DHUcontrolleftdaytimerunninglamp 1;
BA_ "GenSigSendType" SG_ 789 DHUcontrolleftfroglight 1;
BA_ "GenSigSendType" SG_ 789 DHUcontrolleftheadcorneringlamp 1;
BA_ "GenSigSendType" SG_ 789 DHUcontrollefthighbeamlamp 1;
BA_ "GenSigSendType" SG_ 789 DHUcontrolleftlowbeamlamp 1;
BA_ "GenSigSendType" SG_ 789 DHUcontrolleftpositionlamp 1;
BA_ "GenSigSendType" SG_ 789 DHUcontrolleftpositionlight 1;
BA_ "GenSigSendType" SG_ 789 DHUcontrolrightbrakelight 1;
BA_ "GenSigSendType" SG_ 789 DHUcontrolrightcorneringlamp 1;
BA_ "GenSigSendType" SG_ 789 DHUcontrolrightdaytimerunninglamp 1;
BA_ "GenSigSendType" SG_ 789 DHUcontrolrightfroglight 1;
BA_ "GenSigSendType" SG_ 789 DHUcontrolrighthighbeamlamp 1;
BA_ "GenSigSendType" SG_ 789 DHUcontrolrightlowbeamlamp 1;
BA_ "GenSigSendType" SG_ 789 DHUcontrolrightpositionLamp 1;
BA_ "GenSigSendType" SG_ 789 DHUcontrolrightrearcorneringlamp 1;
BA_ "GenSigSendType" SG_ 789 DHUcontrolrightrearpositionLamp 1;
// Frame: CemToAllFuncBodyCanExposedDiagReqFrame
BA_ "GenMsgSendType" BO_ 2047 1;
BA_ "GenMsgDelayTime" BO_ 2047 5.000;
// Frame: CemToHcmlBodyCanExposedDiagReqFrame
BA_ "GenMsgSendType" BO_ 1971 1;
BA_ "GenMsgDelayTime" BO_ 1971 5.000;
// Frame: CemToHcmrBodyCanExposedDiagReqFrame
BA_ "GenMsgSendType" BO_ 1972 1;
BA_ "GenMsgDelayTime" BO_ 1972 5.000;
// Frame: CemToRcmlBodyCanExposedDiagReqFrame
BA_ "GenMsgSendType" BO_ 1973 1;
BA_ "GenMsgDelayTime" BO_ 1973 5.000;
// Frame: CemToRcmmBodyCanExposedDiagReqFrame
BA_ "GenMsgSendType" BO_ 1975 1;
BA_ "GenMsgDelayTime" BO_ 1975 5.000;
// Frame: CemToRcmrBodyCanExposedDiagReqFrame
BA_ "GenMsgSendType" BO_ 1974 1;
BA_ "GenMsgDelayTime" BO_ 1974 5.000;
// Frame: EtcToCemBodyExpoDevDiagFr03
BA_ "GenMsgSendType" BO_ 1425 1;
BA_ "GenMsgDelayTime" BO_ 1425 95.000;
BA_ "GenSigSendType" SG_ 1425 CEMdevelpsignalgroupreqFunctiondevpsignalgroup1 1;
BA_ "GenSigSendType" SG_ 1425 CEMdevelpsignalgroupreqFunctiondevpsignalgroup2 1;
BA_ "GenSigSendType" SG_ 1425 CEMdevelpsignalgroupreqFunctiondevpsignalgroup3 1;
BA_ "GenSigSendType" SG_ 1425 CEMdevelpsignalgroupreqFunctiondevpsignalgroup4 1;
BA_ "GenSigSendType" SG_ 1425 CEMdevelpsignalgroupreqFunctiondevpsignalgroup5 1;
BA_ "GenSigSendType" SG_ 1425 CEMdevelpsignalgroupreqFunctiondevpsignalgroup6 1;
BA_ "GenSigSendType" SG_ 1425 CEMdevelpsignalgroupreqFunctiondevpsignalgroup7 1;
BA_ "GenSigSendType" SG_ 1425 CEMdevelpsignalgroupreqFunctiondevpsignalgroup8 1;
// Frame: EtctoHcmlXCPFr01
BA_ "GenMsgSendType" BO_ 1430 1;
BA_ "GenMsgDelayTime" BO_ 1430 10.000;
// Frame: EtctoHcmrXCPFr01
BA_ "GenMsgSendType" BO_ 1428 1;
BA_ "GenMsgDelayTime" BO_ 1428 10.000;
// Frame: HcmlBodyExpoFr02
BA_ "GenMsgSendType" BO_ 593 0;
BA_ "GenMsgCycleTime" BO_ 593 50.000;
BA_ "GenSigSendType" SG_ 593 StsOfLedHiBeamLe 0;
BA_ "GenSigSendType" SG_ 593 StsOfLedLoBeamLe 0;
// Frame: HcmlBodyExpoFr04
BA_ "GenMsgSendType" BO_ 124 0;
BA_ "GenMsgCycleTime" BO_ 124 50.000;
BA_ "GenSigSendType" SG_ 124 DwnLoadStsFbOfHdlampLe 0;
BA_ "GenSigSendType" SG_ 124 ExtrLiShowActvnFrntLeFb 0;
BA_ "GenSigSendType" SG_ 124 HdlampLeInpSts1 0;
BA_ "GenSigSendType" SG_ 124 HdlampLeInpSts2 0;
BA_ "GenSigSendType" SG_ 124 StsOfAfsLe 0;
BA_ "GenSigSendType" SG_ 124 StsOfAhbcLe 0;
BA_ "GenSigSendType" SG_ 124 StsOfFrntSideMkrLampLe2 0;
BA_ "GenSigSendType" SG_ 124 StsOfLedCornrgLampLe 0;
BA_ "GenSigSendType" SG_ 124 StsOfLedDaytiRunngLampLe 0;
BA_ "GenSigSendType" SG_ 124 StsOfLedFrntFogLampLe 0;
BA_ "GenSigSendType" SG_ 124 StsOfLedFrntPosnLampLe 0;
BA_ "GenSigSendType" SG_ 124 StsOfLedFrntTurnIndcrLe 0;
BA_ "GenSigSendType" SG_ 124 StsOfLvlgLeChks 0;
BA_ "GenSigSendType" SG_ 124 StsOfLvlgLeCntr 0;
BA_ "GenSigSendType" SG_ 124 StsOfLvlgLeStsOfLvlgLe 0;
BA_ "GenSigSendType" SG_ 124 StsOfSwvlgLe 0;
BA_ "GenSigSendType" SG_ 124 StsOfTouristModLe 0;
// Frame: HcmlBodyExposedNMFr
BA_ "GenMsgSendType" BO_ 1329 1;
BA_ "GenMsgDelayTime" BO_ 1329 20.000;
BA_ "GenMsgILSupport" BO_ 1329 0;
BA_ "NmAsrMessage" BO_ 1329 1;
// Frame: HcmlToCemBodyCanExposedDiagResFrame
BA_ "GenMsgSendType" BO_ 1715 1;
BA_ "GenMsgDelayTime" BO_ 1715 5.000;
// Frame: HcmltoEtcXCPFr01
BA_ "GenMsgSendType" BO_ 1424 1;
BA_ "GenMsgDelayTime" BO_ 1424 10.000;
// Frame: HcmrBodyExpoFr02
BA_ "GenMsgSendType" BO_ 594 0;
BA_ "GenMsgCycleTime" BO_ 594 50.000;
BA_ "GenSigSendType" SG_ 594 StsOfLedHiBeamRi 0;
BA_ "GenSigSendType" SG_ 594 StsOfLedLoBeamRi 0;
// Frame: HcmrBodyExpoFr04
BA_ "GenMsgSendType" BO_ 127 0;
BA_ "GenMsgCycleTime" BO_ 127 50.000;
BA_ "GenSigSendType" SG_ 127 DwnLoadStsFbOfHdlampRi 0;
BA_ "GenSigSendType" SG_ 127 ExtrLiShowActvnFrntRiFb 0;
BA_ "GenSigSendType" SG_ 127 HdlampRiInpSts1 0;
BA_ "GenSigSendType" SG_ 127 HdlampRiInpSts2 0;
BA_ "GenSigSendType" SG_ 127 StsOfAfsRi 0;
BA_ "GenSigSendType" SG_ 127 StsOfAhbcRi 0;
BA_ "GenSigSendType" SG_ 127 StsOfFrntSideMkrLampRi2 0;
BA_ "GenSigSendType" SG_ 127 StsOfLedCornrgLampRi 0;
BA_ "GenSigSendType" SG_ 127 StsOfLedDaytiRunngLampRi 0;
BA_ "GenSigSendType" SG_ 127 StsOfLedFrntFogLampRi 0;
BA_ "GenSigSendType" SG_ 127 StsOfLedFrntPosnLampRi 0;
BA_ "GenSigSendType" SG_ 127 StsOfLedFrntTurnIndcrRi 0;
BA_ "GenSigSendType" SG_ 127 StsOfLvlgRiChks 0;
BA_ "GenSigSendType" SG_ 127 StsOfLvlgRiCntr 0;
BA_ "GenSigSendType" SG_ 127 StsOfLvlgRiStsOfLvlgRi 0;
BA_ "GenSigSendType" SG_ 127 StsOfSwvlgRi 0;
BA_ "GenSigSendType" SG_ 127 StsOfTouristModRi 0;
// Frame: HcmrBodyExposedNMFr
BA_ "GenMsgSendType" BO_ 1330 1;
BA_ "GenMsgDelayTime" BO_ 1330 20.000;
BA_ "GenMsgILSupport" BO_ 1330 0;
BA_ "NmAsrMessage" BO_ 1330 1;
// Frame: HcmrToCemBodyCanExposedDiagResFrame
BA_ "GenMsgSendType" BO_ 1716 1;
BA_ "GenMsgDelayTime" BO_ 1716 5.000;
// Frame: HcmrtoEtcXCPFr01
BA_ "GenMsgSendType" BO_ 1426 1;
BA_ "GenMsgDelayTime" BO_ 1426 10.000;
// Frame: RcmlBodyExpoFr01
BA_ "GenMsgSendType" BO_ 592 0;
BA_ "GenMsgCycleTime" BO_ 592 50.000;
BA_ "GenSigSendType" SG_ 592 DwnLoadStsFbOfReLampCtrlLe1 0;
BA_ "GenSigSendType" SG_ 592 ExtrLiShowActvnReLeFb 0;
BA_ "GenSigSendType" SG_ 592 StsOfLedPosnLampLe1 0;
BA_ "GenSigSendType" SG_ 592 StsOfLedReFogLampLe1 0;
BA_ "GenSigSendType" SG_ 592 StsOfLedReLampLe1 0;
BA_ "GenSigSendType" SG_ 592 StsOfLedRvsgLampLe1 0;
BA_ "GenSigSendType" SG_ 592 StsOfLedStopLampLe1 0;
BA_ "GenSigSendType" SG_ 592 StsOfLedTurnIndcrLe1 0;
// Frame: RcmlBodyExposedNMFr
BA_ "GenMsgSendType" BO_ 1331 1;
BA_ "GenMsgDelayTime" BO_ 1331 20.000;
BA_ "GenMsgILSupport" BO_ 1331 0;
BA_ "NmAsrMessage" BO_ 1331 1;
// Frame: RcmlToCemBodyCanExposedDiagResFrame
BA_ "GenMsgSendType" BO_ 1717 1;
BA_ "GenMsgDelayTime" BO_ 1717 5.000;
// Frame: RcmmBodyExpoFr02
BA_ "GenMsgSendType" BO_ 596 0;
BA_ "GenMsgCycleTime" BO_ 596 50.000;
BA_ "GenSigSendType" SG_ 596 DwnLoadStsFbOfReLampCtrlLe2 0;
BA_ "GenSigSendType" SG_ 596 DwnLoadStsFbOfReLampCtrlRi2 0;
BA_ "GenSigSendType" SG_ 596 ExtrLiShowActvnReLe2Fb 0;
BA_ "GenSigSendType" SG_ 596 ExtrLiShowActvnReRi2Fb 0;
BA_ "GenSigSendType" SG_ 596 StsOfLedPosnLampLe2 0;
BA_ "GenSigSendType" SG_ 596 StsOfLedPosnLampRi2 0;
BA_ "GenSigSendType" SG_ 596 StsOfLedReFogLampLe2 0;
BA_ "GenSigSendType" SG_ 596 StsOfLedReFogLampRi2 0;
BA_ "GenSigSendType" SG_ 596 StsOfLedReLampLe2 0;
BA_ "GenSigSendType" SG_ 596 StsOfLedReLampRi2 0;
BA_ "GenSigSendType" SG_ 596 StsOfLedRvsgLampLe2 0;
BA_ "GenSigSendType" SG_ 596 StsOfLedRvsgLampRi2 0;
BA_ "GenSigSendType" SG_ 596 StsOfLedStopLampLe2 0;
BA_ "GenSigSendType" SG_ 596 StsOfLedStopLampRi2 0;
BA_ "GenSigSendType" SG_ 596 StsOfLedTurnIndcrLe2 0;
BA_ "GenSigSendType" SG_ 596 StsOfLedTurnIndcrRi2 0;
// Frame: RcmmBodyExposedNMFr
BA_ "GenMsgSendType" BO_ 1333 1;
BA_ "GenMsgDelayTime" BO_ 1333 20.000;
BA_ "GenMsgILSupport" BO_ 1333 0;
BA_ "NmAsrMessage" BO_ 1333 1;
// Frame: RcmmToCemBodyCanExposedDiagResFrame
BA_ "GenMsgSendType" BO_ 1719 1;
BA_ "GenMsgDelayTime" BO_ 1719 5.000;
// Frame: RcmrBodyExpoFr01
BA_ "GenMsgSendType" BO_ 608 0;
BA_ "GenMsgCycleTime" BO_ 608 50.000;
BA_ "GenSigSendType" SG_ 608 DwnLoadStsFbOfReLampCtrlRi1 0;
BA_ "GenSigSendType" SG_ 608 ExtrLiShowActvnReRiFb 0;
BA_ "GenSigSendType" SG_ 608 StsOfLedPosnLampRi1 0;
BA_ "GenSigSendType" SG_ 608 StsOfLedReFogLampRi1 0;
BA_ "GenSigSendType" SG_ 608 StsOfLedReLampRi1 0;
BA_ "GenSigSendType" SG_ 608 StsOfLedRvsgLampRi1 0;
BA_ "GenSigSendType" SG_ 608 StsOfLedStopLampRi1 0;
BA_ "GenSigSendType" SG_ 608 StsOfLedTurnIndcrRi1 0;
// Frame: RcmrBodyExposedNMFr
BA_ "GenMsgSendType" BO_ 1332 1;
BA_ "GenMsgDelayTime" BO_ 1332 20.000;
BA_ "GenMsgILSupport" BO_ 1332 0;
BA_ "NmAsrMessage" BO_ 1332 1;
// Frame: RcmrToCemBodyCanExposedDiagResFrame
BA_ "GenMsgSendType" BO_ 1718 1;
BA_ "GenMsgDelayTime" BO_ 1718 5.000;
VAL_ 312 DwnLoadDynLitPrmForLedLoBeamLeModePrm 0 "Mode1_Off" 1 "Mode1_On" 2 "Mode1_GradualOn" 3 "Mode1_GradualOff" 4 "Mode1_ForwardWipingOn" 5 "Mode1_BackwardWipingOn" 6 "Mode1_OutwardWipingOn" 7 "Mode1_InwardWipingOn" 8 "Mode1_ForwardWipingOff" 9 "Mode1_BackwardWipingOff" 10 "Mode1_OutwardWipingOff" 11 "Mode1_InwardWipingOff" 12 "Mode1_ForwardScanning" 13 "Mode1_BackwardScanning" 14 "Mode1_BreathOn" 15 "Mode1_BreathOff" 16 "Mode1_Spare1" 17 "Mode1_Spare2";
VAL_ 313 DwnLoadDynLtgPrmForLedAllWthrLampLeModePrm 0 "Mode1_Off" 1 "Mode1_On" 2 "Mode1_GradualOn" 3 "Mode1_GradualOff" 4 "Mode1_ForwardWipingOn" 5 "Mode1_BackwardWipingOn" 6 "Mode1_OutwardWipingOn" 7 "Mode1_InwardWipingOn" 8 "Mode1_ForwardWipingOff" 9 "Mode1_BackwardWipingOff" 10 "Mode1_OutwardWipingOff" 11 "Mode1_InwardWipingOff" 12 "Mode1_ForwardScanning" 13 "Mode1_BackwardScanning" 14 "Mode1_BreathOn" 15 "Mode1_BreathOff" 16 "Mode1_Spare1" 17 "Mode1_Spare2";
VAL_ 314 DwnLoadDynLtgPrmForLedAllWthrLampRiModePrm 0 "Mode1_Off" 1 "Mode1_On" 2 "Mode1_GradualOn" 3 "Mode1_GradualOff" 4 "Mode1_ForwardWipingOn" 5 "Mode1_BackwardWipingOn" 6 "Mode1_OutwardWipingOn" 7 "Mode1_InwardWipingOn" 8 "Mode1_ForwardWipingOff" 9 "Mode1_BackwardWipingOff" 10 "Mode1_OutwardWipingOff" 11 "Mode1_InwardWipingOff" 12 "Mode1_ForwardScanning" 13 "Mode1_BackwardScanning" 14 "Mode1_BreathOn" 15 "Mode1_BreathOff" 16 "Mode1_Spare1" 17 "Mode1_Spare2";
VAL_ 315 DwnLoadDynLtgPrmForLedCornrgLampLeModePrm 0 "Mode1_Off" 1 "Mode1_On" 2 "Mode1_GradualOn" 3 "Mode1_GradualOff" 4 "Mode1_ForwardWipingOn" 5 "Mode1_BackwardWipingOn" 6 "Mode1_OutwardWipingOn" 7 "Mode1_InwardWipingOn" 8 "Mode1_ForwardWipingOff" 9 "Mode1_BackwardWipingOff" 10 "Mode1_OutwardWipingOff" 11 "Mode1_InwardWipingOff" 12 "Mode1_ForwardScanning" 13 "Mode1_BackwardScanning" 14 "Mode1_BreathOn" 15 "Mode1_BreathOff" 16 "Mode1_Spare1" 17 "Mode1_Spare2";
VAL_ 316 DwnLoadDynLtgPrmForLedCornrgLampRiModePrm 0 "Mode1_Off" 1 "Mode1_On" 2 "Mode1_GradualOn" 3 "Mode1_GradualOff" 4 "Mode1_ForwardWipingOn" 5 "Mode1_BackwardWipingOn" 6 "Mode1_OutwardWipingOn" 7 "Mode1_InwardWipingOn" 8 "Mode1_ForwardWipingOff" 9 "Mode1_BackwardWipingOff" 10 "Mode1_OutwardWipingOff" 11 "Mode1_InwardWipingOff" 12 "Mode1_ForwardScanning" 13 "Mode1_BackwardScanning" 14 "Mode1_BreathOn" 15 "Mode1_BreathOff" 16 "Mode1_Spare1" 17 "Mode1_Spare2";
VAL_ 317 DwnLoadDynLtgPrmForLedDaytiRunngLampLeModePrm 0 "Mode1_Off" 1 "Mode1_On" 2 "Mode1_GradualOn" 3 "Mode1_GradualOff" 4 "Mode1_ForwardWipingOn" 5 "Mode1_BackwardWipingOn" 6 "Mode1_OutwardWipingOn" 7 "Mode1_InwardWipingOn" 8 "Mode1_ForwardWipingOff" 9 "Mode1_BackwardWipingOff" 10 "Mode1_OutwardWipingOff" 11 "Mode1_InwardWipingOff" 12 "Mode1_ForwardScanning" 13 "Mode1_BackwardScanning" 14 "Mode1_BreathOn" 15 "Mode1_BreathOff" 16 "Mode1_Spare1" 17 "Mode1_Spare2";
VAL_ 318 DwnLoadDynLtgPrmForLedDaytiRunngLampRiModePrm 0 "Mode1_Off" 1 "Mode1_On" 2 "Mode1_GradualOn" 3 "Mode1_GradualOff" 4 "Mode1_ForwardWipingOn" 5 "Mode1_BackwardWipingOn" 6 "Mode1_OutwardWipingOn" 7 "Mode1_InwardWipingOn" 8 "Mode1_ForwardWipingOff" 9 "Mode1_BackwardWipingOff" 10 "Mode1_OutwardWipingOff" 11 "Mode1_InwardWipingOff" 12 "Mode1_ForwardScanning" 13 "Mode1_BackwardScanning" 14 "Mode1_BreathOn" 15 "Mode1_BreathOff" 16 "Mode1_Spare1" 17 "Mode1_Spare2";
VAL_ 319 DwnLoadDynLtgPrmForLedFrntPosnLampLeModePrm 0 "Mode1_Off" 1 "Mode1_On" 2 "Mode1_GradualOn" 3 "Mode1_GradualOff" 4 "Mode1_ForwardWipingOn" 5 "Mode1_BackwardWipingOn" 6 "Mode1_OutwardWipingOn" 7 "Mode1_InwardWipingOn" 8 "Mode1_ForwardWipingOff" 9 "Mode1_BackwardWipingOff" 10 "Mode1_OutwardWipingOff" 11 "Mode1_InwardWipingOff" 12 "Mode1_ForwardScanning" 13 "Mode1_BackwardScanning" 14 "Mode1_BreathOn" 15 "Mode1_BreathOff" 16 "Mode1_Spare1" 17 "Mode1_Spare2";
VAL_ 320 DwnLoadDynLtgPrmForLedFrntPosnLampRiModePrm 0 "Mode1_Off" 1 "Mode1_On" 2 "Mode1_GradualOn" 3 "Mode1_GradualOff" 4 "Mode1_ForwardWipingOn" 5 "Mode1_BackwardWipingOn" 6 "Mode1_OutwardWipingOn" 7 "Mode1_InwardWipingOn" 8 "Mode1_ForwardWipingOff" 9 "Mode1_BackwardWipingOff" 10 "Mode1_OutwardWipingOff" 11 "Mode1_InwardWipingOff" 12 "Mode1_ForwardScanning" 13 "Mode1_BackwardScanning" 14 "Mode1_BreathOn" 15 "Mode1_BreathOff" 16 "Mode1_Spare1" 17 "Mode1_Spare2";
VAL_ 321 DwnLoadDynLtgPrmForLedFrntTurnIndcrLeModePrm 0 "Mode1_Off" 1 "Mode1_On" 2 "Mode1_GradualOn" 3 "Mode1_GradualOff" 4 "Mode1_ForwardWipingOn" 5 "Mode1_BackwardWipingOn" 6 "Mode1_OutwardWipingOn" 7 "Mode1_InwardWipingOn" 8 "Mode1_ForwardWipingOff" 9 "Mode1_BackwardWipingOff" 10 "Mode1_OutwardWipingOff" 11 "Mode1_InwardWipingOff" 12 "Mode1_ForwardScanning" 13 "Mode1_BackwardScanning" 14 "Mode1_BreathOn" 15 "Mode1_BreathOff" 16 "Mode1_Spare1" 17 "Mode1_Spare2";
VAL_ 322 DwnLoadDynLtgPrmForLedFrntTurnIndcrRiModePrm 0 "Mode1_Off" 1 "Mode1_On" 2 "Mode1_GradualOn" 3 "Mode1_GradualOff" 4 "Mode1_ForwardWipingOn" 5 "Mode1_BackwardWipingOn" 6 "Mode1_OutwardWipingOn" 7 "Mode1_InwardWipingOn" 8 "Mode1_ForwardWipingOff" 9 "Mode1_BackwardWipingOff" 10 "Mode1_OutwardWipingOff" 11 "Mode1_InwardWipingOff" 12 "Mode1_ForwardScanning" 13 "Mode1_BackwardScanning" 14 "Mode1_BreathOn" 15 "Mode1_BreathOff" 16 "Mode1_Spare1" 17 "Mode1_Spare2";
VAL_ 323 DwnLoadDynLtgPrmForLedHiBeamRiModePrm 0 "Mode1_Off" 1 "Mode1_On" 2 "Mode1_GradualOn" 3 "Mode1_GradualOff" 4 "Mode1_ForwardWipingOn" 5 "Mode1_BackwardWipingOn" 6 "Mode1_OutwardWipingOn" 7 "Mode1_InwardWipingOn" 8 "Mode1_ForwardWipingOff" 9 "Mode1_BackwardWipingOff" 10 "Mode1_OutwardWipingOff" 11 "Mode1_InwardWipingOff" 12 "Mode1_ForwardScanning" 13 "Mode1_BackwardScanning" 14 "Mode1_BreathOn" 15 "Mode1_BreathOff" 16 "Mode1_Spare1" 17 "Mode1_Spare2";
VAL_ 377 ADataRawSafeALat1Qf 0 "Qf1_DevOfDataUndefd" 1 "Qf1_DataTmpUndefdAndEvlnInProgs" 2 "Qf1_DevOfDataNotWithinRngAllwd" 3 "Qf1_DataCalcdWithDevDefd";
VAL_ 377 ADataRawSafeALgt1Qf 0 "Qf1_DevOfDataUndefd" 1 "Qf1_DataTmpUndefdAndEvlnInProgs" 2 "Qf1_DevOfDataNotWithinRngAllwd" 3 "Qf1_DataCalcdWithDevDefd";
VAL_ 377 ADataRawSafeAVertQf 0 "Qf1_DevOfDataUndefd" 1 "Qf1_DataTmpUndefdAndEvlnInProgs" 2 "Qf1_DevOfDataNotWithinRngAllwd" 3 "Qf1_DataCalcdWithDevDefd";
VAL_ 381 ActnOfLedGrilleLampDyn 0 "OnOff1_Off" 1 "OnOff1_On";
VAL_ 381 ActnOfLedPosnLampDyn 0 "OnOff1_Off" 1 "OnOff1_On";
VAL_ 381 AgDataRawSafeRollRateQf 0 "Qf1_DevOfDataUndefd" 1 "Qf1_DataTmpUndefdAndEvlnInProgs" 2 "Qf1_DevOfDataNotWithinRngAllwd" 3 "Qf1_DataCalcdWithDevDefd";
VAL_ 381 AgDataRawSafeYawRateQf 0 "Qf1_DevOfDataUndefd" 1 "Qf1_DataTmpUndefdAndEvlnInProgs" 2 "Qf1_DevOfDataNotWithinRngAllwd" 3 "Qf1_DataCalcdWithDevDefd";
VAL_ 612 BrkPedlValQf 0 "GenQf1_UndefindDataAccur" 1 "GenQf1_TmpUndefdData" 2 "GenQf1_DataAccurNotWithinSpcn" 3 "GenQf1_AccurData";
VAL_ 612 LitArea 0 "NoYes1_No" 1 "NoYes1_Yes";
VAL_ 612 WipgInfoWipgSpdInfo 0 "WipgSpdInfo_Off" 1 "WipgSpdInfo_IntlLo" 2 "WipgSpdInfo_IntlHi" 3 "WipgSpdInfo_WipgSpd4045" 4 "WipgSpdInfo_WipgSpd4650" 5 "WipgSpdInfo_WipgSpd5155" 6 "WipgSpdInfo_WipgSpd5660" 7 "WipgSpdInfo_WiprErr";
VAL_ 612 WipgInfoWiprActv 0 "OnOff1_Off" 1 "OnOff1_On";
VAL_ 612 WipgInfoWiprInWipgAr 0 "OnOff1_Off" 1 "OnOff1_On";
VAL_ 324 DwnLoadDynLitPrmForLedMkrLampRi2ModePrm 0 "Mode1_Off" 1 "Mode1_On" 2 "Mode1_GradualOn" 3 "Mode1_GradualOff" 4 "Mode1_ForwardWipingOn" 5 "Mode1_BackwardWipingOn" 6 "Mode1_OutwardWipingOn" 7 "Mode1_InwardWipingOn" 8 "Mode1_ForwardWipingOff" 9 "Mode1_BackwardWipingOff" 10 "Mode1_OutwardWipingOff" 11 "Mode1_InwardWipingOff" 12 "Mode1_ForwardScanning" 13 "Mode1_BackwardScanning" 14 "Mode1_BreathOn" 15 "Mode1_BreathOff" 16 "Mode1_Spare1" 17 "Mode1_Spare2";
VAL_ 325 DwnLoadDynLitPrmLedRvsgLampRi2ModePrm 0 "Mode1_Off" 1 "Mode1_On" 2 "Mode1_GradualOn" 3 "Mode1_GradualOff" 4 "Mode1_ForwardWipingOn" 5 "Mode1_BackwardWipingOn" 6 "Mode1_OutwardWipingOn" 7 "Mode1_InwardWipingOn" 8 "Mode1_ForwardWipingOff" 9 "Mode1_BackwardWipingOff" 10 "Mode1_OutwardWipingOff" 11 "Mode1_InwardWipingOff" 12 "Mode1_ForwardScanning" 13 "Mode1_BackwardScanning" 14 "Mode1_BreathOn" 15 "Mode1_BreathOff" 16 "Mode1_Spare1" 17 "Mode1_Spare2";
VAL_ 522 ActnOfLedCornrgLampLe 0 "OnOff1_Off" 1 "OnOff1_On";
VAL_ 522 ActnOfLedCornrgLampRi 0 "OnOff1_Off" 1 "OnOff1_On";
VAL_ 522 ActnOfLedDaytiRunngLamp 0 "OnOff1_Off" 1 "OnOff1_On";
VAL_ 522 ActnOfLedFrntFogLamp 0 "OnOff1_Off" 1 "OnOff1_On";
VAL_ 522 ActnOfLedHiBeam 0 "OnOff1_Off" 1 "OnOff1_On";
VAL_ 522 ActnOfLedLoBeamActnOfLedLoBeam 0 "OnOff1_Off" 1 "OnOff1_On";
VAL_ 522 ActnOfLedPosnLamp 0 "OnOff1_Off" 1 "OnOff1_On";
VAL_ 522 ActnOfLedReFogLamp 0 "OnOff1_Off" 1 "OnOff1_On";
VAL_ 522 ActnOfLedRvsgLamp 0 "OnOff1_Off" 1 "OnOff1_On";
VAL_ 522 ActnOfLedStopLampActnOfLedStopLamp 0 "OnOff1_Off" 1 "OnOff1_On";
VAL_ 522 ActvnOfAfs 0 "OnOff1_Off" 1 "OnOff1_On";
VAL_ 522 ActvnOfAhbc 0 "OnOff1_Off" 1 "OnOff1_On";
VAL_ 522 ActvnOfAhl 0 "OnOff1_Off" 1 "OnOff1_On";
VAL_ 522 ActvnOfBrkLi 0 "OnOff1_Off" 1 "OnOff1_On";
VAL_ 522 ActvnOfDbl 0 "OnOff1_Off" 1 "OnOff1_On";
VAL_ 522 ActvnOfGoodByeLi 0 "OnOff1_Off" 1 "OnOff1_On";
VAL_ 522 ActvnOfTouristMod 0 "OnOff1_Off" 1 "OnOff1_On";
VAL_ 522 ActvnOfWelcomeLi 0 "OnOff1_Off" 1 "OnOff1_On";
VAL_ 538 ActvnOfIndcrIndcrOut 0 "IndcrSts1_Off" 1 "IndcrSts1_LeOn" 2 "IndcrSts1_RiOn" 3 "IndcrSts1_LeAndRiOn";
VAL_ 538 EmgyBrkLiIndcrTurn 0 "OnOffCrit1_NotVld1" 1 "OnOffCrit1_Off" 2 "OnOffCrit1_On" 3 "OnOffCrit1_NotVld2";
VAL_ 538 IndcrSts 0 "IndcrSts1_Off" 1 "IndcrSts1_LeOn" 2 "IndcrSts1_RiOn" 3 "IndcrSts1_LeAndRiOn";
VAL_ 326 DwnLoadDynLitPrmForLedLogoLampModePrm 0 "Mode1_Off" 1 "Mode1_On" 2 "Mode1_GradualOn" 3 "Mode1_GradualOff" 4 "Mode1_ForwardWipingOn" 5 "Mode1_BackwardWipingOn" 6 "Mode1_OutwardWipingOn" 7 "Mode1_InwardWipingOn" 8 "Mode1_ForwardWipingOff" 9 "Mode1_BackwardWipingOff" 10 "Mode1_OutwardWipingOff" 11 "Mode1_InwardWipingOff" 12 "Mode1_ForwardScanning" 13 "Mode1_BackwardScanning" 14 "Mode1_BreathOn" 15 "Mode1_BreathOff" 16 "Mode1_Spare1" 17 "Mode1_Spare2";
VAL_ 327 DwnLoadDynLitPrmLedRePosnLampLe3ModePrm 0 "Mode1_Off" 1 "Mode1_On" 2 "Mode1_GradualOn" 3 "Mode1_GradualOff" 4 "Mode1_ForwardWipingOn" 5 "Mode1_BackwardWipingOn" 6 "Mode1_OutwardWipingOn" 7 "Mode1_InwardWipingOn" 8 "Mode1_ForwardWipingOff" 9 "Mode1_BackwardWipingOff" 10 "Mode1_OutwardWipingOff" 11 "Mode1_InwardWipingOff" 12 "Mode1_ForwardScanning" 13 "Mode1_BackwardScanning" 14 "Mode1_BreathOn" 15 "Mode1_BreathOff" 16 "Mode1_Spare1" 17 "Mode1_Spare2";
VAL_ 328 DwnLoadDynLitPrmLedRePosnLampLe4ModePrm 0 "Mode1_Off" 1 "Mode1_On" 2 "Mode1_GradualOn" 3 "Mode1_GradualOff" 4 "Mode1_ForwardWipingOn" 5 "Mode1_BackwardWipingOn" 6 "Mode1_OutwardWipingOn" 7 "Mode1_InwardWipingOn" 8 "Mode1_ForwardWipingOff" 9 "Mode1_BackwardWipingOff" 10 "Mode1_OutwardWipingOff" 11 "Mode1_InwardWipingOff" 12 "Mode1_ForwardScanning" 13 "Mode1_BackwardScanning" 14 "Mode1_BreathOn" 15 "Mode1_BreathOff" 16 "Mode1_Spare1" 17 "Mode1_Spare2";
VAL_ 329 DwnLoadDynLitPrmLedRePosnLampLe5ModePrm 0 "Mode1_Off" 1 "Mode1_On" 2 "Mode1_GradualOn" 3 "Mode1_GradualOff" 4 "Mode1_ForwardWipingOn" 5 "Mode1_BackwardWipingOn" 6 "Mode1_OutwardWipingOn" 7 "Mode1_InwardWipingOn" 8 "Mode1_ForwardWipingOff" 9 "Mode1_BackwardWipingOff" 10 "Mode1_OutwardWipingOff" 11 "Mode1_InwardWipingOff" 12 "Mode1_ForwardScanning" 13 "Mode1_BackwardScanning" 14 "Mode1_BreathOn" 15 "Mode1_BreathOff" 16 "Mode1_Spare1" 17 "Mode1_Spare2";
VAL_ 330 DwnLoadDynLitPrmLedRePosnLampRi3ModePrm 0 "Mode1_Off" 1 "Mode1_On" 2 "Mode1_GradualOn" 3 "Mode1_GradualOff" 4 "Mode1_ForwardWipingOn" 5 "Mode1_BackwardWipingOn" 6 "Mode1_OutwardWipingOn" 7 "Mode1_InwardWipingOn" 8 "Mode1_ForwardWipingOff" 9 "Mode1_BackwardWipingOff" 10 "Mode1_OutwardWipingOff" 11 "Mode1_InwardWipingOff" 12 "Mode1_ForwardScanning" 13 "Mode1_BackwardScanning" 14 "Mode1_BreathOn" 15 "Mode1_BreathOff" 16 "Mode1_Spare1" 17 "Mode1_Spare2";
VAL_ 331 DwnLoadDynLitPrmLedRePosnLampRi4ModePrm 0 "Mode1_Off" 1 "Mode1_On" 2 "Mode1_GradualOn" 3 "Mode1_GradualOff" 4 "Mode1_ForwardWipingOn" 5 "Mode1_BackwardWipingOn" 6 "Mode1_OutwardWipingOn" 7 "Mode1_InwardWipingOn" 8 "Mode1_ForwardWipingOff" 9 "Mode1_BackwardWipingOff" 10 "Mode1_OutwardWipingOff" 11 "Mode1_InwardWipingOff" 12 "Mode1_ForwardScanning" 13 "Mode1_BackwardScanning" 14 "Mode1_BreathOn" 15 "Mode1_BreathOff" 16 "Mode1_Spare1" 17 "Mode1_Spare2";
VAL_ 332 DwnLoadDynLitPrmLedRePosnLampRi5ModePrm 0 "Mode1_Off" 1 "Mode1_On" 2 "Mode1_GradualOn" 3 "Mode1_GradualOff" 4 "Mode1_ForwardWipingOn" 5 "Mode1_BackwardWipingOn" 6 "Mode1_OutwardWipingOn" 7 "Mode1_InwardWipingOn" 8 "Mode1_ForwardWipingOff" 9 "Mode1_BackwardWipingOff" 10 "Mode1_OutwardWipingOff" 11 "Mode1_InwardWipingOff" 12 "Mode1_ForwardScanning" 13 "Mode1_BackwardScanning" 14 "Mode1_BreathOn" 15 "Mode1_BreathOff" 16 "Mode1_Spare1" 17 "Mode1_Spare2";
VAL_ 24 WelcomeGoodbyeModeReq 0 "ModeReq_Mode1" 1 "ModeReq_Mode2" 2 "ModeReq_Mode3" 3 "ModeReq_Mode4" 4 "ModeReq_Mode5" 5 "ModeReq_Mode6";
VAL_ 333 DwnLoadDynLitPrmLedLeGrilleLampModePrm 0 "Mode1_Off" 1 "Mode1_On" 2 "Mode1_GradualOn" 3 "Mode1_GradualOff" 4 "Mode1_ForwardWipingOn" 5 "Mode1_BackwardWipingOn" 6 "Mode1_OutwardWipingOn" 7 "Mode1_InwardWipingOn" 8 "Mode1_ForwardWipingOff" 9 "Mode1_BackwardWipingOff" 10 "Mode1_OutwardWipingOff" 11 "Mode1_InwardWipingOff" 12 "Mode1_ForwardScanning" 13 "Mode1_BackwardScanning" 14 "Mode1_BreathOn" 15 "Mode1_BreathOff" 16 "Mode1_Spare1" 17 "Mode1_Spare2";
VAL_ 334 DwnLoadDynLitPrmLedRiGrilleLampModePrm 0 "Mode1_Off" 1 "Mode1_On" 2 "Mode1_GradualOn" 3 "Mode1_GradualOff" 4 "Mode1_ForwardWipingOn" 5 "Mode1_BackwardWipingOn" 6 "Mode1_OutwardWipingOn" 7 "Mode1_InwardWipingOn" 8 "Mode1_ForwardWipingOff" 9 "Mode1_BackwardWipingOff" 10 "Mode1_OutwardWipingOff" 11 "Mode1_InwardWipingOff" 12 "Mode1_ForwardScanning" 13 "Mode1_BackwardScanning" 14 "Mode1_BreathOn" 15 "Mode1_BreathOff" 16 "Mode1_Spare1" 17 "Mode1_Spare2";
VAL_ 788 DHUcontrolLedMkrLampLe1 0 "OnOffNoReq_NoReq" 1 "OnOffNoReq_On" 2 "OnOffNoReq_Off";
VAL_ 788 DHUcontrolLedMkrLampLe2 0 "OnOffNoReq_NoReq" 1 "OnOffNoReq_On" 2 "OnOffNoReq_Off";
VAL_ 788 DHUcontrolLedMkrLampRi1 0 "OnOffNoReq_NoReq" 1 "OnOffNoReq_On" 2 "OnOffNoReq_Off";
VAL_ 788 DHUcontrolLedMkrLampRi2 0 "OnOffNoReq_NoReq" 1 "OnOffNoReq_On" 2 "OnOffNoReq_Off";
VAL_ 788 DHUcontrolLedStopLampLe1 0 "OnOffNoReq_NoReq" 1 "OnOffNoReq_On" 2 "OnOffNoReq_Off";
VAL_ 788 DHUcontrolLedStopLampLe2 0 "OnOffNoReq_NoReq" 1 "OnOffNoReq_On" 2 "OnOffNoReq_Off";
VAL_ 788 DHUcontrolLedStopLampRi1 0 "OnOffNoReq_NoReq" 1 "OnOffNoReq_On" 2 "OnOffNoReq_Off";
VAL_ 788 DHUcontrolLedStopLampRi2 0 "OnOffNoReq_NoReq" 1 "OnOffNoReq_On" 2 "OnOffNoReq_Off";
VAL_ 788 DHUcontrolmiddlebrakelight 0 "OnOffNoReq_NoReq" 1 "OnOffNoReq_On" 2 "OnOffNoReq_Off";
VAL_ 788 DHUcontrolmiddlecorneringlamp 0 "OnOffNoReq_NoReq" 1 "OnOffNoReq_On" 2 "OnOffNoReq_Off";
VAL_ 788 DHUcontrolmiddlepositionlight 0 "OnOffNoReq_NoReq" 1 "OnOffNoReq_On" 2 "OnOffNoReq_Off";
VAL_ 789 DHUcontrolCrossreversinglight 0 "OnOffNoReq_NoReq" 1 "OnOffNoReq_On" 2 "OnOffNoReq_Off";
VAL_ 789 DHUcontrolleftbrakelightLamp 0 "OnOffNoReq_NoReq" 1 "OnOffNoReq_On" 2 "OnOffNoReq_Off";
VAL_ 789 DHUcontrolleftcorneringlamp 0 "OnOffNoReq_NoReq" 1 "OnOffNoReq_On" 2 "OnOffNoReq_Off";
VAL_ 789 DHUcontrolleftdaytimerunninglamp 0 "OnOffNoReq_NoReq" 1 "OnOffNoReq_On" 2 "OnOffNoReq_Off";
VAL_ 789 DHUcontrolleftfroglight 0 "OnOffNoReq_NoReq" 1 "OnOffNoReq_On" 2 "OnOffNoReq_Off";
VAL_ 789 DHUcontrolleftheadcorneringlamp 0 "OnOffNoReq_NoReq" 1 "OnOffNoReq_On" 2 "OnOffNoReq_Off";
VAL_ 789 DHUcontrollefthighbeamlamp 0 "OnOffNoReq_NoReq" 1 "OnOffNoReq_On" 2 "OnOffNoReq_Off";
VAL_ 789 DHUcontrolleftlowbeamlamp 0 "OnOffNoReq_NoReq" 1 "OnOffNoReq_On" 2 "OnOffNoReq_Off";
VAL_ 789 DHUcontrolleftpositionlamp 0 "OnOffNoReq_NoReq" 1 "OnOffNoReq_On" 2 "OnOffNoReq_Off";
VAL_ 789 DHUcontrolleftpositionlight 0 "OnOffNoReq_NoReq" 1 "OnOffNoReq_On" 2 "OnOffNoReq_Off";
VAL_ 789 DHUcontrolrightbrakelight 0 "OnOffNoReq_NoReq" 1 "OnOffNoReq_On" 2 "OnOffNoReq_Off";
VAL_ 789 DHUcontrolrightcorneringlamp 0 "OnOffNoReq_NoReq" 1 "OnOffNoReq_On" 2 "OnOffNoReq_Off";
VAL_ 789 DHUcontrolrightdaytimerunninglamp 0 "OnOffNoReq_NoReq" 1 "OnOffNoReq_On" 2 "OnOffNoReq_Off";
VAL_ 789 DHUcontrolrightfroglight 0 "OnOffNoReq_NoReq" 1 "OnOffNoReq_On" 2 "OnOffNoReq_Off";
VAL_ 789 DHUcontrolrighthighbeamlamp 0 "OnOffNoReq_NoReq" 1 "OnOffNoReq_On" 2 "OnOffNoReq_Off";
VAL_ 789 DHUcontrolrightlowbeamlamp 0 "OnOffNoReq_NoReq" 1 "OnOffNoReq_On" 2 "OnOffNoReq_Off";
VAL_ 789 DHUcontrolrightpositionLamp 0 "OnOffNoReq_NoReq" 1 "OnOffNoReq_On" 2 "OnOffNoReq_Off";
VAL_ 789 DHUcontrolrightrearcorneringlamp 0 "OnOffNoReq_NoReq" 1 "OnOffNoReq_On" 2 "OnOffNoReq_Off";
VAL_ 789 DHUcontrolrightrearpositionLamp 0 "OnOffNoReq_NoReq" 1 "OnOffNoReq_On" 2 "OnOffNoReq_Off";
VAL_ 593 StsOfLedHiBeamLe 0 "DevSts4_Off" 1 "DevSts4_On" 2 "DevSts4_Err" 3 "DevSts4_Resd";
VAL_ 593 StsOfLedLoBeamLe 0 "DevSts4_Off" 1 "DevSts4_On" 2 "DevSts4_Err" 3 "DevSts4_Resd";
VAL_ 124 DwnLoadStsFbOfHdlampLe 0 "Sts_Resd" 1 "Sts_Err" 2 "Sts_CmplOk" 3 "Sts_InProgs";
VAL_ 124 ExtrLiShowActvnFrntLeFb 0 "Sts_Resd" 1 "Sts_Err" 2 "Sts_CmplOk" 3 "Sts_InProgs";
VAL_ 124 HdlampLeInpSts1 0 "Boolean_FALSE" 1 "Boolean_TRUE";
VAL_ 124 HdlampLeInpSts2 0 "Boolean_FALSE" 1 "Boolean_TRUE";
VAL_ 124 StsOfAfsLe 0 "DevSts4_Off" 1 "DevSts4_On" 2 "DevSts4_Err" 3 "DevSts4_Resd";
VAL_ 124 StsOfAhbcLe 0 "DevSts4_Off" 1 "DevSts4_On" 2 "DevSts4_Err" 3 "DevSts4_Resd";
VAL_ 124 StsOfFrntSideMkrLampLe2 0 "DevSts4_Off" 1 "DevSts4_On" 2 "DevSts4_Err" 3 "DevSts4_Resd";
VAL_ 124 StsOfLedCornrgLampLe 0 "DevSts4_Off" 1 "DevSts4_On" 2 "DevSts4_Err" 3 "DevSts4_Resd";
VAL_ 124 StsOfLedDaytiRunngLampLe 0 "DevSts4_Off" 1 "DevSts4_On" 2 "DevSts4_Err" 3 "DevSts4_Resd";
VAL_ 124 StsOfLedFrntFogLampLe 0 "DevSts4_Off" 1 "DevSts4_On" 2 "DevSts4_Err" 3 "DevSts4_Resd";
VAL_ 124 StsOfLedFrntPosnLampLe 0 "DevSts4_Off" 1 "DevSts4_On" 2 "DevSts4_Err" 3 "DevSts4_Resd";
VAL_ 124 StsOfLedFrntTurnIndcrLe 0 "DevSts4_Off" 1 "DevSts4_On" 2 "DevSts4_Err" 3 "DevSts4_Resd";
VAL_ 124 StsOfLvlgLeStsOfLvlgLe 0 "DevSts4_Off" 1 "DevSts4_On" 2 "DevSts4_Err" 3 "DevSts4_Resd";
VAL_ 124 StsOfSwvlgLe 0 "DevSts4_Off" 1 "DevSts4_On" 2 "DevSts4_Err" 3 "DevSts4_Resd";
VAL_ 124 StsOfTouristModLe 0 "DevSts4_Off" 1 "DevSts4_On" 2 "DevSts4_Err" 3 "DevSts4_Resd";
VAL_ 594 StsOfLedHiBeamRi 0 "DevSts4_Off" 1 "DevSts4_On" 2 "DevSts4_Err" 3 "DevSts4_Resd";
VAL_ 594 StsOfLedLoBeamRi 0 "DevSts4_Off" 1 "DevSts4_On" 2 "DevSts4_Err" 3 "DevSts4_Resd";
VAL_ 127 DwnLoadStsFbOfHdlampRi 0 "Sts_Resd" 1 "Sts_Err" 2 "Sts_CmplOk" 3 "Sts_InProgs";
VAL_ 127 ExtrLiShowActvnFrntRiFb 0 "Sts_Resd" 1 "Sts_Err" 2 "Sts_CmplOk" 3 "Sts_InProgs";
VAL_ 127 HdlampRiInpSts1 0 "Boolean_FALSE" 1 "Boolean_TRUE";
VAL_ 127 HdlampRiInpSts2 0 "Boolean_FALSE" 1 "Boolean_TRUE";
VAL_ 127 StsOfAfsRi 0 "DevSts4_Off" 1 "DevSts4_On" 2 "DevSts4_Err" 3 "DevSts4_Resd";
VAL_ 127 StsOfAhbcRi 0 "DevSts4_Off" 1 "DevSts4_On" 2 "DevSts4_Err" 3 "DevSts4_Resd";
VAL_ 127 StsOfFrntSideMkrLampRi2 0 "DevSts4_Off" 1 "DevSts4_On" 2 "DevSts4_Err" 3 "DevSts4_Resd";
VAL_ 127 StsOfLedCornrgLampRi 0 "DevSts4_Off" 1 "DevSts4_On" 2 "DevSts4_Err" 3 "DevSts4_Resd";
VAL_ 127 StsOfLedDaytiRunngLampRi 0 "DevSts4_Off" 1 "DevSts4_On" 2 "DevSts4_Err" 3 "DevSts4_Resd";
VAL_ 127 StsOfLedFrntFogLampRi 0 "DevSts4_Off" 1 "DevSts4_On" 2 "DevSts4_Err" 3 "DevSts4_Resd";
VAL_ 127 StsOfLedFrntPosnLampRi 0 "DevSts4_Off" 1 "DevSts4_On" 2 "DevSts4_Err" 3 "DevSts4_Resd";
VAL_ 127 StsOfLedFrntTurnIndcrRi 0 "DevSts4_Off" 1 "DevSts4_On" 2 "DevSts4_Err" 3 "DevSts4_Resd";
VAL_ 127 StsOfLvlgRiStsOfLvlgRi 0 "DevSts4_Off" 1 "DevSts4_On" 2 "DevSts4_Err" 3 "DevSts4_Resd";
VAL_ 127 StsOfSwvlgRi 0 "DevSts4_Off" 1 "DevSts4_On" 2 "DevSts4_Err" 3 "DevSts4_Resd";
VAL_ 127 StsOfTouristModRi 0 "DevSts4_Off" 1 "DevSts4_On" 2 "DevSts4_Err" 3 "DevSts4_Resd";
VAL_ 592 DwnLoadStsFbOfReLampCtrlLe1 0 "Sts_Resd" 1 "Sts_Err" 2 "Sts_CmplOk" 3 "Sts_InProgs";
VAL_ 592 ExtrLiShowActvnReLeFb 0 "Sts_Resd" 1 "Sts_Err" 2 "Sts_CmplOk" 3 "Sts_InProgs";
VAL_ 592 StsOfLedPosnLampLe1 0 "DevSts4_Off" 1 "DevSts4_On" 2 "DevSts4_Err" 3 "DevSts4_Resd";
VAL_ 592 StsOfLedReFogLampLe1 0 "DevSts4_Off" 1 "DevSts4_On" 2 "DevSts4_Err" 3 "DevSts4_Resd";
VAL_ 592 StsOfLedReLampLe1 0 "DevSts4_Off" 1 "DevSts4_On" 2 "DevSts4_Err" 3 "DevSts4_Resd";
VAL_ 592 StsOfLedRvsgLampLe1 0 "DevSts4_Off" 1 "DevSts4_On" 2 "DevSts4_Err" 3 "DevSts4_Resd";
VAL_ 592 StsOfLedStopLampLe1 0 "DevSts4_Off" 1 "DevSts4_On" 2 "DevSts4_Err" 3 "DevSts4_Resd";
VAL_ 592 StsOfLedTurnIndcrLe1 0 "DevSts4_Off" 1 "DevSts4_On" 2 "DevSts4_Err" 3 "DevSts4_Resd";
VAL_ 596 DwnLoadStsFbOfReLampCtrlLe2 0 "Sts_Resd" 1 "Sts_Err" 2 "Sts_CmplOk" 3 "Sts_InProgs";
VAL_ 596 DwnLoadStsFbOfReLampCtrlRi2 0 "Sts_Resd" 1 "Sts_Err" 2 "Sts_CmplOk" 3 "Sts_InProgs";
VAL_ 596 ExtrLiShowActvnReLe2Fb 0 "Sts_Resd" 1 "Sts_Err" 2 "Sts_CmplOk" 3 "Sts_InProgs";
VAL_ 596 ExtrLiShowActvnReRi2Fb 0 "Sts_Resd" 1 "Sts_Err" 2 "Sts_CmplOk" 3 "Sts_InProgs";
VAL_ 596 StsOfLedPosnLampLe2 0 "DevSts4_Off" 1 "DevSts4_On" 2 "DevSts4_Err" 3 "DevSts4_Resd";
VAL_ 596 StsOfLedPosnLampRi2 0 "DevSts4_Off" 1 "DevSts4_On" 2 "DevSts4_Err" 3 "DevSts4_Resd";
VAL_ 596 StsOfLedReFogLampLe2 0 "DevSts4_Off" 1 "DevSts4_On" 2 "DevSts4_Err" 3 "DevSts4_Resd";
VAL_ 596 StsOfLedReFogLampRi2 0 "DevSts4_Off" 1 "DevSts4_On" 2 "DevSts4_Err" 3 "DevSts4_Resd";
VAL_ 596 StsOfLedReLampLe2 0 "DevSts4_Off" 1 "DevSts4_On" 2 "DevSts4_Err" 3 "DevSts4_Resd";
VAL_ 596 StsOfLedReLampRi2 0 "DevSts4_Off" 1 "DevSts4_On" 2 "DevSts4_Err" 3 "DevSts4_Resd";
VAL_ 596 StsOfLedRvsgLampLe2 0 "DevSts4_Off" 1 "DevSts4_On" 2 "DevSts4_Err" 3 "DevSts4_Resd";
VAL_ 596 StsOfLedRvsgLampRi2 0 "DevSts4_Off" 1 "DevSts4_On" 2 "DevSts4_Err" 3 "DevSts4_Resd";
VAL_ 596 StsOfLedStopLampLe2 0 "DevSts4_Off" 1 "DevSts4_On" 2 "DevSts4_Err" 3 "DevSts4_Resd";
VAL_ 596 StsOfLedStopLampRi2 0 "DevSts4_Off" 1 "DevSts4_On" 2 "DevSts4_Err" 3 "DevSts4_Resd";
VAL_ 596 StsOfLedTurnIndcrLe2 0 "DevSts4_Off" 1 "DevSts4_On" 2 "DevSts4_Err" 3 "DevSts4_Resd";
VAL_ 596 StsOfLedTurnIndcrRi2 0 "DevSts4_Off" 1 "DevSts4_On" 2 "DevSts4_Err" 3 "DevSts4_Resd";
VAL_ 608 DwnLoadStsFbOfReLampCtrlRi1 0 "Sts_Resd" 1 "Sts_Err" 2 "Sts_CmplOk" 3 "Sts_InProgs";
VAL_ 608 ExtrLiShowActvnReRiFb 0 "Sts_Resd" 1 "Sts_Err" 2 "Sts_CmplOk" 3 "Sts_InProgs";
VAL_ 608 StsOfLedPosnLampRi1 0 "DevSts4_Off" 1 "DevSts4_On" 2 "DevSts4_Err" 3 "DevSts4_Resd";
VAL_ 608 StsOfLedReFogLampRi1 0 "DevSts4_Off" 1 "DevSts4_On" 2 "DevSts4_Err" 3 "DevSts4_Resd";
VAL_ 608 StsOfLedReLampRi1 0 "DevSts4_Off" 1 "DevSts4_On" 2 "DevSts4_Err" 3 "DevSts4_Resd";
VAL_ 608 StsOfLedRvsgLampRi1 0 "DevSts4_Off" 1 "DevSts4_On" 2 "DevSts4_Err" 3 "DevSts4_Resd";
VAL_ 608 StsOfLedStopLampRi1 0 "DevSts4_Off" 1 "DevSts4_On" 2 "DevSts4_Err" 3 "DevSts4_Resd";
VAL_ 608 StsOfLedTurnIndcrRi1 0 "DevSts4_Off" 1 "DevSts4_On" 2 "DevSts4_Err" 3 "DevSts4_Resd";
SIG_GROUP_ 522 ActnOfLedLoBeam 1 : ActnOfLedLoBeamActnOfLedLoBeam ActnOfLedLoBeamChks ActnOfLedLoBeamCntr;
SIG_GROUP_ 522 ActnOfLedStopLamp 1 : ActnOfLedStopLampActnOfLedStopLamp ActnOfLedStopLampChks ActnOfLedStopLampCntr;
SIG_GROUP_ 538 ActvnOfIndcr 1 : ActvnOfIndcrIndcrOut ActvnOfIndcrIndcrOutChks ActvnOfIndcrIndcrOutCntr;
SIG_GROUP_ 377 ADataRawSafe 1 : ADataRawSafeALat ADataRawSafeALat1Qf ADataRawSafeALgt ADataRawSafeALgt1Qf ADataRawSafeAVert ADataRawSafeAVertQf ADataRawSafeChks ADataRawSafeCntr;
SIG_GROUP_ 381 AgDataRawSafe 1 : AgDataRawSafeChks AgDataRawSafeCntr AgDataRawSafeRollRate AgDataRawSafeRollRateQf AgDataRawSafeYawRate AgDataRawSafeYawRateQf;
SIG_GROUP_ 612 BrkPedlVal 1 : BrkPedlValBrkPedlVal BrkPedlValQf;
SIG_GROUP_ 1425 CEMdevelpsignalgroupreq 1 : CEMdevelpsignalgroupreqFunctiondevpsignalgroup1 CEMdevelpsignalgroupreqFunctiondevpsignalgroup2 CEMdevelpsignalgroupreqFunctiondevpsignalgroup3 CEMdevelpsignalgroupreqFunctiondevpsignalgroup4 CEMdevelpsignalgroupreqFunctiondevpsignalgroup5 CEMdevelpsignalgroupreqFunctiondevpsignalgroup6 CEMdevelpsignalgroupreqFunctiondevpsignalgroup7 CEMdevelpsignalgroupreqFunctiondevpsignalgroup8;
SIG_GROUP_ 312 DwnLoadDynLitPrmForLedLoBeamLe 1 : DwnLoadDynLitPrmForLedLoBeamLeContTiPrm DwnLoadDynLitPrmForLedLoBeamLeLowBriPrm DwnLoadDynLitPrmForLedLoBeamLeModePrm DwnLoadDynLitPrmForLedLoBeamLeOffsTiPrm DwnLoadDynLitPrmForLedLoBeamLeTistamp DwnLoadDynLitPrmForLedLoBeamLeUpprBriPrm;
SIG_GROUP_ 326 DwnLoadDynLitPrmForLedLogoLamp 1 : DwnLoadDynLitPrmForLedLogoLampContTiPrm DwnLoadDynLitPrmForLedLogoLampLowBriPrm DwnLoadDynLitPrmForLedLogoLampModePrm DwnLoadDynLitPrmForLedLogoLampOffsTiPrm DwnLoadDynLitPrmForLedLogoLampTistamp DwnLoadDynLitPrmForLedLogoLampUpprBriPrm;
SIG_GROUP_ 324 DwnLoadDynLitPrmForLedMkrLampRi2 1 : DwnLoadDynLitPrmForLedMkrLampRi2ContTiPrm DwnLoadDynLitPrmForLedMkrLampRi2LowBriPrm DwnLoadDynLitPrmForLedMkrLampRi2ModePrm DwnLoadDynLitPrmForLedMkrLampRi2OffsTiPrm DwnLoadDynLitPrmForLedMkrLampRi2Tistamp DwnLoadDynLitPrmForLedMkrLampRi2UpprBriPrm;
SIG_GROUP_ 333 DwnLoadDynLitPrmLedLeGrilleLamp 1 : DwnLoadDynLitPrmLedLeGrilleLampContTiPrm DwnLoadDynLitPrmLedLeGrilleLampLowBriPrm DwnLoadDynLitPrmLedLeGrilleLampModePrm DwnLoadDynLitPrmLedLeGrilleLampOffsTiPrm DwnLoadDynLitPrmLedLeGrilleLampTistamp DwnLoadDynLitPrmLedLeGrilleLampUpprBriPrm;
SIG_GROUP_ 327 DwnLoadDynLitPrmLedRePosnLampLe3 1 : DwnLoadDynLitPrmLedRePosnLampLe3ContTiPrm DwnLoadDynLitPrmLedRePosnLampLe3LowBriPrm DwnLoadDynLitPrmLedRePosnLampLe3ModePrm DwnLoadDynLitPrmLedRePosnLampLe3OffsTiPrm DwnLoadDynLitPrmLedRePosnLampLe3Tistamp DwnLoadDynLitPrmLedRePosnLampLe3UpprBriPrm;
SIG_GROUP_ 328 DwnLoadDynLitPrmLedRePosnLampLe4 1 : DwnLoadDynLitPrmLedRePosnLampLe4ContTiPrm DwnLoadDynLitPrmLedRePosnLampLe4LowBriPrm DwnLoadDynLitPrmLedRePosnLampLe4ModePrm DwnLoadDynLitPrmLedRePosnLampLe4OffsTiPrm DwnLoadDynLitPrmLedRePosnLampLe4Tistamp DwnLoadDynLitPrmLedRePosnLampLe4UpprBriPrm;
SIG_GROUP_ 329 DwnLoadDynLitPrmLedRePosnLampLe5 1 : DwnLoadDynLitPrmLedRePosnLampLe5ContTiPrm DwnLoadDynLitPrmLedRePosnLampLe5LowBriPrm DwnLoadDynLitPrmLedRePosnLampLe5ModePrm DwnLoadDynLitPrmLedRePosnLampLe5OffsTiPrm DwnLoadDynLitPrmLedRePosnLampLe5Tistamp DwnLoadDynLitPrmLedRePosnLampLe5UpprBriPrm;
SIG_GROUP_ 330 DwnLoadDynLitPrmLedRePosnLampRi3 1 : DwnLoadDynLitPrmLedRePosnLampRi3ContTiPrm DwnLoadDynLitPrmLedRePosnLampRi3LowBriPrm DwnLoadDynLitPrmLedRePosnLampRi3ModePrm DwnLoadDynLitPrmLedRePosnLampRi3OffsTiPrm DwnLoadDynLitPrmLedRePosnLampRi3Tistamp DwnLoadDynLitPrmLedRePosnLampRi3UpprBriPrm;
SIG_GROUP_ 331 DwnLoadDynLitPrmLedRePosnLampRi4 1 : DwnLoadDynLitPrmLedRePosnLampRi4ContTiPrm DwnLoadDynLitPrmLedRePosnLampRi4LowBriPrm DwnLoadDynLitPrmLedRePosnLampRi4ModePrm DwnLoadDynLitPrmLedRePosnLampRi4OffsTiPrm DwnLoadDynLitPrmLedRePosnLampRi4Tistamp DwnLoadDynLitPrmLedRePosnLampRi4UpprBriPrm;
SIG_GROUP_ 332 DwnLoadDynLitPrmLedRePosnLampRi5 1 : DwnLoadDynLitPrmLedRePosnLampRi5ContTiPrm DwnLoadDynLitPrmLedRePosnLampRi5LowBriPrm DwnLoadDynLitPrmLedRePosnLampRi5ModePrm DwnLoadDynLitPrmLedRePosnLampRi5OffsTiPrm DwnLoadDynLitPrmLedRePosnLampRi5Tistamp DwnLoadDynLitPrmLedRePosnLampRi5UpprBriPrm;
SIG_GROUP_ 334 DwnLoadDynLitPrmLedRiGrilleLamp 1 : DwnLoadDynLitPrmLedRiGrilleLampContTiPrm DwnLoadDynLitPrmLedRiGrilleLampLowBriPrm DwnLoadDynLitPrmLedRiGrilleLampModePrm DwnLoadDynLitPrmLedRiGrilleLampOffsTiPrm DwnLoadDynLitPrmLedRiGrilleLampTistamp DwnLoadDynLitPrmLedRiGrilleLampUpprBriPrm;
SIG_GROUP_ 325 DwnLoadDynLitPrmLedRvsgLampRi2 1 : DwnLoadDynLitPrmLedRvsgLampRi2ContTiPrm DwnLoadDynLitPrmLedRvsgLampRi2LowBriPrm DwnLoadDynLitPrmLedRvsgLampRi2ModePrm DwnLoadDynLitPrmLedRvsgLampRi2OffsTiPrm DwnLoadDynLitPrmLedRvsgLampRi2Tistamp DwnLoadDynLitPrmLedRvsgLampRi2UpprBriPrm;
SIG_GROUP_ 313 DwnLoadDynLtgPrmForLedAllWthrLampLe 1 : DwnLoadDynLtgPrmForLedAllWthrLampLeContTiPrm DwnLoadDynLtgPrmForLedAllWthrLampLeLowBriPrm DwnLoadDynLtgPrmForLedAllWthrLampLeModePrm DwnLoadDynLtgPrmForLedAllWthrLampLeOffsTiPrm DwnLoadDynLtgPrmForLedAllWthrLampLeTistamp DwnLoadDynLtgPrmForLedAllWthrLampLeUpprBriPrm;
SIG_GROUP_ 314 DwnLoadDynLtgPrmForLedAllWthrLampRi 1 : DwnLoadDynLtgPrmForLedAllWthrLampRiContTiPrm DwnLoadDynLtgPrmForLedAllWthrLampRiLowBriPrm DwnLoadDynLtgPrmForLedAllWthrLampRiModePrm DwnLoadDynLtgPrmForLedAllWthrLampRiOffsTiPrm DwnLoadDynLtgPrmForLedAllWthrLampRiTistamp DwnLoadDynLtgPrmForLedAllWthrLampRiUpprBriPrm;
SIG_GROUP_ 315 DwnLoadDynLtgPrmForLedCornrgLampLe 1 : DwnLoadDynLtgPrmForLedCornrgLampLeContTiPrm DwnLoadDynLtgPrmForLedCornrgLampLeLowBriPrm DwnLoadDynLtgPrmForLedCornrgLampLeModePrm DwnLoadDynLtgPrmForLedCornrgLampLeOffsTiPrm DwnLoadDynLtgPrmForLedCornrgLampLeTistamp DwnLoadDynLtgPrmForLedCornrgLampLeUpprBriPrm;
SIG_GROUP_ 316 DwnLoadDynLtgPrmForLedCornrgLampRi 1 : DwnLoadDynLtgPrmForLedCornrgLampRiContTiPrm DwnLoadDynLtgPrmForLedCornrgLampRiLowBriPrm DwnLoadDynLtgPrmForLedCornrgLampRiModePrm DwnLoadDynLtgPrmForLedCornrgLampRiOffsTiPrm DwnLoadDynLtgPrmForLedCornrgLampRiTistamp DwnLoadDynLtgPrmForLedCornrgLampRiUpprBriPrm;
SIG_GROUP_ 317 DwnLoadDynLtgPrmForLedDaytiRunngLampLe 1 : DwnLoadDynLtgPrmForLedDaytiRunngLampLeContTiPrm DwnLoadDynLtgPrmForLedDaytiRunngLampLeLowBriPrm DwnLoadDynLtgPrmForLedDaytiRunngLampLeModePrm DwnLoadDynLtgPrmForLedDaytiRunngLampLeOffsTiPrm DwnLoadDynLtgPrmForLedDaytiRunngLampLeTistamp DwnLoadDynLtgPrmForLedDaytiRunngLampLeUpprBriPrm;
SIG_GROUP_ 318 DwnLoadDynLtgPrmForLedDaytiRunngLampRi 1 : DwnLoadDynLtgPrmForLedDaytiRunngLampRiContTiPrm DwnLoadDynLtgPrmForLedDaytiRunngLampRiLowBriPrm DwnLoadDynLtgPrmForLedDaytiRunngLampRiModePrm DwnLoadDynLtgPrmForLedDaytiRunngLampRiOffsTiPrm DwnLoadDynLtgPrmForLedDaytiRunngLampRiTistamp DwnLoadDynLtgPrmForLedDaytiRunngLampRiUpprBriPrm;
SIG_GROUP_ 319 DwnLoadDynLtgPrmForLedFrntPosnLampLe 1 : DwnLoadDynLtgPrmForLedFrntPosnLampLeContTiPrm DwnLoadDynLtgPrmForLedFrntPosnLampLeLowBriPrm DwnLoadDynLtgPrmForLedFrntPosnLampLeModePrm DwnLoadDynLtgPrmForLedFrntPosnLampLeOffsTiPrm DwnLoadDynLtgPrmForLedFrntPosnLampLeTistamp DwnLoadDynLtgPrmForLedFrntPosnLampLeUpprBriPrm;
SIG_GROUP_ 320 DwnLoadDynLtgPrmForLedFrntPosnLampRi 1 : DwnLoadDynLtgPrmForLedFrntPosnLampRiContTiPrm DwnLoadDynLtgPrmForLedFrntPosnLampRiLowBriPrm DwnLoadDynLtgPrmForLedFrntPosnLampRiModePrm DwnLoadDynLtgPrmForLedFrntPosnLampRiOffsTiPrm DwnLoadDynLtgPrmForLedFrntPosnLampRiTistamp DwnLoadDynLtgPrmForLedFrntPosnLampRiUpprBriPrm;
SIG_GROUP_ 321 DwnLoadDynLtgPrmForLedFrntTurnIndcrLe 1 : DwnLoadDynLtgPrmForLedFrntTurnIndcrLeContTiPrm DwnLoadDynLtgPrmForLedFrntTurnIndcrLeLowBriPrm DwnLoadDynLtgPrmForLedFrntTurnIndcrLeModePrm DwnLoadDynLtgPrmForLedFrntTurnIndcrLeOffsTiPrm DwnLoadDynLtgPrmForLedFrntTurnIndcrLeTistamp DwnLoadDynLtgPrmForLedFrntTurnIndcrLeUpprBriPrm;
SIG_GROUP_ 322 DwnLoadDynLtgPrmForLedFrntTurnIndcrRi 1 : DwnLoadDynLtgPrmForLedFrntTurnIndcrRiContTiPrm DwnLoadDynLtgPrmForLedFrntTurnIndcrRiLowBriPrm DwnLoadDynLtgPrmForLedFrntTurnIndcrRiModePrm DwnLoadDynLtgPrmForLedFrntTurnIndcrRiOffsTiPrm DwnLoadDynLtgPrmForLedFrntTurnIndcrRiTistamp DwnLoadDynLtgPrmForLedFrntTurnIndcrRiUpprBriPrm;
SIG_GROUP_ 323 DwnLoadDynLtgPrmForLedHiBeamRi 1 : DwnLoadDynLtgPrmForLedHiBeamRiContTiPrm DwnLoadDynLtgPrmForLedHiBeamRiLowBriPrm DwnLoadDynLtgPrmForLedHiBeamRiModePrm DwnLoadDynLtgPrmForLedHiBeamRiOffsTiPrm DwnLoadDynLtgPrmForLedHiBeamRiTistamp DwnLoadDynLtgPrmForLedHiBeamRiUpprBriPrm;
SIG_GROUP_ 538 IndcrPat 1 : IndcrPatCmd1WdTiOff IndcrPatCmd1WdTiOn;
SIG_GROUP_ 124 StsOfLvlgLe 1 : StsOfLvlgLeChks StsOfLvlgLeCntr StsOfLvlgLeStsOfLvlgLe;
SIG_GROUP_ 127 StsOfLvlgRi 1 : StsOfLvlgRiChks StsOfLvlgRiCntr StsOfLvlgRiStsOfLvlgRi;
SIG_GROUP_ 612 WipgInfo 1 : WipgInfoWipgSpdInfo WipgInfoWiprActv WipgInfoWiprInWipgAr;
